VERSION ""

NS_ :

BS_:

BU_: Server VCU Body Brakes

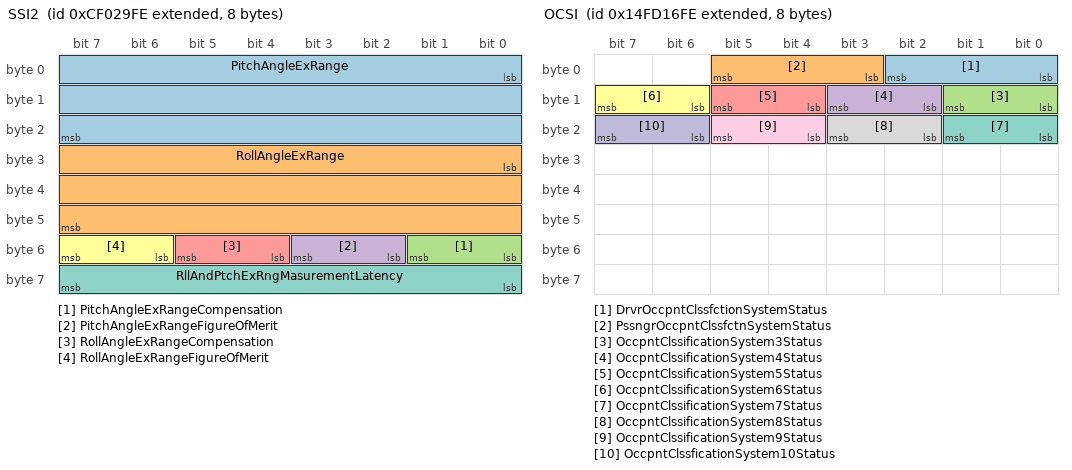
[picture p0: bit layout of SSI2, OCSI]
BO_ 2364549630 SSI2: 8 Vector__XXX
 SG_ PitchAngleExRange : 0|24@1+ (1,-250) [-250|251] "deg" Vector__XXX
 SG_ RollAngleExRange : 24|24@1+ (1,-250) [-250|251] "deg" Vector__XXX
 SG_ PitchAngleExRangeCompensation : 48|2@1+ (1,0) [0|3] "" Vector__XXX
 SG_ PitchAngleExRangeFigureOfMerit : 50|2@1+ (1,0) [0|3] "" Vector__XXX
 SG_ RollAngleExRangeCompensation : 52|2@1+ (1,0) [0|3] "" Vector__XXX
 SG_ RollAngleExRangeFigureOfMerit : 54|2@1+ (1,0) [0|3] "" Vector__XXX
 SG_ RllAndPtchExRngMasurementLatency : 56|8@1+ (0.5,0) [0|125] "ms" Vector__XXX

BO_ 2499614462 OCSI: 8 Vector__XXX
 SG_ DrvrOccpntClssfctionSystemStatus : 0|3@1+ (1,0) [0|7] "" Vector__XXX
 SG_ PssngrOccpntClssfctnSystemStatus : 3|3@1+ (1,0) [0|7] "" Vector__XXX
 SG_ OccpntClssificationSystem3Status : 8|2@1+ (1,0) [0|3] "" Vector__XXX
 SG_ OccpntClssificationSystem4Status : 10|2@1+ (1,0) [0|3] "" Vector__XXX
 SG_ OccpntClssificationSystem5Status : 12|2@1+ (1,0) [0|3] "" Vector__XXX
 SG_ OccpntClssificationSystem6Status : 14|2@1+ (1,0) [0|3] "" Vector__XXX
 SG_ OccpntClssificationSystem7Status : 16|2@1+ (1,0) [0|3] "" Vector__XXX
 SG_ OccpntClssificationSystem8Status : 18|2@1+ (1,0) [0|3] "" Vector__XXX
 SG_ OccpntClssificationSystem9Status : 20|2@1+ (1,0) [0|3] "" Vector__XXX
 SG_ OccpntClssficationSystem10Status : 22|2@1+ (1,0) [0|3] "" Vector__XXX

BO_ 2560098046 NCS: 8 Vector__XXX
 SG_ CabNoiseCtrlStatus : 0|2@1+ (1,0) [0|3] "" Vector__XXX
 SG_ CabNoiseCtrlTuningStatus : 2|4@1+ (1,0) [0|15] "" Vector__XXX

BO_ 2560163582 NC1: 8 Vector__XXX
 SG_ CabNoiseCtrlState : 0|2@1+ (1,0) [0|3] "" Vector__XXX
 SG_ CabNoiseCtrlTuningState : 2|3@1+ (1,0) [0|7] "" Vector__XXX

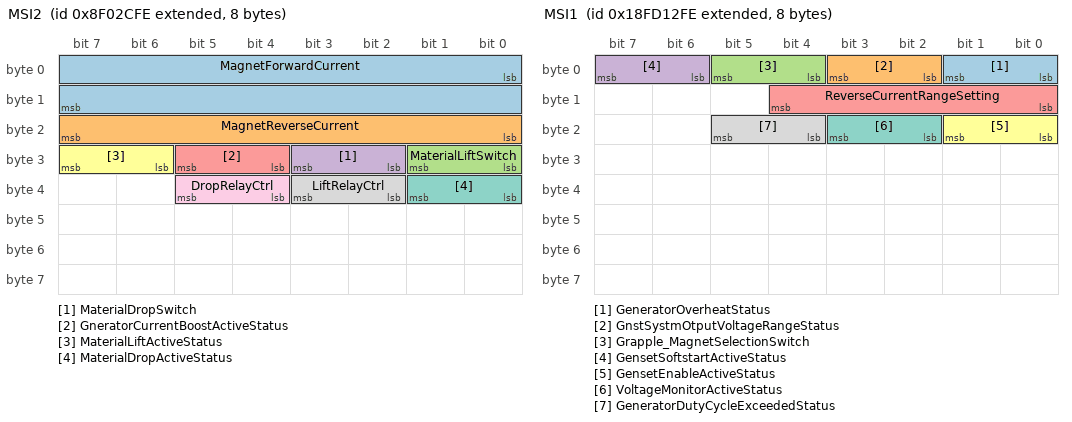
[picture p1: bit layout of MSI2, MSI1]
BO_ 2297441534 MSI2: 8 Vector__XXX
 SG_ MagnetForwardCurrent : 0|16@1+ (1,0) [0|64255] "Amps" Vector__XXX
 SG_ MagnetReverseCurrent : 16|8@1+ (1,0) [0|250] "A" Vector__XXX
 SG_ MaterialLiftSwitch : 24|2@1+ (1,0) [0|3] "" Vector__XXX
 SG_ MaterialDropSwitch : 26|2@1+ (1,0) [0|3] "" Vector__XXX
 SG_ GneratorCurrentBoostActiveStatus : 28|2@1+ (1,0) [0|3] "" Vector__XXX
 SG_ MaterialLiftActiveStatus : 30|2@1+ (1,0) [0|3] "" Vector__XXX
 SG_ MaterialDropActiveStatus : 32|2@1+ (1,0) [0|3] "" Vector__XXX
 SG_ LiftRelayCtrl : 34|2@1+ (1,0) [0|3] "" Vector__XXX
 SG_ DropRelayCtrl : 36|2@1+ (1,0) [0|3] "" Vector__XXX

BO_ 2566722302 MSI1: 8 Vector__XXX
 SG_ GeneratorOverheatStatus : 0|2@1+ (1,0) [0|3] "" Vector__XXX
 SG_ GnstSystmOtputVoltageRangeStatus : 2|2@1+ (1,0) [0|3] "" Vector__XXX
 SG_ Grapple_MagnetSelectionSwitch : 4|2@1+ (1,0) [0|3] "" Vector__XXX
 SG_ GensetSoftstartActiveStatus : 6|2@1+ (1,0) [0|3] "" Vector__XXX
 SG_ ReverseCurrentRangeSetting : 8|5@1+ (1,0) [0|31] "" Vector__XXX
 SG_ GensetEnableActiveStatus : 16|2@1+ (1,0) [0|3] "" Vector__XXX
 SG_ VoltageMonitorActiveStatus : 18|2@1+ (1,0) [0|3] "" Vector__XXX
 SG_ GeneratorDutyCycleExceededStatus : 20|2@1+ (1,0) [0|3] "" Vector__XXX

BO_ 2566722558 MSCI: 8 Vector__XXX
 SG_ MagnetBoostTime : 0|8@1+ (1,0) [0|63] "s" Vector__XXX
 SG_ MagnetRatedPower : 8|16@1+ (1,0) [0|32128] "kW" Vector__XXX

BO_ 2560032510 LVDSOM: 8 Vector__XXX
 SG_ LwVltgDscnnctDsiredOperatingMode : 0|4@1+ (1,0) [0|15] "" Vector__XXX

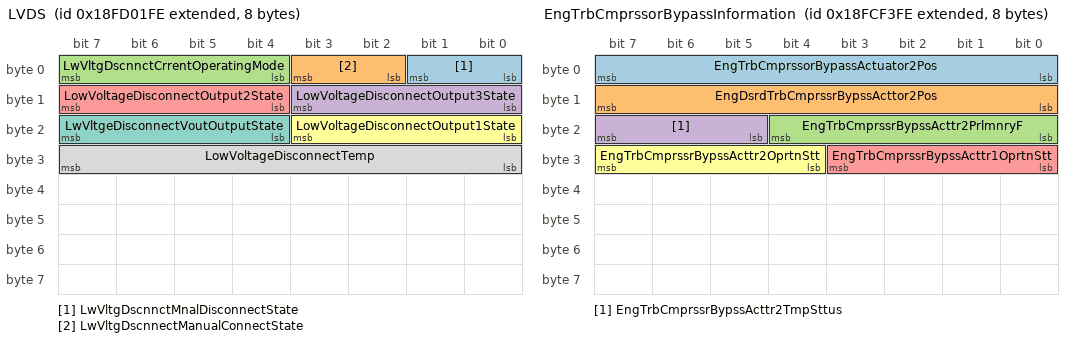
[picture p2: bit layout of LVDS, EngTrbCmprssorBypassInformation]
BO_ 2566717950 LVDS: 8 Vector__XXX
 SG_ LwVltgDscnnctMnalDisconnectState : 0|2@1+ (1,0) [0|3] "" Vector__XXX
 SG_ LwVltgDscnnectManualConnectState : 2|2@1+ (1,0) [0|3] "" Vector__XXX
 SG_ LwVltgDscnnctCrrentOperatingMode : 4|4@1+ (1,0) [0|15] "" Vector__XXX
 SG_ LowVoltageDisconnectOutput3State : 8|4@1+ (1,0) [0|15] "" Vector__XXX
 SG_ LowVoltageDisconnectOutput2State : 12|4@1+ (1,0) [0|15] "" Vector__XXX
 SG_ LowVoltageDisconnectOutput1State : 16|4@1+ (1,0) [0|15] "" Vector__XXX
 SG_ LwVltgeDisconnectVoutOutputState : 20|4@1+ (1,0) [0|15] "" Vector__XXX
 SG_ LowVoltageDisconnectTemp : 24|8@1+ (1,-40) [-40|210] "deg C" Vector__XXX

BO_ 2499604222 LLRE: 8 Vector__XXX
 SG_ BladeElevationDeviationLeft : 0|16@1+ (1,-32000) [-32000|32255] "mm" Vector__XXX
 SG_ BladeElevationDeviationRight : 16|16@1+ (1,-32000) [-32000|32255] "mm" Vector__XXX
 SG_ BldeReferenceElevationOffsetLeft : 32|16@1+ (1,-32000) [-32000|32255] "mm" Vector__XXX
 SG_ BldReferenceElevationOffsetRight : 48|16@1+ (1,-32000) [-32000|32255] "mm" Vector__XXX

BO_ 2358902526 JLCM: 8 Vector__XXX
 SG_ Joystick1Lamp1Cmd : 0|2@1+ (1,0) [0|3] "" Vector__XXX
 SG_ Joystick1Lamp2Cmd : 2|2@1+ (1,0) [0|3] "" Vector__XXX
 SG_ Joystick1Lamp3Cmd : 4|2@1+ (1,0) [0|3] "" Vector__XXX
 SG_ Joystick1Lamp4Cmd : 6|2@1+ (1,0) [0|3] "" Vector__XXX
 SG_ Joystick1Lamp5Cmd : 8|2@1+ (1,0) [0|3] "" Vector__XXX
 SG_ Joystick1Lamp6Cmd : 10|2@1+ (1,0) [0|3] "" Vector__XXX
 SG_ Joystick1Lamp7Cmd : 12|2@1+ (1,0) [0|3] "" Vector__XXX
 SG_ Joystick1Lamp8Cmd : 14|2@1+ (1,0) [0|3] "" Vector__XXX
 SG_ Joystick1Lamp9Cmd : 16|2@1+ (1,0) [0|3] "" Vector__XXX
 SG_ Joystick1Lamp10Cmd : 18|2@1+ (1,0) [0|3] "" Vector__XXX
 SG_ Joystick2Lamp1Cmd : 20|2@1+ (1,0) [0|3] "" Vector__XXX
 SG_ Joystick2Lamp2Cmd : 22|2@1+ (1,0) [0|3] "" Vector__XXX
 SG_ Joystick2Lamp3Cmd : 24|2@1+ (1,0) [0|3] "" Vector__XXX
 SG_ Joystick2Lamp4Cmd : 26|2@1+ (1,0) [0|3] "" Vector__XXX
 SG_ Joystick2Lamp5Cmd : 28|2@1+ (1,0) [0|3] "" Vector__XXX
 SG_ Joystick2Lamp6Cmd : 30|2@1+ (1,0) [0|3] "" Vector__XXX
 SG_ Joystick2Lamp7Cmd : 32|2@1+ (1,0) [0|3] "" Vector__XXX
 SG_ Joystick2Lamp8Cmd : 34|2@1+ (1,0) [0|3] "" Vector__XXX
 SG_ Joystick2Lamp9Cmd : 36|2@1+ (1,0) [0|3] "" Vector__XXX
 SG_ Joystick2Lamp10Cmd : 38|2@1+ (1,0) [0|3] "" Vector__XXX
 SG_ Joystick3Lamp1Cmd : 40|2@1+ (1,0) [0|3] "" Vector__XXX
 SG_ Joystick3Lamp2Cmd : 42|2@1+ (1,0) [0|3] "" Vector__XXX
 SG_ Joystick3Lamp3Cmd : 44|2@1+ (1,0) [0|3] "" Vector__XXX
 SG_ Joystick3Lamp4Cmd : 46|2@1+ (1,0) [0|3] "" Vector__XXX
 SG_ Joystick3Lamp5Cmd : 48|2@1+ (1,0) [0|3] "" Vector__XXX
 SG_ Joystick3Lamp6Cmd : 50|2@1+ (1,0) [0|3] "" Vector__XXX
 SG_ Joystick3Lamp7Cmd : 52|2@1+ (1,0) [0|3] "" Vector__XXX
 SG_ Joystick3Lamp8Cmd : 54|2@1+ (1,0) [0|3] "" Vector__XXX
 SG_ Joystick3Lamp9Cmd : 56|2@1+ (1,0) [0|3] "" Vector__XXX
 SG_ Joystick3Lamp10Cmd : 58|2@1+ (1,0) [0|3] "" Vector__XXX

BO_ 2566711550 IVAC: 8 Vector__XXX
 SG_ IntkVlvActtnSystmOlPrss1SlndCtrl : 0|2@1+ (1,0) [0|3] "" Vector__XXX
 SG_ IntkVlvActtnSystmOlPrss2SlndCtrl : 2|2@1+ (1,0) [0|3] "" Vector__XXX

BO_ 2633832958 ILI: 8 Vector__XXX
 SG_ DrvrArbgIgntrLp1stStgeResistance : 0|16@1+ (0.1,0) [0|6425.5] "ohm" Vector__XXX
 SG_ PssngrArbgIgntrLp1stStgRsistance : 16|16@1+ (0.1,0) [0|6425.5] "ohm" Vector__XXX
 SG_ DrvrArbgIgntrLp2ndStgeResistance : 32|16@1+ (0.1,0) [0|6425.5] "ohm" Vector__XXX
 SG_ PssngrArbgIgntrLp2ndStgRsistance : 48|16@1+ (0.1,0) [0|6425.5] "ohm" Vector__XXX
 SG_ DrvrBltTnsnrIgntorLoopResistance : 64|16@1+ (0.1,0) [0|6425.5] "ohm" Vector__XXX
 SG_ PssngrBltTnsnrIgntrLopResistance : 80|16@1+ (0.1,0) [0|6425.5] "ohm" Vector__XXX
 SG_ SdeBagIgnitorLoop1LeftResistance : 96|16@1+ (0.1,0) [0|6425.5] "ohm" Vector__XXX
 SG_ SdeBagIgnitorLoop2LeftResistance : 112|16@1+ (0.1,0) [0|6425.5] "ohm" Vector__XXX
 SG_ SdBagIgnitorLoop1RightResistance : 128|16@1+ (0.1,0) [0|6425.5] "ohm" Vector__XXX
 SG_ SdBagIgnitorLoop2RightResistance : 144|16@1+ (0.1,0) [0|6425.5] "ohm" Vector__XXX
 SG_ SpecialIgnitorLoop1Resistance : 160|16@1+ (0.1,0) [0|6425.5] "ohm" Vector__XXX
 SG_ SpecialIgnitorLoop2Resistance : 176|16@1+ (0.1,0) [0|6425.5] "ohm" Vector__XXX
 SG_ SpecialIgnitorLoop3Resistance : 192|16@1+ (0.1,0) [0|6425.5] "ohm" Vector__XXX
 SG_ SpecialIgnitorLoop4Resistance : 208|16@1+ (0.1,0) [0|6425.5] "ohm" Vector__XXX
 SG_ SpecialIgnitorLoop5Resistance : 224|16@1+ (0.1,0) [0|6425.5] "ohm" Vector__XXX
 SG_ SpecialIgnitorLoop6Resistance : 240|16@1+ (0.1,0) [0|6425.5] "ohm" Vector__XXX
 SG_ SpecialIgnitorLoop7Resistance : 256|16@1+ (0.1,0) [0|6425.5] "ohm" Vector__XXX
 SG_ SpecialIgnitorLoop8Resistance : 272|16@1+ (0.1,0) [0|6425.5] "ohm" Vector__XXX
 SG_ SpecialIgnitorLoop9Resistance : 288|16@1+ (0.1,0) [0|6425.5] "ohm" Vector__XXX
 SG_ SpecialIgnitorLoop10Resistance : 304|16@1+ (0.1,0) [0|6425.5] "ohm" Vector__XXX
 SG_ SpecialIgnitorLoop11Resistance : 320|16@1+ (0.1,0) [0|6425.5] "ohm" Vector__XXX
 SG_ SpecialIgnitorLoop12Resistance : 336|16@1+ (0.1,0) [0|6425.5] "ohm" Vector__XXX
 SG_ SpecialIgnitorLoop13Resistance : 352|16@1+ (0.1,0) [0|6425.5] "ohm" Vector__XXX
 SG_ SpecialIgnitorLoop14Resistance : 368|16@1+ (0.1,0) [0|6425.5] "ohm" Vector__XXX
 SG_ SpecialIgnitorLoop15Resistance : 384|16@1+ (0.1,0) [0|6425.5] "ohm" Vector__XXX
 SG_ SpecialIgnitorLoop16Resistance : 400|16@1+ (0.1,0) [0|6425.5] "ohm" Vector__XXX
 SG_ SpecialIgnitorLoop17Resistance : 416|16@1+ (0.1,0) [0|6425.5] "ohm" Vector__XXX
 SG_ SpecialIgnitorLoop18Resistance : 432|16@1+ (0.1,0) [0|6425.5] "ohm" Vector__XXX
 SG_ SpecialIgnitorLoop19Resistance : 448|16@1+ (0.1,0) [0|6425.5] "ohm" Vector__XXX
 SG_ SpecialIgnitorLoop20Resistance : 464|16@1+ (0.1,0) [0|6425.5] "ohm" Vector__XXX
 SG_ SpecialIgnitorLoop21Resistance : 480|16@1+ (0.1,0) [0|6425.5] "ohm" Vector__XXX
 SG_ SpecialIgnitorLoop22Resistance : 496|16@1+ (0.1,0) [0|6425.5] "ohm" Vector__XXX
 SG_ SpecialIgnitorLoop23Resistance : 512|16@1+ (0.1,0) [0|6425.5] "ohm" Vector__XXX
 SG_ SpecialIgnitorLoop24Resistance : 528|16@1+ (0.1,0) [0|6425.5] "ohm" Vector__XXX
 SG_ SpecialIgnitorLoop25Resistance : 544|16@1+ (0.1,0) [0|6425.5] "ohm" Vector__XXX
 SG_ SpecialIgnitorLoop26Resistance : 560|16@1+ (0.1,0) [0|6425.5] "ohm" Vector__XXX
 SG_ SpecialIgnitorLoop27Resistance : 576|16@1+ (0.1,0) [0|6425.5] "ohm" Vector__XXX
 SG_ SpecialIgnitorLoop28Resistance : 592|16@1+ (0.1,0) [0|6425.5] "ohm" Vector__XXX
 SG_ SpecialIgnitorLoop29Resistance : 608|16@1+ (0.1,0) [0|6425.5] "ohm" Vector__XXX
 SG_ SpecialIgnitorLoop30Resistance : 624|16@1+ (0.1,0) [0|6425.5] "ohm" Vector__XXX
 SG_ SpecialIgnitorLoop31Resistance : 640|16@1+ (0.1,0) [0|6425.5] "ohm" Vector__XXX
 SG_ SpecialIgnitorLoop32Resistance : 656|16@1+ (0.1,0) [0|6425.5] "ohm" Vector__XXX
 SG_ SpecialIgnitorLoop33Resistance : 672|16@1+ (0.1,0) [0|6425.5] "ohm" Vector__XXX
 SG_ SpecialIgnitorLoop34Resistance : 688|16@1+ (0.1,0) [0|6425.5] "ohm" Vector__XXX
 SG_ SpecialIgnitorLoop35Resistance : 704|16@1+ (0.1,0) [0|6425.5] "ohm" Vector__XXX
 SG_ SpecialIgnitorLoop36Resistance : 720|16@1+ (0.1,0) [0|6425.5] "ohm" Vector__XXX
 SG_ SpecialIgnitorLoop37Resistance : 736|16@1+ (0.1,0) [0|6425.5] "ohm" Vector__XXX
 SG_ SpecialIgnitorLoop38Resistance : 752|16@1+ (0.1,0) [0|6425.5] "ohm" Vector__XXX
 SG_ SpecialIgnitorLoop39Resistance : 768|16@1+ (0.1,0) [0|6425.5] "ohm" Vector__XXX
 SG_ SpecialIgnitorLoop40Resistance : 784|16@1+ (0.1,0) [0|6425.5] "ohm" Vector__XXX
 SG_ SpecialIgnitorLoop41Resistance : 800|16@1+ (0.1,0) [0|6425.5] "ohm" Vector__XXX
 SG_ SpecialIgnitorLoop42Resistance : 816|16@1+ (0.1,0) [0|6425.5] "ohm" Vector__XXX
 SG_ SpecialIgnitorLoop43Resistance : 832|16@1+ (0.1,0) [0|6425.5] "ohm" Vector__XXX
 SG_ SpecialIgnitorLoop44Resistance : 848|16@1+ (0.1,0) [0|6425.5] "ohm" Vector__XXX
 SG_ SpecialIgnitorLoop45Resistance : 864|16@1+ (0.1,0) [0|6425.5] "ohm" Vector__XXX
 SG_ SpecialIgnitorLoop46Resistance : 880|16@1+ (0.1,0) [0|6425.5] "ohm" Vector__XXX
 SG_ SpecialIgnitorLoop47Resistance : 896|16@1+ (0.1,0) [0|6425.5] "ohm" Vector__XXX
 SG_ SpecialIgnitorLoop48Resistance : 912|16@1+ (0.1,0) [0|6425.5] "ohm" Vector__XXX
 SG_ SpecialIgnitorLoop49Resistance : 928|16@1+ (0.1,0) [0|6425.5] "ohm" Vector__XXX
 SG_ SpecialIgnitorLoop50Resistance : 944|16@1+ (0.1,0) [0|6425.5] "ohm" Vector__XXX
 SG_ SpecialIgnitorLoop51Resistance : 960|16@1+ (0.1,0) [0|6425.5] "ohm" Vector__XXX
 SG_ SpecialIgnitorLoop52Resistance : 976|16@1+ (0.1,0) [0|6425.5] "ohm" Vector__XXX
 SG_ SpecialIgnitorLoop53Resistance : 992|16@1+ (0.1,0) [0|6425.5] "ohm" Vector__XXX
 SG_ SpecialIgnitorLoop54Resistance : 1008|16@1+ (0.1,0) [0|6425.5] "ohm" Vector__XXX
 SG_ SpecialIgnitorLoop55Resistance : 1024|16@1+ (0.1,0) [0|6425.5] "ohm" Vector__XXX
 SG_ SpecialIgnitorLoop56Resistance : 1040|16@1+ (0.1,0) [0|6425.5] "ohm" Vector__XXX
 SG_ SpecialIgnitorLoop57Resistance : 1056|16@1+ (0.1,0) [0|6425.5] "ohm" Vector__XXX
 SG_ SpecialIgnitorLoop58Resistance : 1072|16@1+ (0.1,0) [0|6425.5] "ohm" Vector__XXX
 SG_ SpecialIgnitorLoop59Resistance : 1088|16@1+ (0.1,0) [0|6425.5] "ohm" Vector__XXX
 SG_ SpecialIgnitorLoop60Resistance : 1104|16@1+ (0.1,0) [0|6425.5] "ohm" Vector__XXX
 SG_ SpecialIgnitorLoop61Resistance : 1120|16@1+ (0.1,0) [0|6425.5] "ohm" Vector__XXX
 SG_ SpecialIgnitorLoop63Resistance : 1152|16@1+ (0.1,0) [0|6425.5] "ohm" Vector__XXX
 SG_ SpecialIgnitorLoop64Resistance : 1168|16@1+ (0.1,0) [0|6425.5] "ohm" Vector__XXX
 SG_ SpecialIgnitorLoop65Resistance : 1184|16@1+ (0.1,0) [0|6425.5] "ohm" Vector__XXX
 SG_ SpecialIgnitorLoop66Resistance : 1200|16@1+ (0.1,0) [0|6425.5] "ohm" Vector__XXX
 SG_ SpecialIgnitorLoop67Resistance : 1216|16@1+ (0.1,0) [0|6425.5] "ohm" Vector__XXX
 SG_ SpecialIgnitorLoop68Resistance : 1232|16@1+ (0.1,0) [0|6425.5] "ohm" Vector__XXX
 SG_ SpecialIgnitorLoop69Resistance : 1248|16@1+ (0.1,0) [0|6425.5] "ohm" Vector__XXX
 SG_ SpecialIgnitorLoop70Resistance : 1264|16@1+ (0.1,0) [0|6425.5] "ohm" Vector__XXX
 SG_ SpecialIgnitorLoop71Resistance : 1280|16@1+ (0.1,0) [0|6425.5] "ohm" Vector__XXX
 SG_ SpecialIgnitorLoop72Resistance : 1296|16@1+ (0.1,0) [0|6425.5] "ohm" Vector__XXX
 SG_ SpecialIgnitorLoop73Resistance : 1312|16@1+ (0.1,0) [0|6425.5] "ohm" Vector__XXX
 SG_ SpecialIgnitorLoop74Resistance : 1328|16@1+ (0.1,0) [0|6425.5] "ohm" Vector__XXX
 SG_ SpecialIgnitorLoop75Resistance : 1344|16@1+ (0.1,0) [0|6425.5] "ohm" Vector__XXX
 SG_ SpecialIgnitorLoop76Resistance : 1360|16@1+ (0.1,0) [0|6425.5] "ohm" Vector__XXX
 SG_ SpecialIgnitorLoop77Resistance : 1376|16@1+ (0.1,0) [0|6425.5] "ohm" Vector__XXX
 SG_ SpecialIgnitorLoop78Resistance : 1392|16@1+ (0.1,0) [0|6425.5] "ohm" Vector__XXX
 SG_ SpecialIgnitorLoop79Resistance : 1408|16@1+ (0.1,0) [0|6425.5] "ohm" Vector__XXX
 SG_ SpecialIgnitorLoop80Resistance : 1424|16@1+ (0.1,0) [0|6425.5] "ohm" Vector__XXX
 SG_ SpecialIgnitorLoop81Resistance : 1440|16@1+ (0.1,0) [0|6425.5] "ohm" Vector__XXX
 SG_ SpecialIgnitorLoop82Resistance : 1456|16@1+ (0.1,0) [0|6425.5] "ohm" Vector__XXX
 SG_ SpecialIgnitorLoop83Resistance : 1472|16@1+ (0.1,0) [0|6425.5] "ohm" Vector__XXX
 SG_ SpecialIgnitorLoop84Resistance : 1488|16@1+ (0.1,0) [0|6425.5] "ohm" Vector__XXX
 SG_ SpecialIgnitorLoop85Resistance : 1504|16@1+ (0.1,0) [0|6425.5] "ohm" Vector__XXX
 SG_ SpecialIgnitorLoop86Resistance : 1520|16@1+ (0.1,0) [0|6425.5] "ohm" Vector__XXX
 SG_ SpecialIgnitorLoop87Resistance : 1536|16@1+ (0.1,0) [0|6425.5] "ohm" Vector__XXX
 SG_ SpecialIgnitorLoop88Resistance : 1552|16@1+ (0.1,0) [0|6425.5] "ohm" Vector__XXX
 SG_ SpecialIgnitorLoop89Resistance : 1568|16@1+ (0.1,0) [0|6425.5] "ohm" Vector__XXX
 SG_ SpecialIgnitorLoop90Resistance : 1584|16@1+ (0.1,0) [0|6425.5] "ohm" Vector__XXX

BO_ 2566719744 HRLFC: 8 Vector__XXX
 SG_ HighResolutionEngTripFuel : 0|32@1+ (0.001,0) [0|4211080] "L" Vector__XXX
 SG_ HighResolutionEngTotalFuelUsed : 32|32@1+ (0.001,0) [0|4211080] "L" Vector__XXX

BO_ 2565877502 EngTrboWastegateActuatorCtrlCmd: 8 Vector__XXX
 SG_ EngTurboWastegateActuator1Cmd : 0|16@1+ (1,0) [0|161] "%" Vector__XXX
 SG_ EngTurboWastegateActuator2Cmd : 16|16@1+ (1,0) [0|161] "%" Vector__XXX

BO_ 2566713854 EngTrbWstgteActuatorInformation: 8 Vector__XXX
 SG_ EngTrbWstgtActtor2PreliminaryFMI : 0|5@1+ (1,0) [0|31] "" Vector__XXX
 SG_ EngTrbWstgateActuator2TempStatus : 5|3@1+ (1,0) [0|7] "" Vector__XXX
 SG_ EngTrbWstgtActtr1OperationStatus : 8|4@1+ (1,0) [0|15] "" Vector__XXX
 SG_ EngTrbWstgtActtr2OperationStatus : 12|4@1+ (1,0) [0|15] "" Vector__XXX

BO_ 2566714366 EngTrbCmprssorBypassInformation: 8 Vector__XXX
 SG_ EngTrbCmprssorBypassActuator2Pos : 0|8@1+ (0.4,0) [0|100] "%" Vector__XXX
 SG_ EngDsrdTrbCmprssrBypssActtor2Pos : 8|8@1+ (1,0) [0|100] "%" Vector__XXX
 SG_ EngTrbCmprssrBypssActtr2PrlmnryF : 16|5@1+ (1,0) [0|31] "" Vector__XXX
 SG_ EngTrbCmprssrBypssActtr2TmpSttus : 21|3@1+ (1,0) [0|7] "" Vector__XXX
 SG_ EngTrbCmprssrBypssActtr1OprtnStt : 24|4@1+ (1,0) [0|15] "" Vector__XXX
 SG_ EngTrbCmprssrBypssActtr2OprtnStt : 28|4@1+ (1,0) [0|15] "" Vector__XXX

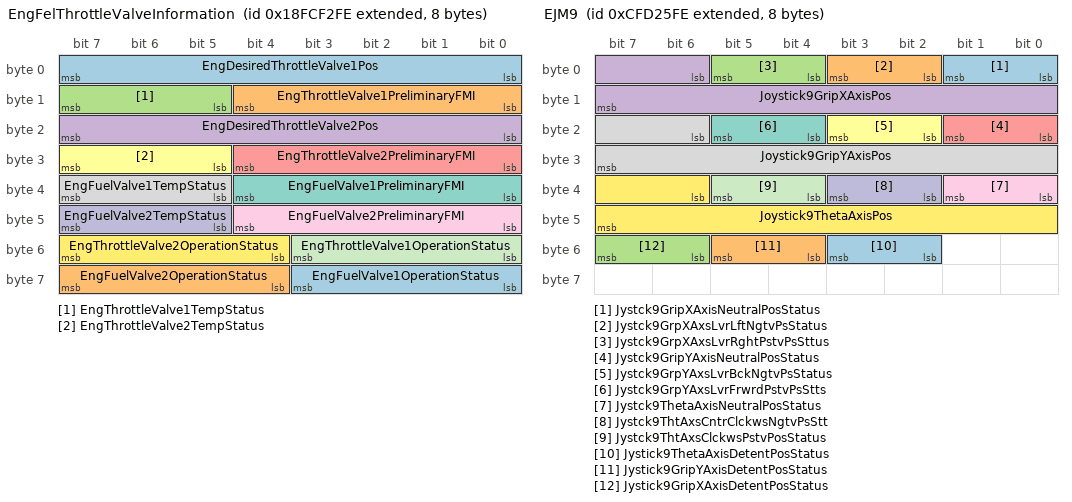
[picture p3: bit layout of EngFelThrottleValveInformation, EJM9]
BO_ 2566714110 EngFelThrottleValveInformation: 8 Vector__XXX
 SG_ EngDesiredThrottleValve1Pos : 0|8@1+ (1,0) [0|100] "%" Vector__XXX
 SG_ EngThrottleValve1PreliminaryFMI : 8|5@1+ (1,0) [0|31] "" Vector__XXX
 SG_ EngThrottleValve1TempStatus : 13|3@1+ (1,0) [0|7] "" Vector__XXX
 SG_ EngDesiredThrottleValve2Pos : 16|8@1+ (1,0) [0|100] "%" Vector__XXX
 SG_ EngThrottleValve2PreliminaryFMI : 24|5@1+ (1,0) [0|31] "" Vector__XXX
 SG_ EngThrottleValve2TempStatus : 29|3@1+ (1,0) [0|7] "" Vector__XXX
 SG_ EngFuelValve1PreliminaryFMI : 32|5@1+ (1,0) [0|31] "" Vector__XXX
 SG_ EngFuelValve1TempStatus : 37|3@1+ (1,0) [0|7] "" Vector__XXX
 SG_ EngFuelValve2PreliminaryFMI : 40|5@1+ (1,0) [0|31] "" Vector__XXX
 SG_ EngFuelValve2TempStatus : 45|3@1+ (1,0) [0|7] "" Vector__XXX
 SG_ EngThrottleValve1OperationStatus : 48|4@1+ (1,0) [0|15] "" Vector__XXX
 SG_ EngThrottleValve2OperationStatus : 52|4@1+ (1,0) [0|15] "" Vector__XXX
 SG_ EngFuelValve1OperationStatus : 56|4@1+ (1,0) [0|15] "" Vector__XXX
 SG_ EngFuelValve2OperationStatus : 60|4@1+ (1,0) [0|15] "" Vector__XXX

BO_ 2566717438 ET5: 8 Vector__XXX
 SG_ EngExhaustGasRecirculation2Temp : 0|16@1+ (0.03125,-273) [-273|1734.97] "deg C" Vector__XXX
 SG_ EngExhstGsRcrcltn2MxerIntakeTemp : 16|16@1+ (0.03125,-273) [-273|1734.97] "deg C" Vector__XXX

BO_ 2633828606 EOM: 8 Vector__XXX
 SG_ EngOilViscosity : 0|16@1+ (0.015625,0) [0|1003.98] "Cp" Vector__XXX
 SG_ EngOilDensity : 16|16@1+ (3.1E-005,0) [0|1.9919] "g/cc" Vector__XXX
 SG_ EngOilRelativeDielectricity : 32|16@1+ (0.000122,0) [0|7.83911] "" Vector__XXX

BO_ 2499607550 EMAP: 8 Vector__XXX
 SG_ EngExhstMnfldBnk1FlwBlncVlvActtr : 0|16@1+ (0.0025,0) [0|160.637] "%" Vector__XXX
 SG_ EngExhstMnfldBnk2FlwBlncVlvActtr : 16|16@1+ (0.0025,0) [0|160.637] "%" Vector__XXX

BO_ 2633825534 EMAC: 8 Vector__XXX
 SG_ EngExhstMnfldBnk1FlwBlncVlvActtr : 0|16@1+ (1,0) [0|161] "%" Vector__XXX
 SG_ EngExhstMnfldBnk2FlwBlncVlvActtr : 16|16@1+ (1,0) [0|161] "%" Vector__XXX

BO_ 2365400574 EJM9: 8 Vector__XXX
 SG_ Jystck9GripXAxisNeutralPosStatus : 0|2@1+ (1,0) [0|3] "" Vector__XXX
 SG_ Jystck9GrpXAxsLvrLftNgtvPsStatus : 2|2@1+ (1,0) [0|3] "" Vector__XXX
 SG_ Jystck9GrpXAxsLvrRghtPstvPsSttus : 4|2@1+ (1,0) [0|3] "" Vector__XXX
 SG_ Joystick9GripXAxisPos : 6|10@1+ (1,0) [0|102] "%" Vector__XXX
 SG_ Jystck9GripYAxisNeutralPosStatus : 16|2@1+ (1,0) [0|3] "" Vector__XXX
 SG_ Jystck9GrpYAxsLvrBckNgtvPsStatus : 18|2@1+ (1,0) [0|3] "" Vector__XXX
 SG_ Jystck9GrpYAxsLvrFrwrdPstvPsStts : 20|2@1+ (1,0) [0|3] "" Vector__XXX
 SG_ Joystick9GripYAxisPos : 22|10@1+ (1,0) [0|102] "%" Vector__XXX
 SG_ Jystck9ThetaAxisNeutralPosStatus : 32|2@1+ (1,0) [0|3] "" Vector__XXX
 SG_ Jystck9ThtAxsCntrClckwsNgtvPsStt : 34|2@1+ (1,0) [0|3] "" Vector__XXX
 SG_ Jystck9ThtAxsClckwsPstvPosStatus : 36|2@1+ (1,0) [0|3] "" Vector__XXX
 SG_ Joystick9ThetaAxisPos : 38|10@1+ (1,0) [0|102] "%" Vector__XXX
 SG_ Jystick9ThetaAxisDetentPosStatus : 50|2@1+ (1,0) [0|3] "" Vector__XXX
 SG_ Jystick9GripYAxisDetentPosStatus : 52|2@1+ (1,0) [0|3] "" Vector__XXX
 SG_ Jystick9GripXAxisDetentPosStatus : 54|2@1+ (1,0) [0|3] "" Vector__XXX

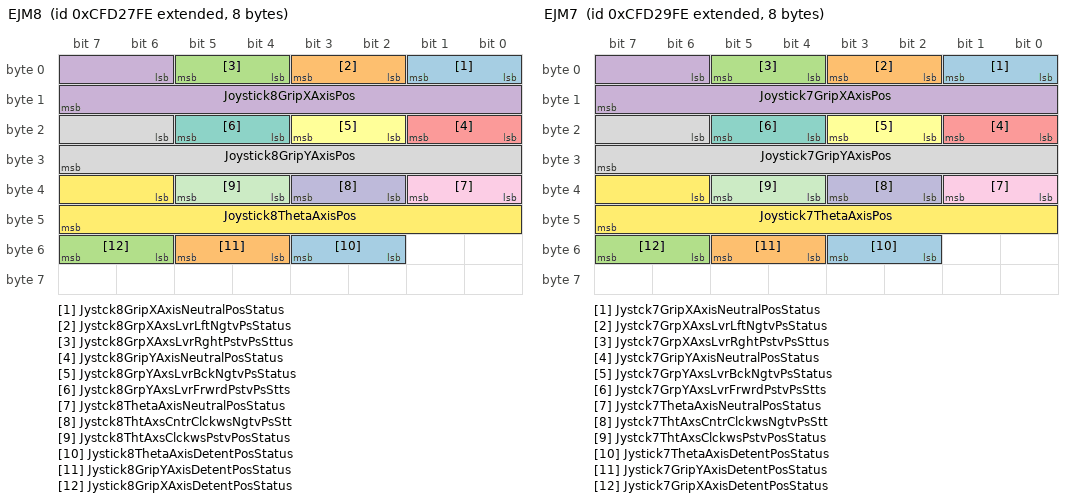
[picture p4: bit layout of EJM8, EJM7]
BO_ 2365401086 EJM8: 8 Vector__XXX
 SG_ Jystck8GripXAxisNeutralPosStatus : 0|2@1+ (1,0) [0|3] "" Vector__XXX
 SG_ Jystck8GrpXAxsLvrLftNgtvPsStatus : 2|2@1+ (1,0) [0|3] "" Vector__XXX
 SG_ Jystck8GrpXAxsLvrRghtPstvPsSttus : 4|2@1+ (1,0) [0|3] "" Vector__XXX
 SG_ Joystick8GripXAxisPos : 6|10@1+ (1,0) [0|102] "%" Vector__XXX
 SG_ Jystck8GripYAxisNeutralPosStatus : 16|2@1+ (1,0) [0|3] "" Vector__XXX
 SG_ Jystck8GrpYAxsLvrBckNgtvPsStatus : 18|2@1+ (1,0) [0|3] "" Vector__XXX
 SG_ Jystck8GrpYAxsLvrFrwrdPstvPsStts : 20|2@1+ (1,0) [0|3] "" Vector__XXX
 SG_ Joystick8GripYAxisPos : 22|10@1+ (1,0) [0|102] "%" Vector__XXX
 SG_ Jystck8ThetaAxisNeutralPosStatus : 32|2@1+ (1,0) [0|3] "" Vector__XXX
 SG_ Jystck8ThtAxsCntrClckwsNgtvPsStt : 34|2@1+ (1,0) [0|3] "" Vector__XXX
 SG_ Jystck8ThtAxsClckwsPstvPosStatus : 36|2@1+ (1,0) [0|3] "" Vector__XXX
 SG_ Joystick8ThetaAxisPos : 38|10@1+ (1,0) [0|102] "%" Vector__XXX
 SG_ Jystick8ThetaAxisDetentPosStatus : 50|2@1+ (1,0) [0|3] "" Vector__XXX
 SG_ Jystick8GripYAxisDetentPosStatus : 52|2@1+ (1,0) [0|3] "" Vector__XXX
 SG_ Jystick8GripXAxisDetentPosStatus : 54|2@1+ (1,0) [0|3] "" Vector__XXX

BO_ 2365401598 EJM7: 8 Vector__XXX
 SG_ Jystck7GripXAxisNeutralPosStatus : 0|2@1+ (1,0) [0|3] "" Vector__XXX
 SG_ Jystck7GrpXAxsLvrLftNgtvPsStatus : 2|2@1+ (1,0) [0|3] "" Vector__XXX
 SG_ Jystck7GrpXAxsLvrRghtPstvPsSttus : 4|2@1+ (1,0) [0|3] "" Vector__XXX
 SG_ Joystick7GripXAxisPos : 6|10@1+ (1,0) [0|102] "%" Vector__XXX
 SG_ Jystck7GripYAxisNeutralPosStatus : 16|2@1+ (1,0) [0|3] "" Vector__XXX
 SG_ Jystck7GrpYAxsLvrBckNgtvPsStatus : 18|2@1+ (1,0) [0|3] "" Vector__XXX
 SG_ Jystck7GrpYAxsLvrFrwrdPstvPsStts : 20|2@1+ (1,0) [0|3] "" Vector__XXX
 SG_ Joystick7GripYAxisPos : 22|10@1+ (1,0) [0|102] "%" Vector__XXX
 SG_ Jystck7ThetaAxisNeutralPosStatus : 32|2@1+ (1,0) [0|3] "" Vector__XXX
 SG_ Jystck7ThtAxsCntrClckwsNgtvPsStt : 34|2@1+ (1,0) [0|3] "" Vector__XXX
 SG_ Jystck7ThtAxsClckwsPstvPosStatus : 36|2@1+ (1,0) [0|3] "" Vector__XXX
 SG_ Joystick7ThetaAxisPos : 38|10@1+ (1,0) [0|102] "%" Vector__XXX
 SG_ Jystick7ThetaAxisDetentPosStatus : 50|2@1+ (1,0) [0|3] "" Vector__XXX
 SG_ Jystick7GripYAxisDetentPosStatus : 52|2@1+ (1,0) [0|3] "" Vector__XXX
 SG_ Jystick7GripXAxisDetentPosStatus : 54|2@1+ (1,0) [0|3] "" Vector__XXX

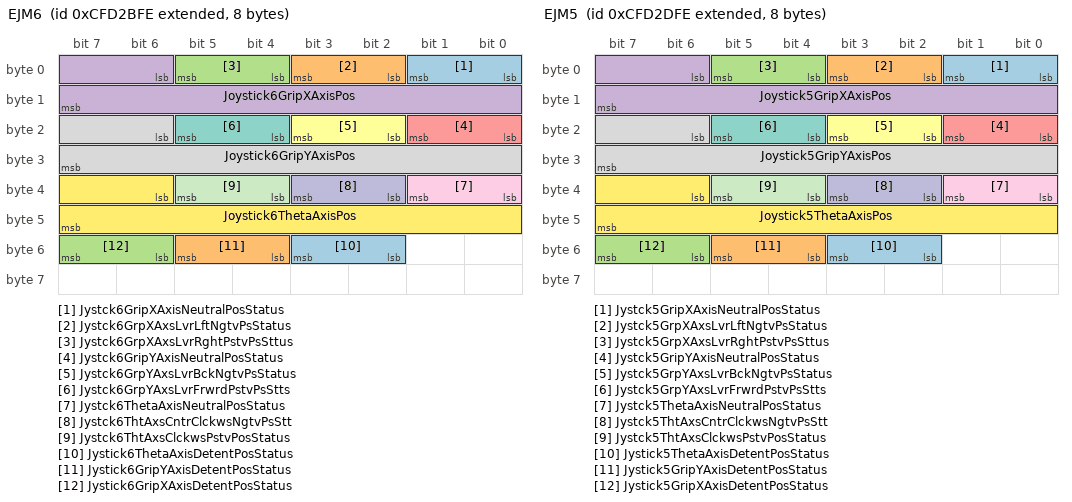
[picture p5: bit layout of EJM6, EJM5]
BO_ 2365402110 EJM6: 8 Vector__XXX
 SG_ Jystck6GripXAxisNeutralPosStatus : 0|2@1+ (1,0) [0|3] "" Vector__XXX
 SG_ Jystck6GrpXAxsLvrLftNgtvPsStatus : 2|2@1+ (1,0) [0|3] "" Vector__XXX
 SG_ Jystck6GrpXAxsLvrRghtPstvPsSttus : 4|2@1+ (1,0) [0|3] "" Vector__XXX
 SG_ Joystick6GripXAxisPos : 6|10@1+ (1,0) [0|102] "%" Vector__XXX
 SG_ Jystck6GripYAxisNeutralPosStatus : 16|2@1+ (1,0) [0|3] "" Vector__XXX
 SG_ Jystck6GrpYAxsLvrBckNgtvPsStatus : 18|2@1+ (1,0) [0|3] "" Vector__XXX
 SG_ Jystck6GrpYAxsLvrFrwrdPstvPsStts : 20|2@1+ (1,0) [0|3] "" Vector__XXX
 SG_ Joystick6GripYAxisPos : 22|10@1+ (1,0) [0|102] "%" Vector__XXX
 SG_ Jystck6ThetaAxisNeutralPosStatus : 32|2@1+ (1,0) [0|3] "" Vector__XXX
 SG_ Jystck6ThtAxsCntrClckwsNgtvPsStt : 34|2@1+ (1,0) [0|3] "" Vector__XXX
 SG_ Jystck6ThtAxsClckwsPstvPosStatus : 36|2@1+ (1,0) [0|3] "" Vector__XXX
 SG_ Joystick6ThetaAxisPos : 38|10@1+ (1,0) [0|102] "%" Vector__XXX
 SG_ Jystick6ThetaAxisDetentPosStatus : 50|2@1+ (1,0) [0|3] "" Vector__XXX
 SG_ Jystick6GripYAxisDetentPosStatus : 52|2@1+ (1,0) [0|3] "" Vector__XXX
 SG_ Jystick6GripXAxisDetentPosStatus : 54|2@1+ (1,0) [0|3] "" Vector__XXX

BO_ 2365402622 EJM5: 8 Vector__XXX
 SG_ Jystck5GripXAxisNeutralPosStatus : 0|2@1+ (1,0) [0|3] "" Vector__XXX
 SG_ Jystck5GrpXAxsLvrLftNgtvPsStatus : 2|2@1+ (1,0) [0|3] "" Vector__XXX
 SG_ Jystck5GrpXAxsLvrRghtPstvPsSttus : 4|2@1+ (1,0) [0|3] "" Vector__XXX
 SG_ Joystick5GripXAxisPos : 6|10@1+ (1,0) [0|102] "%" Vector__XXX
 SG_ Jystck5GripYAxisNeutralPosStatus : 16|2@1+ (1,0) [0|3] "" Vector__XXX
 SG_ Jystck5GrpYAxsLvrBckNgtvPsStatus : 18|2@1+ (1,0) [0|3] "" Vector__XXX
 SG_ Jystck5GrpYAxsLvrFrwrdPstvPsStts : 20|2@1+ (1,0) [0|3] "" Vector__XXX
 SG_ Joystick5GripYAxisPos : 22|10@1+ (1,0) [0|102] "%" Vector__XXX
 SG_ Jystck5ThetaAxisNeutralPosStatus : 32|2@1+ (1,0) [0|3] "" Vector__XXX
 SG_ Jystck5ThtAxsCntrClckwsNgtvPsStt : 34|2@1+ (1,0) [0|3] "" Vector__XXX
 SG_ Jystck5ThtAxsClckwsPstvPosStatus : 36|2@1+ (1,0) [0|3] "" Vector__XXX
 SG_ Joystick5ThetaAxisPos : 38|10@1+ (1,0) [0|102] "%" Vector__XXX
 SG_ Jystick5ThetaAxisDetentPosStatus : 50|2@1+ (1,0) [0|3] "" Vector__XXX
 SG_ Jystick5GripYAxisDetentPosStatus : 52|2@1+ (1,0) [0|3] "" Vector__XXX
 SG_ Jystick5GripXAxisDetentPosStatus : 54|2@1+ (1,0) [0|3] "" Vector__XXX

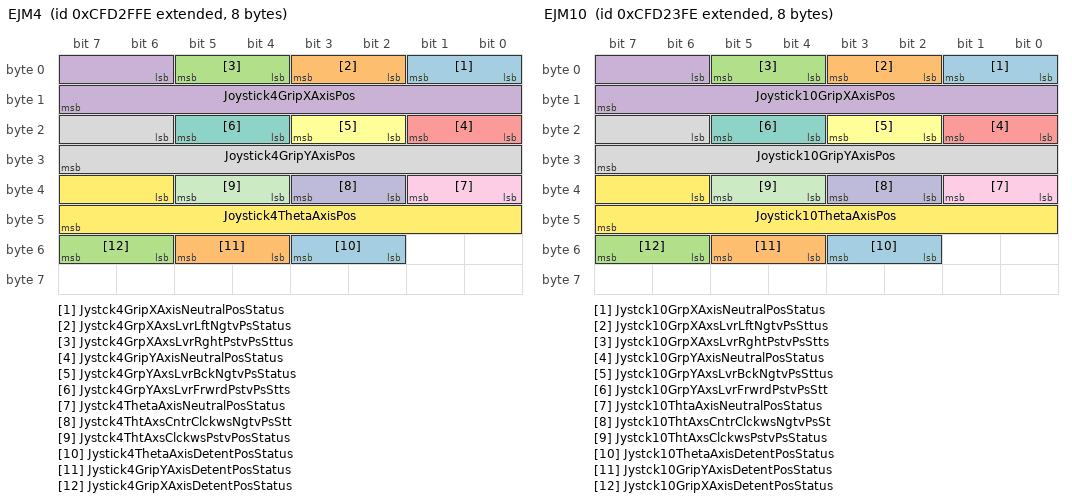
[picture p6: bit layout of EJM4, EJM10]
BO_ 2365403134 EJM4: 8 Vector__XXX
 SG_ Jystck4GripXAxisNeutralPosStatus : 0|2@1+ (1,0) [0|3] "" Vector__XXX
 SG_ Jystck4GrpXAxsLvrLftNgtvPsStatus : 2|2@1+ (1,0) [0|3] "" Vector__XXX
 SG_ Jystck4GrpXAxsLvrRghtPstvPsSttus : 4|2@1+ (1,0) [0|3] "" Vector__XXX
 SG_ Joystick4GripXAxisPos : 6|10@1+ (1,0) [0|102] "%" Vector__XXX
 SG_ Jystck4GripYAxisNeutralPosStatus : 16|2@1+ (1,0) [0|3] "" Vector__XXX
 SG_ Jystck4GrpYAxsLvrBckNgtvPsStatus : 18|2@1+ (1,0) [0|3] "" Vector__XXX
 SG_ Jystck4GrpYAxsLvrFrwrdPstvPsStts : 20|2@1+ (1,0) [0|3] "" Vector__XXX
 SG_ Joystick4GripYAxisPos : 22|10@1+ (1,0) [0|102] "%" Vector__XXX
 SG_ Jystck4ThetaAxisNeutralPosStatus : 32|2@1+ (1,0) [0|3] "" Vector__XXX
 SG_ Jystck4ThtAxsCntrClckwsNgtvPsStt : 34|2@1+ (1,0) [0|3] "" Vector__XXX
 SG_ Jystck4ThtAxsClckwsPstvPosStatus : 36|2@1+ (1,0) [0|3] "" Vector__XXX
 SG_ Joystick4ThetaAxisPos : 38|10@1+ (1,0) [0|102] "%" Vector__XXX
 SG_ Jystick4ThetaAxisDetentPosStatus : 50|2@1+ (1,0) [0|3] "" Vector__XXX
 SG_ Jystick4GripYAxisDetentPosStatus : 52|2@1+ (1,0) [0|3] "" Vector__XXX
 SG_ Jystick4GripXAxisDetentPosStatus : 54|2@1+ (1,0) [0|3] "" Vector__XXX

BO_ 2365400062 EJM10: 8 Vector__XXX
 SG_ Jystck10GrpXAxisNeutralPosStatus : 0|2@1+ (1,0) [0|3] "" Vector__XXX
 SG_ Jystck10GrpXAxsLvrLftNgtvPsSttus : 2|2@1+ (1,0) [0|3] "" Vector__XXX
 SG_ Jystck10GrpXAxsLvrRghtPstvPsStts : 4|2@1+ (1,0) [0|3] "" Vector__XXX
 SG_ Joystick10GripXAxisPos : 6|10@1+ (1,0) [0|102] "%" Vector__XXX
 SG_ Jystck10GrpYAxisNeutralPosStatus : 16|2@1+ (1,0) [0|3] "" Vector__XXX
 SG_ Jystck10GrpYAxsLvrBckNgtvPsSttus : 18|2@1+ (1,0) [0|3] "" Vector__XXX
 SG_ Jystck10GrpYAxsLvrFrwrdPstvPsStt : 20|2@1+ (1,0) [0|3] "" Vector__XXX
 SG_ Joystick10GripYAxisPos : 22|10@1+ (1,0) [0|102] "%" Vector__XXX
 SG_ Jystck10ThtaAxisNeutralPosStatus : 32|2@1+ (1,0) [0|3] "" Vector__XXX
 SG_ Jystck10ThtAxsCntrClckwsNgtvPsSt : 34|2@1+ (1,0) [0|3] "" Vector__XXX
 SG_ Jystck10ThtAxsClckwsPstvPsStatus : 36|2@1+ (1,0) [0|3] "" Vector__XXX
 SG_ Joystick10ThetaAxisPos : 38|10@1+ (1,0) [0|102] "%" Vector__XXX
 SG_ Jystck10ThetaAxisDetentPosStatus : 50|2@1+ (1,0) [0|3] "" Vector__XXX
 SG_ Jystck10GripYAxisDetentPosStatus : 52|2@1+ (1,0) [0|3] "" Vector__XXX
 SG_ Jystck10GripXAxisDetentPosStatus : 54|2@1+ (1,0) [0|3] "" Vector__XXX

BO_ 2566713598 EFS2: 8 Vector__XXX
 SG_ EngFuelFilterIntakeAbsPress : 0|8@1+ (2,0) [0|500] "kPa" Vector__XXX

BO_ 2499604478 EFL_P11: 8 Vector__XXX
 SG_ EngExhstGsRcrcltn1IntakeAbsPress : 0|16@1+ (0.1,0) [0|6425.5] "kPa" Vector__XXX
 SG_ EngExhstGsRcrcltn1OutletAbsPress : 16|16@1+ (0.1,0) [0|6425.5] "kPa" Vector__XXX

BO_ 2499608830 EFL_P10: 8 Vector__XXX
 SG_ EngExhstGsRcirculation2DiffPress : 0|16@1+ (0.007812,-250) [-250|251.96] "kPa" Vector__XXX
 SG_ EngExhstGsRcrclation2IntakePress : 16|8@1+ (2,0) [0|500] "kPa" Vector__XXX
 SG_ EngExhstGsRcrcltn2OutletAbsPress : 24|16@1+ (0.1,0) [0|6425.5] "kPa" Vector__XXX
 SG_ EngExhstGsRcrcltn2IntakeAbsPress : 40|16@1+ (0.1,0) [0|6425.5] "kPa" Vector__XXX

BO_ 2432499198 EEC9: 8 Vector__XXX
 SG_ EngExhstGsRecirculation2ValvePos : 0|16@1+ (0.0025,0) [0|160.637] "%" Vector__XXX
 SG_ EngExhstGsRcirculation2Valve2Pos : 16|16@1+ (0.0025,0) [0|160.637] "%" Vector__XXX
 SG_ CommandedEngFuelRailPress : 32|16@1+ (0.003906,0) [0|250.98] "MPa" Vector__XXX
 SG_ CmmndedEngFuelInjectionCtrlPress : 48|16@1+ (0.003906,0) [0|250.98] "MPa" Vector__XXX

BO_ 2633825022 EEC11: 8 Vector__XXX
 SG_ EngExhstGsRcirculation2ValveCtrl : 0|16@1+ (0.0025,0) [0|160.637] "%" Vector__XXX
 SG_ EngExhstGsRcrculation2Valve2Ctrl : 16|16@1+ (0.0025,0) [0|160.637] "%" Vector__XXX

BO_ 2633826046 EEC10: 8 Vector__XXX
 SG_ EngExhstGsRcrcltn2ClerIntakeTemp : 0|16@1+ (0.03125,-273) [-273|1734.97] "deg C" Vector__XXX
 SG_ EngExhstGsRcrcltn2ClrIntkGsAbsPr : 16|16@1+ (0.5,0) [0|32127.5] "kPa" Vector__XXX
 SG_ EngExhstGsRcrcltn2ClerEfficiency : 32|8@1+ (0.4,0) [0|100] "%" Vector__XXX
 SG_ EGR2CoolerBypassActuatorPos : 40|8@1+ (0.4,0) [0|100] "%" Vector__XXX

BO_ 2566711040 EC3: 8 Vector__XXX
 SG_ EngFrctnPrcentTorqueAtIdlePoint1 : 0|8@1+ (1,-125) [-125|125] "%" Vector__XXX
 SG_ EngFrctnPrcentTorqueAtIdlePoint2 : 8|8@1+ (1,-125) [-125|125] "%" Vector__XXX
 SG_ EngFrctnPrcentTorqueAtIdlePoint3 : 16|8@1+ (1,-125) [-125|125] "%" Vector__XXX
 SG_ EngFrctnPrcentTorqueAtIdlePoint4 : 24|8@1+ (1,-125) [-125|125] "%" Vector__XXX
 SG_ EngFrctnPrcentTorqueAtIdlePoint5 : 32|8@1+ (1,-125) [-125|125] "%" Vector__XXX
 SG_ EngFrctnPrcentTorqueAtIdlePoint6 : 40|8@1+ (1,-125) [-125|125] "%" Vector__XXX
 SG_ EngFrctnPrcentTorqueAtIdlePoint7 : 48|8@1+ (1,-125) [-125|125] "%" Vector__XXX

BO_ 2566749184 DPFC1: 8 Vector__XXX
 SG_ DieselParticulateFilterLampCmd : 0|3@1+ (1,0) [0|7] "" Vector__XXX
 SG_ DslPrtcltFltrPssvRgnrationStatus : 8|2@1+ (1,0) [0|3] "" Vector__XXX
 SG_ DslPrtcltFltrActvRgnrationStatus : 10|2@1+ (1,0) [0|3] "" Vector__XXX
 SG_ DieselParticulateFilterStatus : 12|3@1+ (1,0) [0|7] "" Vector__XXX
 SG_ DslPrtcltFltrActvRgnrtnInhbtdStt : 16|2@1+ (1,0) [0|3] "" Vector__XXX
 SG_ DslPrtcltFltrActvRgnrtnInhbtdDTI : 18|2@1+ (1,0) [0|3] "" Vector__XXX
 SG_ DslPrtcltFltrActvRgnrtnInhbtdDTC : 20|2@1+ (1,0) [0|3] "" Vector__XXX
 SG_ DslPrtcltFltrActvRgnrtnInhbtdDTS : 22|2@1+ (1,0) [0|3] "" Vector__XXX
 SG_ DslPrtcltFltrActvRgnrtnInhbtdDTP : 24|2@1+ (1,0) [0|3] "" Vector__XXX
 SG_ DslPrtcltFltrActvRgnrtnInhbtdDTA : 26|2@1+ (1,0) [0|3] "" Vector__XXX
 SG_ DslPrtcltFltrActvRgnrtnInhbtdDTO : 28|2@1+ (1,0) [0|3] "" Vector__XXX
 SG_ DslPrtcltFltrActvRgnrtnInhb_0002 : 30|2@1+ (1,0) [0|3] "" Vector__XXX
 SG_ DslPrtcltFltrActvRgnrtnInhb_0001 : 32|2@1+ (1,0) [0|3] "" Vector__XXX
 SG_ DslPrtcltFltrActvRgnrtnInhbtdDTL : 34|2@1+ (1,0) [0|3] "" Vector__XXX
 SG_ DslPrtcltFltrActvRgnrtnInhbtdDTS : 36|2@1+ (1,0) [0|3] "" Vector__XXX
 SG_ DslPrtcltFltrActvRgnrtnInhbtdDTS : 38|2@1+ (1,0) [0|3] "" Vector__XXX
 SG_ DslPrtcltFltrActvRgnrtnInhbtdDTT : 40|2@1+ (1,0) [0|3] "" Vector__XXX
 SG_ DslPrtcltFltrActvRgnrtnInhb_0000 : 42|2@1+ (1,0) [0|3] "" Vector__XXX
 SG_ DslPrtcltFltrActvRgnrtnInhbtdDTE : 44|2@1+ (1,0) [0|3] "" Vector__XXX
 SG_ DslPrtcltFltrActvRgnrtnInhbtdDTV : 46|2@1+ (1,0) [0|3] "" Vector__XXX
 SG_ DslPrtcltFltrAtmtcActvRgnrtnIntt : 48|2@1+ (1,0) [0|3] "" Vector__XXX
 SG_ ExhaustSystemHighTempLampCmd : 50|3@1+ (1,0) [0|7] "" Vector__XXX
 SG_ DslPrtcltFltrActvRgnrtnFrcdSttus : 53|3@1+ (1,0) [0|7] "" Vector__XXX
 SG_ HydroDoserPurgingEnable : 56|2@1+ (1,0) [0|3] "" Vector__XXX
 SG_ DslPrtclrFltrActvRgnrtnInhb_LowE : 58|2@1+ (1,0) [0|3] "" Vector__XXX
 SG_ Afttrtmt1DslParticltFltrCondiNot : 60|2@1+ (1,0) [0|3] "" Vector__XXX

BO_ 2566715646 DPF2S2: 8 Vector__XXX
 SG_ DslPrtcltFltr2StSgnlStndrdDvtion : 0|16@1+ (0.0025,0) [0|160.637] "%" Vector__XXX
 SG_ DslPrtculateFilter2SootSignalMax : 16|16@1+ (0.0025,0) [0|160.637] "%" Vector__XXX
 SG_ DslPrtculateFilter2SootSignalMin : 32|16@1+ (0.0025,0) [0|160.637] "%" Vector__XXX

BO_ 2566724606 DPF2S: 8 Vector__XXX
 SG_ DieselParticulateFilter2SootMass : 0|8@1+ (4,0) [0|1000] "g" Vector__XXX
 SG_ DslParticulateFilter2SootDensity : 8|8@1+ (0.08,0) [0|20] "g/L" Vector__XXX
 SG_ DslPrtclateFilter2MeanSootSignal : 16|16@1+ (0.0025,0) [0|160.637] "%" Vector__XXX
 SG_ DslPrtcltFilter2MedianSootSignal : 32|16@1+ (0.0025,0) [0|160.637] "%" Vector__XXX
 SG_ DslPrtcltFltr2StSnsrPrlminaryFMI : 48|5@1+ (1,0) [0|31] "" Vector__XXX

BO_ 2566715902 DPF1S2: 8 Vector__XXX
 SG_ DslPrtcltFltr1StSgnlStndrdDvtion : 0|16@1+ (0.0025,0) [0|160.637] "%" Vector__XXX
 SG_ DslPrtculateFilter1SootSignalMax : 16|16@1+ (0.0025,0) [0|160.637] "%" Vector__XXX
 SG_ DslPrtculateFilter1SootSignalMin : 32|16@1+ (0.0025,0) [0|160.637] "%" Vector__XXX

BO_ 2566724862 DPF1S: 8 Vector__XXX
 SG_ DieselParticulateFilter1SootMass : 0|8@1+ (4,0) [0|1000] "g" Vector__XXX
 SG_ DslParticulateFilter1SootDensity : 8|8@1+ (0.08,0) [0|20] "g/L" Vector__XXX
 SG_ DslPrtclateFilter1MeanSootSignal : 16|16@1+ (0.0025,0) [0|160.637] "%" Vector__XXX
 SG_ DslPrtcltFilter1MedianSootSignal : 32|16@1+ (0.0025,0) [0|160.637] "%" Vector__XXX
 SG_ DslPrtcltFltr1StSnsrPrlminaryFMI : 48|5@1+ (1,0) [0|31] "" Vector__XXX

BO_ 2566718718 DLCD2: 8 Vector__XXX
 SG_ VehicleBatteryVoltageLowLampData : 0|2@1+ (1,0) [0|3] "" Vector__XXX
 SG_ VehicleFuelLevelLowLampData : 2|2@1+ (1,0) [0|3] "" Vector__XXX
 SG_ VehicleAirPressLowLampData : 4|2@1+ (1,0) [0|3] "" Vector__XXX
 SG_ VehicleHVACRecirculationLampData : 6|2@1+ (1,0) [0|3] "" Vector__XXX
 SG_ VehicleBatteryChargingLampData : 8|2@1+ (1,0) [0|3] "" Vector__XXX

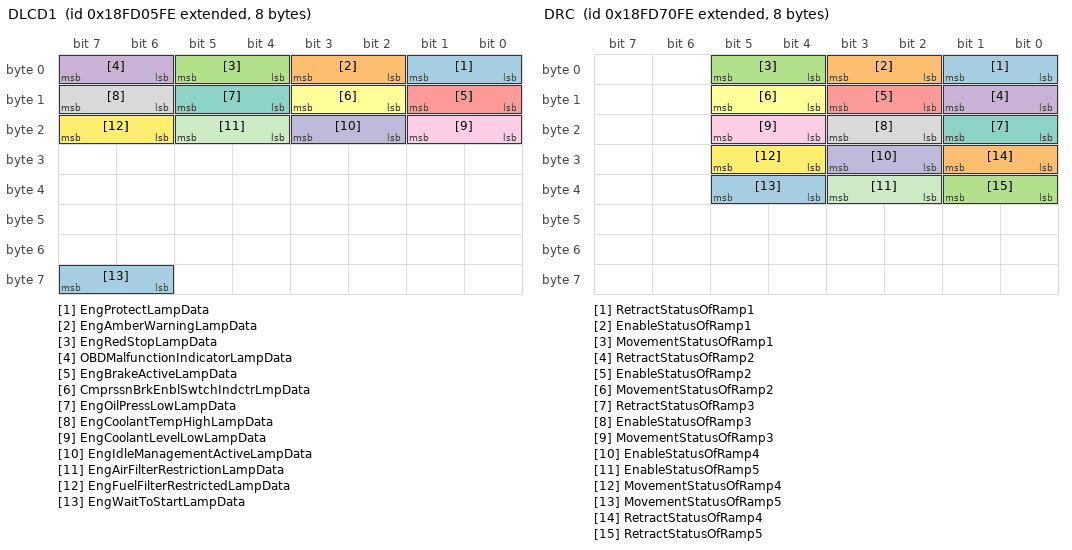
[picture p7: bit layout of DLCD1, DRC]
BO_ 2566718974 DLCD1: 8 Vector__XXX
 SG_ EngProtectLampData : 0|2@1+ (1,0) [0|3] "" Vector__XXX
 SG_ EngAmberWarningLampData : 2|2@1+ (1,0) [0|3] "" Vector__XXX
 SG_ EngRedStopLampData : 4|2@1+ (1,0) [0|3] "" Vector__XXX
 SG_ OBDMalfunctionIndicatorLampData : 6|2@1+ (1,0) [0|3] "" Vector__XXX
 SG_ EngBrakeActiveLampData : 8|2@1+ (1,0) [0|3] "" Vector__XXX
 SG_ CmprssnBrkEnblSwtchIndctrLmpData : 10|2@1+ (1,0) [0|3] "" Vector__XXX
 SG_ EngOilPressLowLampData : 12|2@1+ (1,0) [0|3] "" Vector__XXX
 SG_ EngCoolantTempHighLampData : 14|2@1+ (1,0) [0|3] "" Vector__XXX
 SG_ EngCoolantLevelLowLampData : 16|2@1+ (1,0) [0|3] "" Vector__XXX
 SG_ EngIdleManagementActiveLampData : 18|2@1+ (1,0) [0|3] "" Vector__XXX
 SG_ EngAirFilterRestrictionLampData : 20|2@1+ (1,0) [0|3] "" Vector__XXX
 SG_ EngFuelFilterRestrictedLampData : 22|2@1+ (1,0) [0|3] "" Vector__XXX
 SG_ EngWaitToStartLampData : 62|2@1+ (1,0) [0|3] "" Vector__XXX

BO_ 2566719230 DLCC2: 8 Vector__XXX
 SG_ VehicleBatteryVoltageLowLampCmd : 0|2@1+ (1,0) [0|3] "" Vector__XXX
 SG_ VehicleFuelLevelLowLampCmd : 2|2@1+ (1,0) [0|3] "" Vector__XXX
 SG_ VehicleAirPressLowLampCmd : 4|2@1+ (1,0) [0|3] "" Vector__XXX
 SG_ VehicleHVACRecirculationLampCmd : 6|2@1+ (1,0) [0|3] "" Vector__XXX
 SG_ VehicleBatteryChargingLampCmd : 8|2@1+ (1,0) [0|3] "" Vector__XXX

BO_ 2560818942 DM32: 8 Vector__XXX
 SG_ SPN1 : 0|16@1+ (1,0) [0|65535] "" Vector__XXX
 SG_ SPN1High : 21|3@1+ (1,0) [0|7] "" Vector__XXX
 SG_ FailureModeIdentifier1 : 16|5@1+ (1,0) [0|31] "" Vector__XXX
 SG_ DTCTotalActiveTime : 24|16@1+ (0.2,0) [0|12851] "hr" Vector__XXX
 SG_ DTCTotalPreviouslyActiveTime : 40|16@1+ (0.2,0) [0|12851] "hr" Vector__XXX
 SG_ DTCTimeUntilDerate : 56|8@1+ (0.25,0) [0|62.5] "hr" Vector__XXX

BO_ 2561212158 DISP1: 8 Vector__XXX
 SG_ TextDisplayInstructions : 0|4@1+ (1,0) [0|15] "" Vector__XXX
 SG_ TextDisplayIndex : 16|8@1+ (1,0) [0|250] "" Vector__XXX

BO_ 2566746366 DRC: 8 Vector__XXX
 SG_ RetractStatusOfRamp1 : 0|2@1+ (1,0) [0|3] "" Vector__XXX
 SG_ EnableStatusOfRamp1 : 2|2@1+ (1,0) [0|3] "" Vector__XXX
 SG_ MovementStatusOfRamp1 : 4|2@1+ (1,0) [0|3] "" Vector__XXX
 SG_ RetractStatusOfRamp2 : 8|2@1+ (1,0) [0|3] "" Vector__XXX
 SG_ EnableStatusOfRamp2 : 10|2@1+ (1,0) [0|3] "" Vector__XXX
 SG_ MovementStatusOfRamp2 : 12|2@1+ (1,0) [0|3] "" Vector__XXX
 SG_ RetractStatusOfRamp3 : 16|2@1+ (1,0) [0|3] "" Vector__XXX
 SG_ EnableStatusOfRamp3 : 18|2@1+ (1,0) [0|3] "" Vector__XXX
 SG_ MovementStatusOfRamp3 : 20|2@1+ (1,0) [0|3] "" Vector__XXX
 SG_ EnableStatusOfRamp4 : 26|2@1+ (1,0) [0|3] "" Vector__XXX
 SG_ EnableStatusOfRamp5 : 34|2@1+ (1,0) [0|3] "" Vector__XXX
 SG_ MovementStatusOfRamp4 : 28|2@1+ (1,0) [0|3] "" Vector__XXX
 SG_ MovementStatusOfRamp5 : 36|2@1+ (1,0) [0|3] "" Vector__XXX
 SG_ RetractStatusOfRamp4 : 24|2@1+ (1,0) [0|3] "" Vector__XXX
 SG_ RetractStatusOfRamp5 : 32|2@1+ (1,0) [0|3] "" Vector__XXX

BO_ 2566750206 EC2: 8 Vector__XXX
 SG_ MaxCrankAttemptsPerStartAttempt : 0|8@1+ (1,0) [0|250] "" Vector__XXX

BO_ 2566755582 EEC7: 8 Vector__XXX
 SG_ EngExhstGsRecirculation1ValvePos : 0|16@1+ (0.0025,0) [0|160.637] "%" Vector__XXX
 SG_ EngExhstGsRcirculation1Valve2Pos : 16|16@1+ (0.0025,0) [0|160.637] "%" Vector__XXX
 SG_ EngCrnkcsBrtherOilSeparatorSpeed : 32|16@1+ (1,0) [0|64255] "rpm" Vector__XXX
 SG_ CommandedEngIntakeManifoldPress : 48|16@1+ (0.125,0) [0|8031.88] "kPa" Vector__XXX

BO_ 2566746110 EEC8: 8 Vector__XXX
 SG_ EngExhstGsRcrculation1Valve2Ctrl : 0|16@1+ (1,0) [0|161] "%" Vector__XXX
 SG_ EngExhstGsRcrcltn1ClerEfficiency : 48|8@1+ (1,0) [0|100] "%" Vector__XXX
 SG_ EngExhstGsRcrcltn1ClerIntakeTemp : 16|16@1+ (0.03125,-273) [-273|1734.97] "deg C" Vector__XXX
 SG_ EngExhstGsRcrcltn1ClrIntkGsAbsPr : 32|16@1+ (0.5,0) [0|32127.5] "kPa" Vector__XXX

BO_ 2566752510 EFL_P5: 8 Vector__XXX
 SG_ EngIntkVlvActtionOilPressForCyl1 : 0|16@1+ (0.1,0) [0|6425.5] "kPa" Vector__XXX
 SG_ EngIntkVlvActtionOilPressForCyl2 : 16|16@1+ (0.1,0) [0|6425.5] "kPa" Vector__XXX
 SG_ EngIntkVlvActtionOilPressForCyl3 : 32|16@1+ (0.1,0) [0|6425.5] "kPa" Vector__XXX
 SG_ EngIntkVlvActtionOilPressForCyl4 : 48|16@1+ (0.1,0) [0|6425.5] "kPa" Vector__XXX

BO_ 2566752254 EFL_P6: 8 Vector__XXX
 SG_ EngIntkVlvActtionOilPressForCyl5 : 0|16@1+ (0.1,0) [0|6425.5] "kPa" Vector__XXX
 SG_ EngIntkVlvActtionOilPressForCyl6 : 16|16@1+ (0.1,0) [0|6425.5] "kPa" Vector__XXX
 SG_ EngIntkVlvActtionOilPressForCyl7 : 32|16@1+ (0.1,0) [0|6425.5] "kPa" Vector__XXX
 SG_ EngIntkVlvActtionOilPressForCyl8 : 48|16@1+ (0.1,0) [0|6425.5] "kPa" Vector__XXX

BO_ 2566751998 EFL_P7: 8 Vector__XXX
 SG_ EngIntkVlvActtionOilPressForCyl9 : 0|16@1+ (0.1,0) [0|6425.5] "kPa" Vector__XXX
 SG_ EngIntkVlvActtonOilPressForCyl10 : 16|16@1+ (0.1,0) [0|6425.5] "kPa" Vector__XXX
 SG_ EngIntkVlvActtonOilPressForCyl11 : 32|16@1+ (0.1,0) [0|6425.5] "kPa" Vector__XXX
 SG_ EngIntkVlvActtonOilPressForCyl12 : 48|16@1+ (0.1,0) [0|6425.5] "kPa" Vector__XXX

BO_ 2566751742 EFL_P8: 8 Vector__XXX
 SG_ EngIntkVlvActtonOilPressForCyl13 : 0|16@1+ (0.1,0) [0|6425.5] "kPa" Vector__XXX
 SG_ EngIntkVlvActtonOilPressForCyl14 : 16|16@1+ (0.1,0) [0|6425.5] "kPa" Vector__XXX
 SG_ EngIntkVlvActtonOilPressForCyl15 : 32|16@1+ (0.1,0) [0|6425.5] "kPa" Vector__XXX
 SG_ EngIntkVlvActtonOilPressForCyl16 : 48|16@1+ (0.1,0) [0|6425.5] "kPa" Vector__XXX

BO_ 2566751486 EFL_P9: 8 Vector__XXX
 SG_ EngIntkVlvActtonOilPressForCyl17 : 0|16@1+ (0.1,0) [0|6425.5] "kPa" Vector__XXX
 SG_ EngIntkVlvActtonOilPressForCyl18 : 16|16@1+ (0.1,0) [0|6425.5] "kPa" Vector__XXX
 SG_ EngIntkVlvActtonOilPressForCyl19 : 32|16@1+ (0.1,0) [0|6425.5] "kPa" Vector__XXX
 SG_ EngIntkVlvActtonOilPressForCyl20 : 48|16@1+ (0.1,0) [0|6425.5] "kPa" Vector__XXX

BO_ 2499641854 EGRBV: 8 Vector__XXX
 SG_ EGR1CoolerBypassActuatorPostion : 0|8@1+ (0.4,0) [0|100] "%" Vector__XXX

BO_ 2566748158 ESV1: 8 Vector__XXX
 SG_ EngSparkPlug1 : 0|16@1+ (1,0) [0|64255] "Volts" Vector__XXX
 SG_ EngSparkPlug2 : 16|16@1+ (1,0) [0|64255] "Volts" Vector__XXX
 SG_ EngSparkPlug3 : 32|16@1+ (1,0) [0|64255] "Volts" Vector__XXX
 SG_ EngSparkPlug4 : 48|16@1+ (1,0) [0|64255] "Volts" Vector__XXX

BO_ 2566747902 ESV2: 8 Vector__XXX
 SG_ EngSparkPlug5 : 0|16@1+ (1,0) [0|64255] "Volts" Vector__XXX
 SG_ EngSparkPlug6 : 16|16@1+ (1,0) [0|64255] "Volts" Vector__XXX
 SG_ EngSparkPlug7 : 32|16@1+ (1,0) [0|64255] "Volts" Vector__XXX
 SG_ EngSparkPlug8 : 48|16@1+ (1,0) [0|64255] "Volts" Vector__XXX

BO_ 2566747646 ESV3: 8 Vector__XXX
 SG_ EngSparkPlug9 : 0|16@1+ (1,0) [0|64255] "Volts" Vector__XXX
 SG_ EngSparkPlug10 : 16|16@1+ (1,0) [0|64255] "Volts" Vector__XXX
 SG_ EngSparkPlug11 : 32|16@1+ (1,0) [0|64255] "Volts" Vector__XXX
 SG_ EngSparkPlug12 : 48|16@1+ (1,0) [0|64255] "Volts" Vector__XXX

BO_ 2566747390 ESV4: 8 Vector__XXX
 SG_ EngSparkPlug13 : 0|16@1+ (1,0) [0|64255] "Volts" Vector__XXX
 SG_ EngSparkPlug14 : 16|16@1+ (1,0) [0|64255] "Volts" Vector__XXX
 SG_ EngSparkPlug15 : 32|16@1+ (1,0) [0|64255] "Volts" Vector__XXX
 SG_ EngSparkPlug16 : 48|16@1+ (1,0) [0|64255] "Volts" Vector__XXX

BO_ 2566747134 ESV5: 8 Vector__XXX
 SG_ EngSparkPlug17 : 0|16@1+ (1,0) [0|64255] "Volts" Vector__XXX
 SG_ EngSparkPlug18 : 16|16@1+ (1,0) [0|64255] "Volts" Vector__XXX
 SG_ EngSparkPlug19 : 32|16@1+ (1,0) [0|64255] "Volts" Vector__XXX
 SG_ EngSparkPlug20 : 48|16@1+ (1,0) [0|64255] "Volts" Vector__XXX

BO_ 2566746878 ESV6: 8 Vector__XXX
 SG_ EngSparkPlug21 : 0|16@1+ (1,0) [0|64255] "Volts" Vector__XXX
 SG_ EngSparkPlug22 : 16|16@1+ (1,0) [0|64255] "Volts" Vector__XXX
 SG_ EngSparkPlug23 : 32|16@1+ (1,0) [0|64255] "Volts" Vector__XXX
 SG_ EngSparkPlug24 : 48|16@1+ (1,0) [0|64255] "Volts" Vector__XXX

BO_ 2561277694 FLIC: 8 Vector__XXX
 SG_ LaneDepartureWarningEnableCmd : 0|2@1+ (1,0) [0|3] "" Vector__XXX

BO_ 2633861886 J2012: 8 Vector__XXX
 SG_ NumberOfJ2012DTCs : 0|8@1+ (1,0) [0|250] "" Vector__XXX
 SG_ J2012DTC : 8|40@1+ (1,0) [0|255] "per byte" Vector__XXX
 SG_ J2012DTCStatus : 48|1@1- (1,0) [0|1] "" Vector__XXX
 SG_ J2012DTCOccurrenceCount : 49|7@1+ (1,0) [0|127] "" Vector__XXX

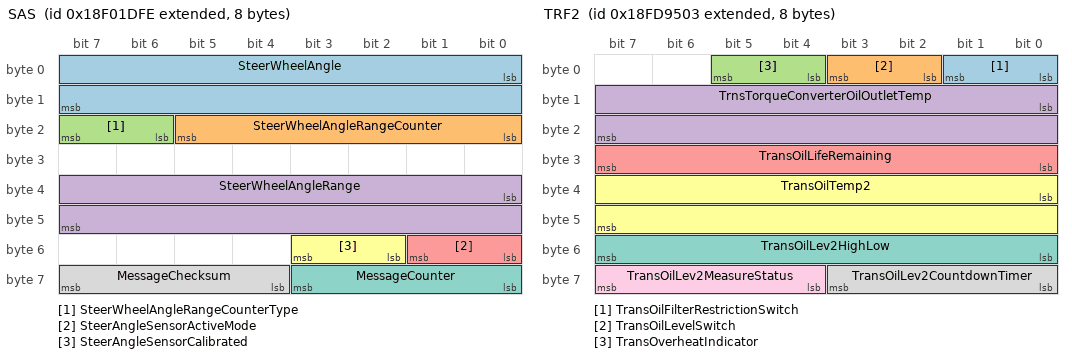
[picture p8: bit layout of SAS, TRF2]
BO_ 2565873150 SAS: 8 Vector__XXX
 SG_ SteerWheelAngle : 0|16@1+ (0.000977,-31.374) [-31.374|31.4031] "rad" Vector__XXX
 SG_ SteerWheelAngleRangeCounter : 16|6@1+ (1,-32) [-32|29] "ranges" Vector__XXX
 SG_ SteerWheelAngleRangeCounterType : 22|2@1+ (1,0) [0|3] "" Vector__XXX
 SG_ SteerWheelAngleRange : 32|16@1+ (0.000977,-31.374) [-31.374|31.4031] "rad" Vector__XXX
 SG_ SteerAngleSensorActiveMode : 48|2@1+ (1,0) [0|3] "" Vector__XXX
 SG_ SteerAngleSensorCalibrated : 50|2@1+ (1,0) [0|3] "" Vector__XXX
 SG_ MessageCounter : 56|4@1+ (1,0) [0|15] "" Vector__XXX
 SG_ MessageChecksum : 60|4@1+ (1,0) [0|15] "" Vector__XXX

BO_ 2566745854 SCR1: 8 Vector__XXX
 SG_ Aftrtrtmnt1DslExhstFldTnkLwLvlIn : 40|16@1+ (1,0) [0|64255] "km" Vector__XXX
 SG_ Aftrtrtmnt1SCRAvrgCtlystRgntCnsm : 0|16@1+ (0.05,0) [0|3212.75] "L/h" Vector__XXX
 SG_ Aftrtrtmnt1SCRCmmnddCtlystRgntCn : 16|16@1+ (1,0) [0|3213] "L/h" Vector__XXX
 SG_ Aftrtrtmnt1SCRCtlystCnvrsnEffcnc : 32|8@1+ (0.4,0) [0|100] "%" Vector__XXX

BO_ 2566751230 TCI: 8 Vector__XXX
 SG_ TransferCaseStatus : 0|3@1+ (1,0) [0|7] "" Vector__XXX

BO_ 2566755587 TRF2: 8 Vector__XXX
 SG_ TransOilFilterRestrictionSwitch : 0|2@1+ (1,0) [0|3] "" Vector__XXX
 SG_ TransOilLevelSwitch : 2|2@1+ (1,0) [0|3] "" Vector__XXX
 SG_ TransOverheatIndicator : 4|2@1+ (1,0) [0|3] "" Vector__XXX
 SG_ TrnsTorqueConverterOilOutletTemp : 8|16@1+ (0.03125,-273) [-273|1734.97] "deg C" Vector__XXX
 SG_ TransOilLifeRemaining : 24|8@1+ (0.4,0) [0|100] "%" Vector__XXX
 SG_ TransOilTemp2 : 32|16@1+ (0.03125,-273) [-273|1734.97] "degC" Vector__XXX
 SG_ TransOilLev2HighLow : 48|8@1- (0.5,-62.5) [-62.5|-0.5] "L" Vector__XXX
 SG_ TransOilLev2CountdownTimer : 56|4@1+ (1,0) [0|15] "min" Vector__XXX
 SG_ TransOilLev2MeasureStatus : 60|4@1+ (1,0) [0|15] "" Vector__XXX

BO_ 2566752766 VDS2: 8 Vector__XXX
 SG_ VehicleRoll : 0|16@1+ (0.007812,-200) [-200|301.96] "deg" Vector__XXX

BO_ 2566799614 LD: 8 Vector__XXX
 SG_ RunningLight : 0|2@1+ (1,0) [0|3] "" Vector__XXX
 SG_ AltBeamHeadLightData : 2|2@1+ (1,0) [0|3] "" Vector__XXX
 SG_ LowBeamHeadLightData : 4|2@1+ (1,0) [0|3] "" Vector__XXX
 SG_ HighBeamHeadLightData : 6|2@1+ (1,0) [0|3] "" Vector__XXX
 SG_ TractorFrontFogLights : 8|2@1+ (1,0) [0|3] "" Vector__XXX
 SG_ RotatingBeaconLight : 10|2@1+ (1,0) [0|3] "" Vector__XXX
 SG_ RightTurnSignalLights : 12|2@1+ (1,0) [0|3] "" Vector__XXX
 SG_ LeftTurnSignalLights : 14|2@1+ (1,0) [0|3] "" Vector__XXX
 SG_ BackUpLightAndAlarmHorn : 16|2@1+ (1,0) [0|3] "" Vector__XXX
 SG_ CenterStopLight : 18|2@1+ (1,0) [0|3] "" Vector__XXX
 SG_ RightStopLight : 20|2@1+ (1,0) [0|3] "" Vector__XXX
 SG_ LeftStopLight : 22|2@1+ (1,0) [0|3] "" Vector__XXX
 SG_ ImplementClearanceLight : 24|2@1+ (1,0) [0|3] "" Vector__XXX
 SG_ TractorClearanceLight : 26|2@1+ (1,0) [0|3] "" Vector__XXX
 SG_ ImplementMarkerLight : 28|2@1+ (1,0) [0|3] "" Vector__XXX
 SG_ TractorMarkerLight : 30|2@1+ (1,0) [0|3] "" Vector__XXX
 SG_ RearFogLights : 32|2@1+ (1,0) [0|3] "" Vector__XXX
 SG_ TrctorUndersideMountedWorkLights : 34|2@1+ (1,0) [0|3] "" Vector__XXX
 SG_ TractorRearLowMountedWorkLights : 36|2@1+ (1,0) [0|3] "" Vector__XXX
 SG_ TractorRearHighMountedWorkLights : 38|2@1+ (1,0) [0|3] "" Vector__XXX
 SG_ TractorSideLowMountedWorkLights : 40|2@1+ (1,0) [0|3] "" Vector__XXX
 SG_ TractorSideHighMountedWorkLights : 42|2@1+ (1,0) [0|3] "" Vector__XXX
 SG_ TractorFrontLowMountedWorkLights : 44|2@1+ (1,0) [0|3] "" Vector__XXX
 SG_ TrctorFrontHighMountedWorkLights : 46|2@1+ (1,0) [0|3] "" Vector__XXX
 SG_ ImplementOEMOption2Light : 48|2@1+ (1,0) [0|3] "" Vector__XXX
 SG_ ImplementOEMOption1Light : 50|2@1+ (1,0) [0|3] "" Vector__XXX
 SG_ ImplementRightFacingWorkLight : 52|2@1+ (1,0) [0|3] "" Vector__XXX
 SG_ ImplementLeftFacingWorkLight : 54|2@1+ (1,0) [0|3] "" Vector__XXX
 SG_ ImplementRightForwardWorkLight : 58|2@1+ (1,0) [0|3] "" Vector__XXX
 SG_ ImplementLeftForwardWorkLight : 60|2@1+ (1,0) [0|3] "" Vector__XXX
 SG_ ImplementRearWorkLight : 62|2@1+ (1,0) [0|3] "" Vector__XXX

BO_ 2365473073 LCMD: 8 Vector__XXX
 SG_ RunningLightCmd : 0|2@1+ (1,0) [0|3] "" Vector__XXX
 SG_ AltBeamHeadLightCmd : 2|2@1+ (1,0) [0|3] "" Vector__XXX
 SG_ LowBeamHeadLightCmd : 4|2@1+ (1,0) [0|3] "" Vector__XXX
 SG_ HighBeamHeadLightCmd : 6|2@1+ (1,0) [0|3] "" Vector__XXX
 SG_ TractorFrontFogLightsCmd : 8|2@1+ (1,0) [0|3] "" Vector__XXX
 SG_ RotatingBeaconLightCmd : 10|2@1+ (1,0) [0|3] "" Vector__XXX
 SG_ RightTurnSignalLightsCmd : 12|2@1+ (1,0) [0|3] "" Vector__XXX
 SG_ LeftTurnSignalLightsCmd : 14|2@1+ (1,0) [0|3] "" Vector__XXX
 SG_ BackUpLightAndAlarmHornCmd : 16|2@1+ (1,0) [0|3] "" Vector__XXX
 SG_ CenterStopLightCmd : 18|2@1+ (1,0) [0|3] "" Vector__XXX
 SG_ RightStopLightCmd : 20|2@1+ (1,0) [0|3] "" Vector__XXX
 SG_ LeftStopLightCmd : 22|2@1+ (1,0) [0|3] "" Vector__XXX
 SG_ ImplementClearanceLightCmd : 24|2@1+ (1,0) [0|3] "" Vector__XXX
 SG_ TractorClearanceLightCmd : 26|2@1+ (1,0) [0|3] "" Vector__XXX
 SG_ ImplementMarkerLightCmd : 28|2@1+ (1,0) [0|3] "" Vector__XXX
 SG_ TractorMarkerLightCmd : 30|2@1+ (1,0) [0|3] "" Vector__XXX
 SG_ RearFogLightCmd : 32|2@1+ (1,0) [0|3] "" Vector__XXX
 SG_ TrctrUndrsdeMountedWorkLightsCmd : 34|2@1+ (1,0) [0|3] "" Vector__XXX
 SG_ TrctrRearLowMountedWorkLightsCmd : 36|2@1+ (1,0) [0|3] "" Vector__XXX
 SG_ TrctrRarHighMountedWorkLightsCmd : 38|2@1+ (1,0) [0|3] "" Vector__XXX
 SG_ TrctrSideLowMountedWorkLightsCmd : 40|2@1+ (1,0) [0|3] "" Vector__XXX
 SG_ TrctrSdeHighMountedWorkLightsCmd : 42|2@1+ (1,0) [0|3] "" Vector__XXX
 SG_ TrctrFrntLowMountedWorkLightsCmd : 44|2@1+ (1,0) [0|3] "" Vector__XXX
 SG_ TrctrFrntHghMountedWorkLightsCmd : 46|2@1+ (1,0) [0|3] "" Vector__XXX
 SG_ ImplementOEMOption2LightCmd : 48|2@1+ (1,0) [0|3] "" Vector__XXX
 SG_ ImplementOEMOption1LightCmd : 50|2@1+ (1,0) [0|3] "" Vector__XXX
 SG_ ImplementRightFacingWorkLightCmd : 52|2@1+ (1,0) [0|3] "" Vector__XXX
 SG_ ImplementLeftFacingWorkLightCmd : 54|2@1+ (1,0) [0|3] "" Vector__XXX
 SG_ LightingDataRqCmd : 56|2@1+ (1,0) [0|3] "" Vector__XXX
 SG_ ImplmentRightForwardWorkLightCmd : 58|2@1+ (1,0) [0|3] "" Vector__XXX
 SG_ ImplementLeftForwardWorkLightCmd : 60|2@1+ (1,0) [0|3] "" Vector__XXX
 SG_ ImplementRearWorkLightCmd : 62|2@1+ (1,0) [0|3] ""  VCU

BO_ 2365485822 LBC: 8 Vector__XXX
 SG_ BladeDurationAndDirection : 0|16@1+ (1,-3276.8) [-3276.8|3149.2] "sec" Vector__XXX
 SG_ BladeCtrlMode : 16|8@1+ (1,0) [0|255] "" Vector__XXX
 SG_ BladeCtrlModeLeft : 24|4@1+ (1,0) [0|15] "" Vector__XXX
 SG_ BladeCtrlModeRight : 28|4@1+ (1,0) [0|15] "" Vector__XXX
 SG_ LandLevelingSystemEnableStatus : 32|2@1+ (1,0) [0|3] "" Vector__XXX

BO_ 2633926654 IT6: 8 Vector__XXX
 SG_ EngDesiredIgntTiming1 : 0|16@1+ (1,-200) [-200|302] "deg" Vector__XXX
 SG_ EngDesiredIgntTiming2 : 16|16@1+ (1,-200) [-200|302] "deg" Vector__XXX
 SG_ EngDesiredIgntTiming3 : 32|16@1+ (1,-200) [-200|302] "deg" Vector__XXX
 SG_ EngActualIgntTiming : 48|16@1+ (1,-200) [-200|302] "deg" Vector__XXX

BO_ 2633926398 IT5: 8 Vector__XXX
 SG_ EngCyl17IgntTiming : 0|16@1+ (1,-200) [-200|302] "deg" Vector__XXX
 SG_ EngCyl18IgntTiming : 16|16@1+ (1,-200) [-200|302] "deg" Vector__XXX
 SG_ EngCyl19IgntTiming : 32|16@1+ (1,-200) [-200|302] "deg" Vector__XXX
 SG_ EngCyl20IgntTiming : 48|16@1+ (1,-200) [-200|302] "deg" Vector__XXX

BO_ 2633926142 IT4: 8 Vector__XXX
 SG_ EngCyl13IgntTiming : 0|16@1+ (1,-200) [-200|302] "deg" Vector__XXX
 SG_ EngCyl14IgntTiming : 16|16@1+ (1,-200) [-200|302] "deg" Vector__XXX
 SG_ EngCyl15IgntTiming : 32|16@1+ (1,-200) [-200|302] "deg" Vector__XXX
 SG_ EngCyl16IgntTiming : 48|16@1+ (1,-200) [-200|302] "deg" Vector__XXX

BO_ 2633925886 IT3: 8 Vector__XXX
 SG_ EngCyl9IgntTiming : 0|16@1+ (1,-200) [-200|302] "deg" Vector__XXX
 SG_ EngCyl10IgntTiming : 16|16@1+ (1,-200) [-200|302] "deg" Vector__XXX
 SG_ EngCyl11IgntTiming : 32|16@1+ (1,-200) [-200|302] "deg" Vector__XXX
 SG_ EngCyl12IgntTiming : 48|16@1+ (1,-200) [-200|302] "deg" Vector__XXX

BO_ 2633925630 IT2: 8 Vector__XXX
 SG_ EngCyl5IgntTiming : 0|16@1+ (1,-200) [-200|302] "deg" Vector__XXX
 SG_ EngCyl6IgntTiming : 16|16@1+ (1,-200) [-200|302] "deg" Vector__XXX
 SG_ EngCyl7IgntTiming : 32|16@1+ (1,-200) [-200|302] "deg" Vector__XXX
 SG_ EngCyl8IgntTiming : 48|16@1+ (1,-200) [-200|302] "deg" Vector__XXX

BO_ 2633925374 IT1: 8 Vector__XXX
 SG_ EngCyl1IgntTiming : 0|16@1+ (1,-200) [-200|302] "deg" Vector__XXX
 SG_ EngCyl2IgntTiming : 16|16@1+ (1,-200) [-200|302] "deg" Vector__XXX
 SG_ EngCyl3IgntTiming : 32|16@1+ (1,-200) [-200|302] "deg" Vector__XXX
 SG_ EngCyl4IgntTiming : 48|16@1+ (1,-200) [-200|302] "deg" Vector__XXX

BO_ 2633927422 ISO3: 8 Vector__XXX
 SG_ EngCyl17IgntTransSecondOutput : 0|8@1+ (1,-125) [-125|125] "%" Vector__XXX
 SG_ EngCyl18IgntTransSecondOutput : 8|8@1+ (1,-125) [-125|125] "%" Vector__XXX
 SG_ EngCyl19IgntTransSecondOutput : 16|8@1+ (1,-125) [-125|125] "%" Vector__XXX
 SG_ EngCyl20IgntTransSecondOutput : 24|8@1+ (1,-125) [-125|125] "%" Vector__XXX

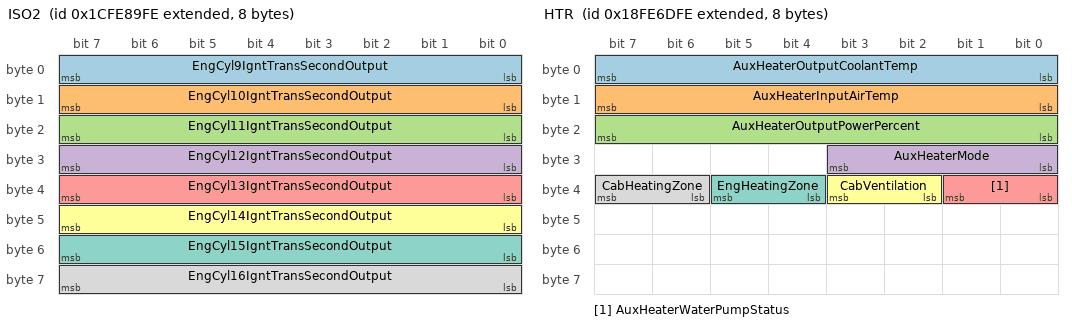
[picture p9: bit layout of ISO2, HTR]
BO_ 2633927166 ISO2: 8 Vector__XXX
 SG_ EngCyl9IgntTransSecondOutput : 0|8@1+ (1,-125) [-125|125] "%" Vector__XXX
 SG_ EngCyl10IgntTransSecondOutput : 8|8@1+ (1,-125) [-125|125] "%" Vector__XXX
 SG_ EngCyl11IgntTransSecondOutput : 16|8@1+ (1,-125) [-125|125] "%" Vector__XXX
 SG_ EngCyl12IgntTransSecondOutput : 24|8@1+ (1,-125) [-125|125] "%" Vector__XXX
 SG_ EngCyl13IgntTransSecondOutput : 32|8@1+ (1,-125) [-125|125] "%" Vector__XXX
 SG_ EngCyl14IgntTransSecondOutput : 40|8@1+ (1,-125) [-125|125] "%" Vector__XXX
 SG_ EngCyl15IgntTransSecondOutput : 48|8@1+ (1,-125) [-125|125] "%" Vector__XXX
 SG_ EngCyl16IgntTransSecondOutput : 56|8@1+ (1,-125) [-125|125] "%" Vector__XXX

BO_ 2633926910 ISO1: 8 Vector__XXX
 SG_ EngCyl1IgntTransSecondOutput : 0|8@1+ (1,-125) [-125|125] "%" Vector__XXX
 SG_ EngCyl2IgntTransSecondOutput : 8|8@1+ (1,-125) [-125|125] "%" Vector__XXX
 SG_ EngCyl3IgntTransSecondOutput : 16|8@1+ (1,-125) [-125|125] "%" Vector__XXX
 SG_ EngCyl4IgntTransSecondOutput : 24|8@1+ (1,-125) [-125|125] "%" Vector__XXX
 SG_ EngCyl5IgntTransSecondOutput : 32|8@1+ (1,-125) [-125|125] "%" Vector__XXX
 SG_ EngCyl6IgntTransSecondOutput : 40|8@1+ (1,-125) [-125|125] "%" Vector__XXX
 SG_ EngCyl7IgntTransSecondOutput : 48|8@1+ (1,-125) [-125|125] "%" Vector__XXX
 SG_ EngCyl8IgntTransSecondOutput : 56|8@1+ (1,-125) [-125|125] "%" Vector__XXX

BO_ 2566768894 ISCS: 8 Vector__XXX
 SG_ EngOprtrPrmryIntrmdtSpdSlctState : 0|4@1+ (1,0) [0|15] "" Vector__XXX

BO_ 2566769201 ISC: 8 Vector__XXX
 SG_ EngOprtrPrmryIntrmdteSpeedSelect : 0|4@1+ (1,0) [0|15] "" Vector__XXX

BO_ 2566839296 IO: 8 Vector__XXX
 SG_ EngTotalIdleFuelUsed : 0|32@1+ (0.5,0) [0|2105540000] "L" Vector__XXX
 SG_ EngTotalIdleHours : 32|32@1+ (0.05,0) [0|210554000] "hr" Vector__XXX

BO_ 2633934334 IMT2: 8 Vector__XXX
 SG_ EngIntakeManifold2Temp : 0|8@1+ (1,-40) [-40|210] "deg C" Vector__XXX
 SG_ EngIntakeManifold3Temp : 8|8@1+ (1,-40) [-40|210] "deg C" Vector__XXX
 SG_ EngIntakeManifold4Temp : 16|8@1+ (1,-40) [-40|210] "deg C" Vector__XXX
 SG_ EngIntakeManifold5Temp : 24|8@1+ (1,-40) [-40|210] "deg C" Vector__XXX
 SG_ EngIntakeManifold6Temp : 32|8@1+ (1,-40) [-40|210] "deg C" Vector__XXX

BO_ 2566825726 IMT1: 8 Vector__XXX
 SG_ EngTurbo1BoostPress : 0|16@1+ (0.125,0) [0|8031.88] "kPa" Vector__XXX
 SG_ EngTurbo2BoostPress : 16|16@1+ (0.125,0) [0|8031.88] "kPa" Vector__XXX
 SG_ EngTurbo3BoostPress : 32|16@1+ (0.125,0) [0|8031.88] "kPa" Vector__XXX
 SG_ EngTurbo4BoostPress : 48|16@1+ (0.125,0) [0|8031.88] "kPa" Vector__XXX

BO_ 2566770942 IC2: 8 Vector__XXX
 SG_ EngAirFilter2DiffPress : 0|8@1+ (0.05,0) [0|12.5] "kPa" Vector__XXX
 SG_ EngAirFilter3DiffPress : 8|8@1+ (0.05,0) [0|12.5] "kPa" Vector__XXX
 SG_ EngAirFilter4DiffPress : 16|8@1+ (0.05,0) [0|12.5] "kPa" Vector__XXX
 SG_ EngIntakeManifold2Press : 24|8@1+ (2,0) [0|500] "kPa" Vector__XXX
 SG_ EngIntakeManifold1AbsPress : 32|8@1+ (2,0) [0|500] "kPa" Vector__XXX
 SG_ EngIntakeManifold1AbsPress : 40|8@1+ (2,0) [0|500] "kPa" Vector__XXX
 SG_ EngIntakeManifold2AbsPress : 56|8@1+ (2,0) [0|500] "kPa" Vector__XXX

BO_ 2566845952 IC1: 8 Vector__XXX
 SG_ EngAirIntakePress : 24|8@1+ (2,0) [0|500] "kPa" Vector__XXX
 SG_ EngDslPrtculateFilterIntakePress : 0|8@1+ (0.5,0) [0|125] "kPa" Vector__XXX
 SG_ EngIntakeManifold1Press : 8|8@1+ (2,0) [0|500] "kPa" Vector__XXX
 SG_ EngIntakeManifold1Temp : 16|8@1+ (1,-40) [-40|210] "deg C" Vector__XXX
 SG_ EngAirFilter1DiffPress : 32|8@1+ (0.05,0) [0|12.5] "kPa" Vector__XXX
 SG_ EngExhaustGasTemp : 40|16@1+ (0.03125,-273) [-273|1734.97] "deg C" Vector__XXX
 SG_ EngCoolantFilterDiffPress : 56|8@1+ (0.5,0) [0|125] "kPa" Vector__XXX

BO_ 2566811134 HTR: 8 Vector__XXX
 SG_ AuxHeaterOutputCoolantTemp : 0|8@1+ (1,-40) [-40|210] "deg C" Vector__XXX
 SG_ AuxHeaterInputAirTemp : 8|8@1+ (1,-40) [-40|210] "deg C" Vector__XXX
 SG_ AuxHeaterOutputPowerPercent : 16|8@1+ (0.4,0) [0|100] "%" Vector__XXX
 SG_ AuxHeaterMode : 24|4@1+ (1,0) [0|15] "" Vector__XXX
 SG_ AuxHeaterWaterPumpStatus : 32|2@1+ (1,0) [0|3] "" Vector__XXX
 SG_ CabVentilation : 34|2@1+ (1,0) [0|3] "" Vector__XXX
 SG_ EngHeatingZone : 36|2@1+ (1,0) [0|3] "" Vector__XXX
 SG_ CabHeatingZone : 38|2@1+ (1,0) [0|3] "" Vector__XXX

BO_ 2298375934 HRW: 8 Vector__XXX
 SG_ FrontAxleLeftWheelSpeed : 0|16@1+ (0.003906,0) [0|250.98] "km/h" Vector__XXX
 SG_ FrontAxleRightWheelSpeed : 16|16@1+ (0.003906,0) [0|250.98] "km/h" Vector__XXX
 SG_ RearAxleLeftWheelSpeed : 32|16@1+ (0.003906,0) [0|250.98] "km/h" Vector__XXX
 SG_ RearAxleRightWheelSpeed : 48|16@1+ (0.003906,0) [0|250.98] "km/h" Vector__XXX

BO_ 2565867774 HPG: 8 Vector__XXX
 SG_ HydPress : 0|16@1+ (2,0) [0|128510] "kPa" Vector__XXX
 SG_ EngHydPressGovernorModeIndicator : 16|2@1+ (1,0) [0|3] "" Vector__XXX
 SG_ EngHydPressGovernorSwitch : 18|2@1+ (1,0) [0|3] "" Vector__XXX
 SG_ FireApparatusPumpEngagement : 20|2@1+ (1,0) [0|3] "" Vector__XXX

BO_ 2566841600 HOURS: 8 Vector__XXX
 SG_ EngTotalHoursOfOperation : 0|32@1+ (0.05,0) [0|210554000] "hr" Vector__XXX
 SG_ EngTotalRevolutions : 32|32@1+ (1000,0) [0|4211080000000] "r" Vector__XXX

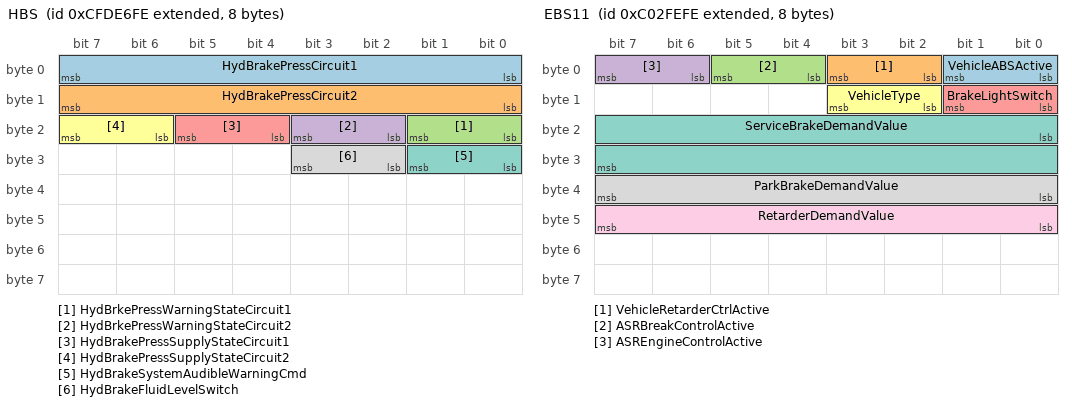
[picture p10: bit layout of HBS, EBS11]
BO_ 2365449982 HBS: 8 Vector__XXX
 SG_ HydBrakePressCircuit1 : 0|8@1+ (0.1,0) [0|25] "MPa" Vector__XXX
 SG_ HydBrakePressCircuit2 : 8|8@1+ (0.1,0) [0|25] "MPa" Vector__XXX
 SG_ HydBrkePressWarningStateCircuit1 : 16|2@1+ (1,0) [0|3] "" Vector__XXX
 SG_ HydBrkePressWarningStateCircuit2 : 18|2@1+ (1,0) [0|3] "" Vector__XXX
 SG_ HydBrakePressSupplyStateCircuit1 : 20|2@1+ (1,0) [0|3] "" Vector__XXX
 SG_ HydBrakePressSupplyStateCircuit2 : 22|2@1+ (1,0) [0|3] "" Vector__XXX
 SG_ HydBrakeSystemAudibleWarningCmd : 24|2@1+ (1,0) [0|3] "" Vector__XXX
 SG_ HydBrakeFluidLevelSwitch : 26|2@1+ (1,0) [0|3] "" Vector__XXX

BO_ 2633927678 GFP: 8 Vector__XXX
 SG_ EngFuelValve1IntakeAbsPress : 0|16@1+ (0.1,0) [0|6425.5] "kPa" Vector__XXX
 SG_ EngFuelValveDiffPress : 16|16@1+ (0.1,0) [0|6425.5] "kPa" Vector__XXX
 SG_ EngAirToFuelDiffPress : 32|16@1+ (0.1,0) [0|6425.5] "kPa" Vector__XXX
 SG_ EngFuelValve1OutletAbsPress : 48|16@1+ (0.1,0) [0|6425.5] "kPa" Vector__XXX

BO_ 2633925118 GFI2: 8 Vector__XXX
 SG_ EngFuelFlowRate1 : 0|16@1+ (0.1,0) [0|6425.5] "m^3/h" Vector__XXX
 SG_ EngFuelFlowRate2 : 16|16@1+ (0.1,0) [0|6425.5] "m^3/h" Vector__XXX
 SG_ EngFuelValve1Pos : 32|8@1+ (0.4,0) [0|100] "%" Vector__XXX
 SG_ EngFuelValve2Pos : 40|8@1+ (0.4,0) [0|100] "%" Vector__XXX
 SG_ EngRequestedFuelValve1Pos : 48|8@1+ (1,0) [0|100] "%" Vector__XXX
 SG_ EngRequestedFuelValve2Pos : 56|8@1+ (1,0) [0|100] "%" Vector__XXX

BO_ 2633937662 GFI1: 8 Vector__XXX
 SG_ TotalEngPTOGovernorFuelUsed : 0|32@1+ (0.5,0) [0|2105540000] "kg" Vector__XXX
 SG_ TripAverageFuelRate : 32|16@1+ (0.05,0) [0|3212.75] "kg/h" Vector__XXX
 SG_ EngFuelSpecificGravity : 48|16@1+ (1,0) [0|6] "" Vector__XXX

BO_ 2566804990 GFD: 8 Vector__XXX
 SG_ SpecificHeatRatio : 0|16@1+ (1,0) [0|64] "" Vector__XXX

BO_ 2633936894 GFC: 8 Vector__XXX
 SG_ TripFuel : 0|32@1+ (0.5,0) [0|2105540000] "kg" Vector__XXX
 SG_ TotalFuelUsed : 32|32@1+ (0.5,0) [0|2105540000] "kg" Vector__XXX

BO_ 2566757630 SEP2: 8 Vector__XXX
 SG_ SensorSupplyVoltage7 : 32|16@1+ (0.05,0) [0|3212.75] "V" Vector__XXX
 SG_ SensorSupplyVoltage8 : 48|16@1+ (0.05,0) [0|3212.75] "V" Vector__XXX
 SG_ SensorSupplyVoltage5 : 0|16@1+ (0.05,0) [0|3212.75] "V" Vector__XXX
 SG_ SensorSupplyVoltage6 : 16|16@1+ (0.05,0) [0|3212.75] "V" Vector__XXX

BO_ 2566757886 SEP1: 8 Vector__XXX
 SG_ SensorSupplyVoltage1 : 0|16@1+ (0.05,0) [0|3212.75] "V" Vector__XXX
 SG_ SensorSupplyVoltage2 : 16|16@1+ (0.05,0) [0|3212.75] "V" Vector__XXX
 SG_ SensorSupplyVoltage3 : 32|16@1+ (0.05,0) [0|3212.75] "V" Vector__XXX
 SG_ SensorSupplyVoltage4 : 48|16@1+ (0.05,0) [0|3212.75] "V" Vector__XXX

BO_ 2566759678 PTODE: 8 Vector__XXX
 SG_ EnblSwtchTrnsfrCseOutputShaftPTO : 0|2@1+ (1,0) [0|3] "" Vector__XXX
 SG_ EnableSwitchTransOutputShaftPTO : 2|2@1+ (1,0) [0|3] "" Vector__XXX
 SG_ EnableSwitchTransInputShaftPTO2 : 4|2@1+ (1,0) [0|3] "" Vector__XXX
 SG_ EnableSwitchTransInputShaftPTO1 : 6|2@1+ (1,0) [0|3] "" Vector__XXX
 SG_ EnableSwitchPTOEngFlywheel : 8|2@1+ (1,0) [0|3] "" Vector__XXX
 SG_ EnbleSwitchPTOEngAccessoryDrive1 : 10|2@1+ (1,0) [0|3] "" Vector__XXX
 SG_ EnbleSwitchPTOEngAccessoryDrive2 : 12|2@1+ (1,0) [0|3] "" Vector__XXX
 SG_ EnggmntCnsntTrnsfrCsOtptShaftPTO : 16|2@1+ (1,0) [0|3] "" Vector__XXX
 SG_ EnggmntCnsentTransOutputShaftPTO : 18|2@1+ (1,0) [0|3] "" Vector__XXX
 SG_ EnggmntCnsentTransInputShaftPTO2 : 20|2@1+ (1,0) [0|3] "" Vector__XXX
 SG_ EnggmntCnsentTransInputShaftPTO1 : 22|2@1+ (1,0) [0|3] "" Vector__XXX
 SG_ EngagementConsentPTOEngFlywheel : 24|2@1+ (1,0) [0|3] "" Vector__XXX
 SG_ EnggmntCnsntPTOEngAccssoryDrive1 : 26|2@1+ (1,0) [0|3] "" Vector__XXX
 SG_ EnggmntCnsntPTOEngAccssoryDrive2 : 28|2@1+ (1,0) [0|3] "" Vector__XXX
 SG_ EnggmntSttsTrnsfrCsOtputShaftPTO : 32|2@1+ (1,0) [0|3] "" Vector__XXX
 SG_ EnggmntStatusTransOutputShaftPTO : 34|2@1+ (1,0) [0|3] "" Vector__XXX
 SG_ EnggmntStatusTransInputShaftPTO2 : 36|2@1+ (1,0) [0|3] "" Vector__XXX
 SG_ EnggmntStatusTransInputShaftPTO1 : 38|2@1+ (1,0) [0|3] "" Vector__XXX
 SG_ EngagementStatusPTOEngFlywheel : 40|2@1+ (1,0) [0|3] "" Vector__XXX
 SG_ EnggmntSttsPTOEngAccessoryDrive1 : 42|2@1+ (1,0) [0|3] "" Vector__XXX
 SG_ EnggmntSttsPTOEngAccessoryDrive2 : 44|2@1+ (1,0) [0|3] "" Vector__XXX
 SG_ AtLeastOnePTOEngaged : 48|2@1+ (1,0) [0|3] "" Vector__XXX

BO_ 2432541438 GFI3: 8 Vector__XXX
 SG_ EngFuelValve2IntakeAbsPress : 0|16@1+ (0.1,0) [0|6425.5] "kPa" Vector__XXX
 SG_ EngGas2MassFlowRate : 16|16@1+ (0.05,0) [0|3212.75] "kg/h" Vector__XXX
 SG_ EngFuelTemp2 : 32|8@1+ (1,-40) [-40|210] "deg C" Vector__XXX
 SG_ EngFuelValve2OutletAbsPress : 48|16@1+ (0.1,0) [0|6425.5] "kPa" Vector__XXX

BO_ 2566761214 EFL_P4: 8 Vector__XXX
 SG_ EngAftercoolerCoolantLevel : 48|8@1+ (0.4,0) [0|100] "%" Vector__XXX
 SG_ EngChargeAirCoolerOutletPress : 56|8@1+ (2,0) [0|500] "kPa" Vector__XXX
 SG_ EngIntercoolerCoolantLevel : 40|8@1+ (0.4,0) [0|100] "%" Vector__XXX
 SG_ EngChargeAirCooler1IntakePress : 0|8@1+ (2,0) [0|500] "kPa" Vector__XXX
 SG_ EngChargeAirCooler2IntakePress : 8|8@1+ (2,0) [0|500] "kPa" Vector__XXX
 SG_ EngCoolantPumpDiffPress : 16|8@1+ (1.64,-7) [-7|403] "kPa" Vector__XXX
 SG_ EngCentrifugalOilFilterSpeed : 24|16@1+ (4,0) [0|257020] "rpm" Vector__XXX

BO_ 2432541694 EEC6: 8 Vector__XXX
 SG_ EngDsrdTrbCmprssrBypssActtor1Pos : 48|8@1+ (0.4,0) [0|100] "%" Vector__XXX
 SG_ EngTrbCmprssorBypassActuator1Cmd : 0|16@1+ (1,0) [0|161] "%" Vector__XXX
 SG_ EngTrbCmprssorBypassActuator1Pos : 24|8@1+ (0.4,0) [0|100] "%" Vector__XXX
 SG_ EngTrbCmprssorBypassActuator2Cmd : 32|16@1+ (1,0) [0|161] "%" Vector__XXX
 SG_ EngTrbCmprssrBypssActtr1PrlmnryF : 56|5@1+ (1,0) [0|31] "" Vector__XXX
 SG_ EngTrbCmprssrBypssActtr1TmpSttus : 61|3@1+ (1,0) [0|7] "" Vector__XXX
 SG_ EngVriableGeometryTurboActuator1 : 16|8@1+ (1,0) [0|100] "%" Vector__XXX

BO_ 2566759934 DC2: 8 Vector__XXX
 SG_ LockStatusOfDoor1 : 0|2@1+ (1,0) [0|3] "" Vector__XXX
 SG_ OpenStatusOfDoor1 : 2|2@1+ (1,0) [0|3] "" Vector__XXX
 SG_ EnableStatusOfDoor1 : 4|2@1+ (1,0) [0|3] "" Vector__XXX
 SG_ LockStatusOfDoor2 : 6|2@1+ (1,0) [0|3] "" Vector__XXX
 SG_ OpenStatusOfDoor2 : 8|2@1+ (1,0) [0|3] "" Vector__XXX
 SG_ EnableStatusOfDoor2 : 10|2@1+ (1,0) [0|3] "" Vector__XXX
 SG_ LockStatusOfDoor3 : 12|2@1+ (1,0) [0|3] "" Vector__XXX
 SG_ OpenStatusOfDoor3 : 14|2@1+ (1,0) [0|3] "" Vector__XXX
 SG_ EnableStatusOfDoor3 : 16|2@1+ (1,0) [0|3] "" Vector__XXX
 SG_ LockStatusOfDoor4 : 18|2@1+ (1,0) [0|3] "" Vector__XXX
 SG_ OpenStatusOfDoor4 : 20|2@1+ (1,0) [0|3] "" Vector__XXX
 SG_ EnableStatusOfDoor4 : 22|2@1+ (1,0) [0|3] "" Vector__XXX
 SG_ LockStatusOfDoor5 : 24|2@1+ (1,0) [0|3] "" Vector__XXX
 SG_ OpenStatusOfDoor5 : 26|2@1+ (1,0) [0|3] "" Vector__XXX
 SG_ EnableStatusOfDoor5 : 28|2@1+ (1,0) [0|3] "" Vector__XXX
 SG_ LockStatusOfDoor6 : 30|2@1+ (1,0) [0|3] "" Vector__XXX
 SG_ OpenStatusOfDoor6 : 32|2@1+ (1,0) [0|3] "" Vector__XXX
 SG_ EnableStatusOfDoor6 : 34|2@1+ (1,0) [0|3] "" Vector__XXX
 SG_ LockStatusOfDoor7 : 36|2@1+ (1,0) [0|3] "" Vector__XXX
 SG_ OpenStatusOfDoor7 : 38|2@1+ (1,0) [0|3] "" Vector__XXX
 SG_ EnableStatusOfDoor7 : 40|2@1+ (1,0) [0|3] "" Vector__XXX
 SG_ LockStatusOfDoor8 : 42|2@1+ (1,0) [0|3] "" Vector__XXX
 SG_ OpenStatusOfDoor8 : 44|2@1+ (1,0) [0|3] "" Vector__XXX
 SG_ EnableStatusOfDoor8 : 46|2@1+ (1,0) [0|3] "" Vector__XXX
 SG_ LockStatusOfDoor9 : 48|2@1+ (1,0) [0|3] "" Vector__XXX
 SG_ OpenStatusOfDoor9 : 50|2@1+ (1,0) [0|3] "" Vector__XXX
 SG_ EnableStatusOfDoor9 : 52|2@1+ (1,0) [0|3] "" Vector__XXX
 SG_ LockStatusOfDoor10 : 54|2@1+ (1,0) [0|3] "" Vector__XXX
 SG_ OpenStatusOfDoor10 : 56|2@1+ (1,0) [0|3] "" Vector__XXX
 SG_ EnableStatusOfDoor10 : 58|2@1+ (1,0) [0|3] "" Vector__XXX

BO_ 2566757374 CRI1: 8 Vector__XXX
 SG_ Aftrtrtmnt1SCRCtlystReagentTemp2 : 0|8@1+ (1,-40) [-40|210] "deg C" Vector__XXX
 SG_ Aftrtrtmnt1SCRCtalystReagentType : 40|4@1+ (1,0) [0|15] "" Vector__XXX
 SG_ Aftrtrtmnt1SCRCtlystRgntCncntrtn : 8|8@1+ (0.25,0) [0|62.5] "%" Vector__XXX
 SG_ Aftrtrtmnt1SCRCtlystRgntCndctvty : 16|8@1+ (5,0) [0|1250] "microSiemens/mm" Vector__XXX
 SG_ Aftrtrtmnt1SCRCtlystRgntPrprtsPr : 32|5@1+ (1,0) [0|31] "" Vector__XXX
 SG_ Aftrtrtmnt1SCRCtlystRgntTmp2Prlm : 24|5@1+ (1,0) [0|31] "" Vector__XXX

BO_ 2364546302 RGAAQ: 8 Vector__XXX
 SG_ RqdGnrtrAvrgLneLineACRMSVoltage : 0|32@1+ (0.007813,0) [0|32901200] "V" Vector__XXX

BO_ 2431654654 TFAC: 8 Vector__XXX
 SG_ EngThrottleActuator1CtrlCmd : 0|16@1+ (1,0) [0|161] "%" Vector__XXX
 SG_ EngThrottleActuator2CtrlCmd : 16|16@1+ (1,0) [0|161] "%" Vector__XXX
 SG_ EngFuelActuator1CtrlCmd : 32|16@1+ (1,0) [0|161] "%" Vector__XXX
 SG_ EngFuelActuator2CtrlCmd : 48|16@1+ (1,0) [0|161] "%" Vector__XXX

BO_ 2364545534 KL3: 8 Vector__XXX
 SG_ EngCyl17KnockLevel : 0|8@1+ (1,0) [0|250] "%" Vector__XXX
 SG_ EngCyl18KnockLevel : 8|8@1+ (1,0) [0|250] "%" Vector__XXX
 SG_ EngCyl19KnockLevel : 16|8@1+ (1,0) [0|250] "%" Vector__XXX
 SG_ EngCyl20KnockLevel : 24|8@1+ (1,0) [0|250] "%" Vector__XXX
 SG_ EngCyl21KnockLevel : 32|8@1+ (1,0) [0|250] "%" Vector__XXX
 SG_ EngCyl22KnockLevel : 40|8@1+ (1,0) [0|250] "%" Vector__XXX
 SG_ EngCyl23KnockLevel : 48|8@1+ (1,0) [0|250] "%" Vector__XXX
 SG_ EngCyl24KnockLevel : 56|8@1+ (1,0) [0|250] "%" Vector__XXX

BO_ 2364545278 KL2: 8 Vector__XXX
 SG_ EngCyl9KnockLevel : 0|8@1+ (1,0) [0|250] "%" Vector__XXX
 SG_ EngCyl10KnockLevel : 8|8@1+ (1,0) [0|250] "%" Vector__XXX
 SG_ EngCyl11KnockLevel : 16|8@1+ (1,0) [0|250] "%" Vector__XXX
 SG_ EngCyl12KnockLevel : 24|8@1+ (1,0) [0|250] "%" Vector__XXX
 SG_ EngCyl13KnockLevel : 32|8@1+ (1,0) [0|250] "%" Vector__XXX
 SG_ EngCyl14KnockLevel : 40|8@1+ (1,0) [0|250] "%" Vector__XXX
 SG_ EngCyl15KnockLevel : 48|8@1+ (1,0) [0|250] "%" Vector__XXX
 SG_ EngCyl16KnockLevel : 56|8@1+ (1,0) [0|250] "%" Vector__XXX

BO_ 2364545022 KL1: 8 Vector__XXX
 SG_ EngCyl1KnockLevel : 0|8@1+ (1,0) [0|250] "%" Vector__XXX
 SG_ EngCyl2KnockLevel : 8|8@1+ (1,0) [0|250] "%" Vector__XXX
 SG_ EngCyl3KnockLevel : 16|8@1+ (1,0) [0|250] "%" Vector__XXX
 SG_ EngCyl4KnockLevel : 24|8@1+ (1,0) [0|250] "%" Vector__XXX
 SG_ EngCyl5KnockLevel : 32|8@1+ (1,0) [0|250] "%" Vector__XXX
 SG_ EngCyl6KnockLevel : 40|8@1+ (1,0) [0|250] "%" Vector__XXX
 SG_ EngCyl7KnockLevel : 48|8@1+ (1,0) [0|250] "%" Vector__XXX
 SG_ EngCyl8KnockLevel : 56|8@1+ (1,0) [0|250] "%" Vector__XXX

BO_ 2364544766 CCS: 8 Vector__XXX
 SG_ EngCyl1CombustionStatus : 0|2@1+ (1,0) [0|3] "" Vector__XXX
 SG_ EngCyl2CombustionStatus : 2|2@1+ (1,0) [0|3] "" Vector__XXX
 SG_ EngCyl3CombustionStatus : 4|2@1+ (1,0) [0|3] "" Vector__XXX
 SG_ EngCyl4CombustionStatus : 6|2@1+ (1,0) [0|3] "" Vector__XXX
 SG_ EngCyl5CombustionStatus : 8|2@1+ (1,0) [0|3] "" Vector__XXX
 SG_ EngCyl6CombustionStatus : 10|2@1+ (1,0) [0|3] "" Vector__XXX
 SG_ EngCyl7CombustionStatus : 12|2@1+ (1,0) [0|3] "" Vector__XXX
 SG_ EngCyl8CombustionStatus : 14|2@1+ (1,0) [0|3] "" Vector__XXX
 SG_ EngCyl9CombustionStatus : 16|2@1+ (1,0) [0|3] "" Vector__XXX
 SG_ EngCyl10CombustionStatus : 18|2@1+ (1,0) [0|3] "" Vector__XXX
 SG_ EngCyl11CombustionStatus : 20|2@1+ (1,0) [0|3] "" Vector__XXX
 SG_ EngCyl12CombustionStatus : 22|2@1+ (1,0) [0|3] "" Vector__XXX
 SG_ EngCyl13CombustionStatus : 24|2@1+ (1,0) [0|3] "" Vector__XXX
 SG_ EngCyl14CombustionStatus : 26|2@1+ (1,0) [0|3] "" Vector__XXX
 SG_ EngCyl15CombustionStatus : 28|2@1+ (1,0) [0|3] "" Vector__XXX
 SG_ EngCyl16CombustionStatus : 30|2@1+ (1,0) [0|3] "" Vector__XXX
 SG_ EngCyl17CombustionStatus : 32|2@1+ (1,0) [0|3] "" Vector__XXX
 SG_ EngCyl18CombustionStatus : 34|2@1+ (1,0) [0|3] "" Vector__XXX
 SG_ EngCyl19CombustionStatus : 36|2@1+ (1,0) [0|3] "" Vector__XXX
 SG_ EngCyl20CombustionStatus : 38|2@1+ (1,0) [0|3] "" Vector__XXX
 SG_ EngCyl21CombustionStatus : 40|2@1+ (1,0) [0|3] "" Vector__XXX
 SG_ EngCyl22CombustionStatus : 42|2@1+ (1,0) [0|3] "" Vector__XXX
 SG_ EngCyl23CombustionStatus : 44|2@1+ (1,0) [0|3] "" Vector__XXX
 SG_ EngCyl24CombustionStatus : 46|2@1+ (1,0) [0|3] "" Vector__XXX

BO_ 2364544510 RGTARP: 8 Vector__XXX
 SG_ RqGeneratorTotalACReactivePower : 0|32@1+ (1,-2000000000) [-2000000000|2000000000] "VA" Vector__XXX
 SG_ RqGeneratorOverallPowerFactor : 32|16@1+ (6.1E-005,-1) [-1|2.91955] "" Vector__XXX
 SG_ RqGenOverallPowerFactorLagging : 48|2@1+ (1,0) [0|3] "" Vector__XXX

BO_ 2364544254 BI: 8 Vector__XXX
 SG_ RelativeBladeHeight : 0|16@1+ (0.1,-3200) [-3200|3225.5] "mm" Vector__XXX
 SG_ BladeRotationAngle : 16|16@1+ (0.007812,-200) [-200|301.96] "deg" Vector__XXX
 SG_ RltvBldHghtAndBldRttnAnglMsrmntL : 32|8@1+ (0.5,0) [0|125] "ms" Vector__XXX
 SG_ RelativeBladeHeightFigureOfMerit : 40|2@1+ (1,0) [0|3] "" Vector__XXX
 SG_ BladeRotationAngleFigureOfMerit : 42|2@1+ (1,0) [0|3] "" Vector__XXX

BO_ 2349006590 EBS11: 8 Vector__XXX
 SG_ VehicleABSActive : 0|2@1+ (1,0) [0|1] "" Vector__XXX
 SG_ VehicleRetarderCtrlActive : 2|2@1+ (1,0) [0|3] "" Vector__XXX
 SG_ ASRBreakControlActive : 4|2@1+ (1,0) [0|3] "" Vector__XXX
 SG_ ASREngineControlActive : 6|2@1+ (1,0) [0|3] "" Vector__XXX
 SG_ BrakeLightSwitch : 8|2@1+ (1,0) [0|3] "" Vector__XXX
 SG_ VehicleType : 10|2@1+ (1,0) [0|3] "" Vector__XXX
 SG_ ServiceBrakeDemandValue : 16|16@1+ (0.019531,0) [0|1254.98] "kPa" Vector__XXX
 SG_ ParkBrakeDemandValue : 32|8@1+ (0.4,0) [0|100] "%" Vector__XXX
 SG_ RetarderDemandValue : 40|8@1+ (1,-125) [-125|125] "%" Vector__XXX

BO_ 2566834686 EBS12: 8 Vector__XXX
 SG_ VehicleRetarderCtrlActive : 0|2@1+ (1,0) [0|3] "" Vector__XXX
 SG_ TwoElCircuitsBrakeDemand : 16|2@1+ (1,0) [0|1] "" Vector__XXX
 SG_ ABSOffroadRequest : 18|2@1+ (1,0) [0|1] "" Vector__XXX
 SG_ PneumaticControlLine : 20|2@1+ (1,0) [0|1] "" Vector__XXX
 SG_ RoadCurvature : 32|16@1+ (1,-250) [-250|252] "1/km" Vector__XXX

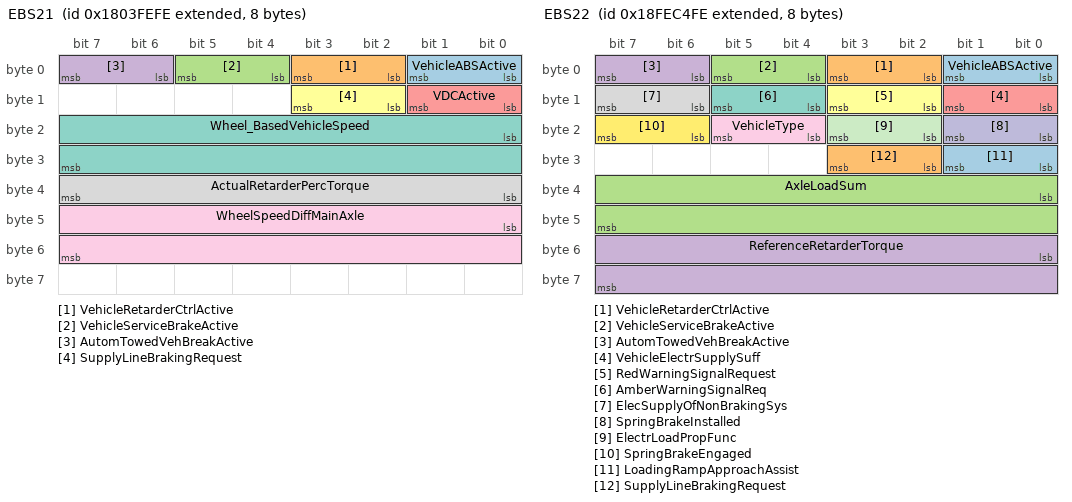
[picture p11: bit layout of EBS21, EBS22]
BO_ 2550398718 EBS21: 8 Vector__XXX
 SG_ VehicleABSActive : 0|2@1+ (1,0) [0|1] "" Vector__XXX
 SG_ VehicleRetarderCtrlActive : 2|2@1+ (1,0) [0|3] "" Vector__XXX
 SG_ VehicleServiceBrakeActive : 4|2@1+ (1,0) [0|1] "" Vector__XXX
 SG_ AutomTowedVehBreakActive : 6|2@1+ (1,0) [0|1] "" Vector__XXX
 SG_ VDCActive : 8|2@1+ (1,0) [0|1] "" Vector__XXX
 SG_ SupplyLineBrakingRequest : 10|2@1+ (1,0) [0|1] "" Vector__XXX
 SG_ Wheel_BasedVehicleSpeed : 16|16@1+ (0.003906,0) [0|250.984] "km/hr" Vector__XXX
 SG_ ActualRetarderPercTorque : 32|8@1+ (1,-125) [-125|125] "%" Vector__XXX
 SG_ WheelSpeedDiffMainAxle : 40|16@1+ (0.003906,-125) [-125|124.984] "km/hr" Vector__XXX

BO_ 2566833406 EBS22: 8 Vector__XXX
 SG_ VehicleABSActive : 0|2@1+ (1,0) [0|1] "" Vector__XXX
 SG_ VehicleRetarderCtrlActive : 2|2@1+ (1,0) [0|3] "" Vector__XXX
 SG_ VehicleServiceBrakeActive : 4|2@1+ (1,0) [0|1] "" Vector__XXX
 SG_ AutomTowedVehBreakActive : 6|2@1+ (1,0) [0|1] "" Vector__XXX
 SG_ VehicleElectrSupplySuff : 8|2@1+ (1,0) [0|1] "" Vector__XXX
 SG_ RedWarningSignalRequest : 10|2@1+ (1,0) [0|1] "" Vector__XXX
 SG_ AmberWarningSignalReq : 12|2@1+ (1,0) [0|1] "" Vector__XXX
 SG_ ElecSupplyOfNonBrakingSys : 14|2@1+ (1,0) [0|1] "" Vector__XXX
 SG_ VehicleType : 20|2@1+ (1,0) [0|3] "" Vector__XXX
 SG_ SpringBrakeInstalled : 16|2@1+ (1,0) [0|1] "" Vector__XXX
 SG_ ElectrLoadPropFunc : 18|2@1+ (1,0) [0|1] "" Vector__XXX
 SG_ SpringBrakeEngaged : 22|2@1+ (1,0) [0|1] "" Vector__XXX
 SG_ LoadingRampApproachAssist : 24|2@1+ (1,0) [0|1] "" Vector__XXX
 SG_ SupplyLineBrakingRequest : 26|2@1+ (1,0) [0|1] "" Vector__XXX
 SG_ AxleLoadSum : 32|16@1+ (2,0) [0|128510] "kg" Vector__XXX
 SG_ ReferenceRetarderTorque : 48|16@1+ (1,0) [0|64255] "Nm" Vector__XXX

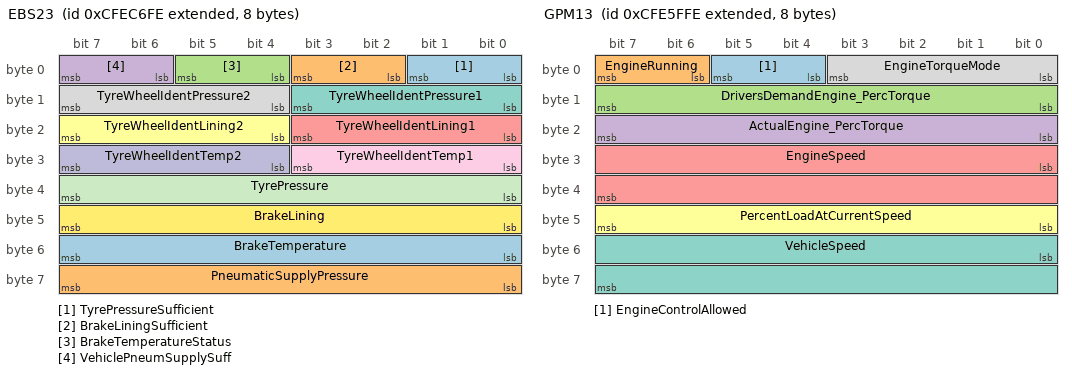
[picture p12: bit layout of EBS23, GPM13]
BO_ 2365507326 EBS23: 8 Vector__XXX
 SG_ TyrePressureSufficient : 0|2@1+ (1,0) [0|1] "" Vector__XXX
 SG_ BrakeLiningSufficient : 2|2@1+ (1,0) [0|1] "" Vector__XXX
 SG_ BrakeTemperatureStatus : 4|2@1+ (1,0) [0|1] "" Vector__XXX
 SG_ VehiclePneumSupplySuff : 6|2@1+ (1,0) [0|1] "" Vector__XXX
 SG_ TyreWheelIdentLining1 : 16|4@1+ (1,0) [0|15] "" Vector__XXX
 SG_ TyreWheelIdentLining2 : 20|4@1+ (1,0) [0|15] "" Vector__XXX
 SG_ TyreWheelIdentPressure1 : 8|4@1+ (1,0) [0|15] "" Vector__XXX
 SG_ TyreWheelIdentPressure2 : 12|4@1+ (1,0) [0|15] "" Vector__XXX
 SG_ TyreWheelIdentTemp1 : 24|4@1+ (1,0) [0|15] "" Vector__XXX
 SG_ TyreWheelIdentTemp2 : 28|4@1+ (1,0) [0|15] "" Vector__XXX
 SG_ TyrePressure : 32|8@1+ (10,0) [0|2500] "kPa" Vector__XXX
 SG_ BrakeLining : 40|8@1+ (0.4,0) [0|100] "%" Vector__XXX
 SG_ BrakeTemperature : 48|8@1+ (10,0) [0|2500] "°C" Vector__XXX
 SG_ PneumaticSupplyPressure : 56|8@1+ (5,0) [0|1250] "kPa" Vector__XXX

BO_ 2565013246 GPM11: 8 Vector__XXX
 SG_ VehicleType : 0|2@1+ (1,0) [0|3] "" Vector__XXX
 SG_ AntiTheftDeviceReq : 8|2@1+ (1,0) [0|3] "" Vector__XXX
 SG_ ODDRequest : 10|2@1+ (1,0) [0|3] "" Vector__XXX

BO_ 2566807038 GPM12: 8 Vector__XXX
 SG_ EngineSpeedLowerLimit : 16|16@1+ (0.125,0) [0|8191.88] "rpm" Vector__XXX
 SG_ EngineSpeedUpperLimit : 0|16@1+ (0.125,0) [0|8031.88] "rpm" Vector__XXX
 SG_ MaxVehicleSpeedLimit : 32|8@1+ (1,0) [0|250] "km/h" Vector__XXX

BO_ 2365480958 GPM13: 8 Vector__XXX
 SG_ EngineControlAllowed : 4|2@1+ (1,0) [0|1] "" Vector__XXX
 SG_ EngineRunning : 6|2@1+ (1,0) [0|1] "" Vector__XXX
 SG_ DriversDemandEngine_PercTorque : 8|8@1+ (1,-125) [-125|125] "%" Vector__XXX
 SG_ ActualEngine_PercTorque : 16|8@1+ (1,-125) [-125|125] "%" Vector__XXX
 SG_ EngineSpeed : 24|16@1+ (0.125,0) [0|8031.88] "rpm" Vector__XXX
 SG_ PercentLoadAtCurrentSpeed : 40|8@1+ (1,0) [0|125] "%" Vector__XXX
 SG_ VehicleSpeed : 48|16@1+ (0.003906,0) [0|250.98] "km/hr" Vector__XXX
 SG_ EngineTorqueMode : 0|4@1+ (1,0) [0|15] "" Vector__XXX

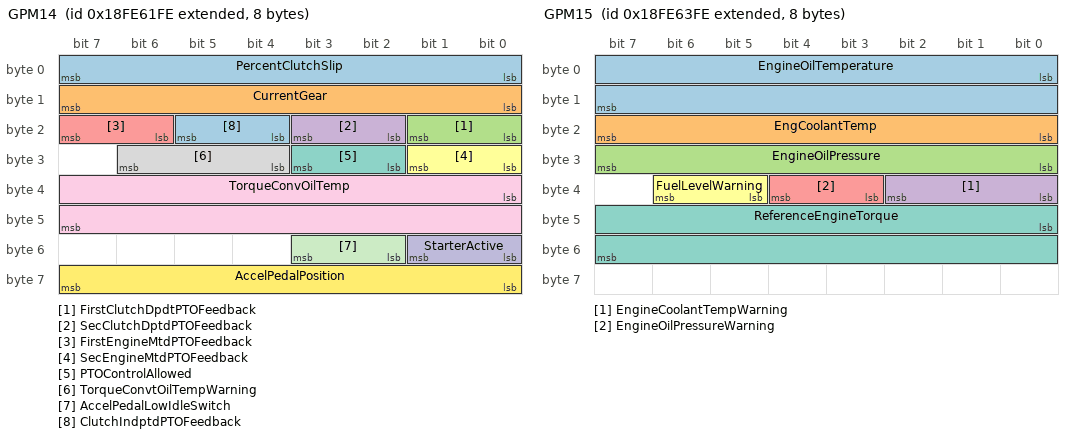
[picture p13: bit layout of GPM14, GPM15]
BO_ 2566808062 GPM14: 8 Vector__XXX
 SG_ PercentClutchSlip : 0|8@1+ (0.4,0) [0|100] "%" Vector__XXX
 SG_ CurrentGear : 8|8@1+ (1,-125) [-125|125] "" Vector__XXX
 SG_ FirstClutchDpdtPTOFeedback : 16|2@1+ (1,0) [0|1] "" Vector__XXX
 SG_ SecClutchDptdPTOFeedback : 18|2@1+ (1,0) [0|1] "" Vector__XXX
 SG_ FirstEngineMtdPTOFeedback : 22|2@1+ (1,0) [0|1] "" Vector__XXX
 SG_ SecEngineMtdPTOFeedback : 24|2@1+ (1,0) [0|1] "" Vector__XXX
 SG_ PTOControlAllowed : 26|2@1+ (1,0) [0|1] "" Vector__XXX
 SG_ TorqueConvtOilTempWarning : 28|3@1+ (1,0) [0|2] "" Vector__XXX
 SG_ TorqueConvOilTemp : 32|16@1+ (0.03125,-273) [-273|1735] "°C" Vector__XXX
 SG_ StarterActive : 48|2@1+ (1,0) [0|1] "" Vector__XXX
 SG_ AccelPedalLowIdleSwitch : 50|2@1+ (1,0) [0|1] "" Vector__XXX
 SG_ AccelPedalPosition : 56|8@1+ (0.4,0) [0|100] "%" Vector__XXX
 SG_ ClutchIndptdPTOFeedback : 20|2@1+ (1,0) [0|1] "" Vector__XXX

BO_ 2566808574 GPM15: 8 Vector__XXX
 SG_ EngineOilTemperature : 0|16@1+ (0.03125,-273) [-273|1735] "°C" Vector__XXX
 SG_ EngCoolantTemp : 16|8@1+ (1,-40) [-40|210] "deg C" Vector__XXX
 SG_ EngineOilPressure : 24|8@1+ (4,0) [0|1000] "kPa" Vector__XXX
 SG_ EngineCoolantTempWarning : 32|3@1+ (1,0) [0|2] "" Vector__XXX
 SG_ EngineOilPressureWarning : 35|2@1+ (1,0) [0|1] "" Vector__XXX
 SG_ FuelLevelWarning : 37|2@1+ (1,0) [0|1] "" Vector__XXX
 SG_ ReferenceEngineTorque : 40|16@1+ (1,0) [0|64255] "Nm" Vector__XXX

BO_ 2566809086 GPM16: 8 Vector__XXX
 SG_ AmbientAirTemperature : 0|16@1+ (0.03125,-273) [-273|1735] "°C" Vector__XXX

BO_ 2564947710 GPM21: 8 Vector__XXX
 SG_ VehicleType : 0|2@1+ (1,0) [0|3] "" Vector__XXX

BO_ 2566834430 GPM22: 8 Vector__XXX
 SG_ ODDStatus : 0|2@1+ (1,0) [0|1] "" Vector__XXX
 SG_ AntiTheftDeviceStatus : 2|2@1+ (1,0) [0|1] "" Vector__XXX
 SG_ RearObstacleDistance : 16|8@1+ (2,0) [0|500] "cm" Vector__XXX
 SG_ ThermalBodyTemperature : 24|8@1+ (1,-125) [-125|125] "°C" Vector__XXX
 SG_ BodyFluidLevel : 32|16@1+ (2,0) [0|128510] "L" Vector__XXX
 SG_ BodyPressure : 48|8@1+ (0.1,0) [0|25] "bar" Vector__XXX

BO_ 2365481214 GPM23: 8 Vector__XXX
 SG_ ReqEngineSpeed : 0|16@1+ (0.125,0) [0|8031.88] "rpm" Vector__XXX
 SG_ ReqEngineSpeedLimit : 56|8@1+ (1,0) [0|250] "km/hr" Vector__XXX
 SG_ ReqEngineTorqueLimit : 48|8@1+ (1,-125) [-125|125] "%" Vector__XXX
 SG_ ReqEngineSpeedLowerLim : 32|16@1+ (0.125,0) [0|8031.88] "rpm" Vector__XXX
 SG_ ReqEngineSpeedUpperLim : 16|16@1+ (0.125,0) [0|8031.88] "rpm" Vector__XXX

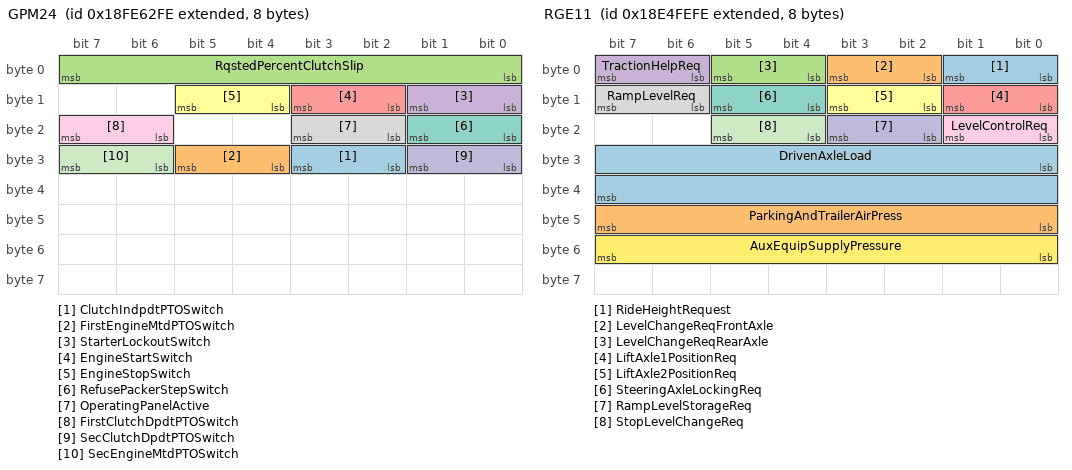
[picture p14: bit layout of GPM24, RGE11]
BO_ 2566808318 GPM24: 8 Vector__XXX
 SG_ ClutchIndpdtPTOSwitch : 26|2@1+ (1,0) [0|1] "" Vector__XXX
 SG_ FirstEngineMtdPTOSwitch : 28|2@1+ (1,0) [0|1] "" Vector__XXX
 SG_ RqstedPercentClutchSlip : 0|8@1+ (0.4,0) [0|100] "%" Vector__XXX
 SG_ StarterLockoutSwitch : 8|2@1+ (1,0) [0|1] "" Vector__XXX
 SG_ EngineStartSwitch : 10|2@1+ (1,0) [0|3] "" Vector__XXX
 SG_ EngineStopSwitch : 12|2@1+ (1,0) [0|1] "" Vector__XXX
 SG_ RefusePackerStepSwitch : 16|2@1+ (1,0) [0|1] "" Vector__XXX
 SG_ OperatingPanelActive : 18|2@1+ (1,0) [0|1] "" Vector__XXX
 SG_ FirstClutchDpdtPTOSwitch : 22|2@1+ (1,0) [0|1] "" Vector__XXX
 SG_ SecClutchDpdtPTOSwitch : 24|2@1+ (1,0) [0|1] "" Vector__XXX
 SG_ SecEngineMtdPTOSwitch : 30|2@1+ (1,0) [0|1] "" Vector__XXX

BO_ 2566808830 GPM25: 8 Vector__XXX
 SG_ TrailerLeftStopLight : 0|2@1+ (1,0) [0|3] "" Vector__XXX
 SG_ TrailerRearWarningLight : 36|2@1+ (1,0) [0|3] "" Vector__XXX
 SG_ TrailerRightCrnMarkerLight : 30|2@1+ (1,0) [0|3] "" Vector__XXX
 SG_ TrailerRightDirIndLight : 6|2@1+ (1,0) [0|3] "" Vector__XXX
 SG_ TrailerRightRearFogLight : 14|2@1+ (1,0) [0|3] "" Vector__XXX
 SG_ TrailerRightRearLight : 10|2@1+ (1,0) [0|3] "" Vector__XXX
 SG_ TrailerRightRearRegPltLight : 34|2@1+ (1,0) [0|3] "" Vector__XXX
 SG_ TrailRightRearWidIndLight : 26|2@1+ (1,0) [0|3] "" Vector__XXX
 SG_ TrailerRightReversingLight : 18|2@1+ (1,0) [0|3] "" Vector__XXX
 SG_ TrailerRightSideMrkLight : 22|2@1+ (1,0) [0|3] "" Vector__XXX
 SG_ TrailerRightStopLight : 2|2@1+ (1,0) [0|3] "" Vector__XXX
 SG_ TrailerRotatingIdentLight : 38|2@1+ (1,0) [0|3] "" Vector__XXX
 SG_ TrailerWorkLamp : 42|2@1+ (1,0) [0|3] "" Vector__XXX
 SG_ TrailerInteriorLight : 40|2@1+ (1,0) [0|3] "" Vector__XXX
 SG_ TrailerLeftCrnMarkerLight : 28|2@1+ (1,0) [0|3] "" Vector__XXX
 SG_ TrailerLeftDirIndLight : 4|2@1+ (1,0) [0|3] "" Vector__XXX
 SG_ TrailerLeftRearFogLight : 12|2@1+ (1,0) [0|3] "" Vector__XXX
 SG_ TrailerLeftRearLight : 8|2@1+ (1,0) [0|3] "" Vector__XXX
 SG_ TrailerLeftRearRegPltLight : 32|2@1+ (1,0) [0|3] "" Vector__XXX
 SG_ TrailerLeftRearWidIndLight : 24|2@1+ (1,0) [0|3] "" Vector__XXX
 SG_ TrailerLeftReversingLight : 16|2@1+ (1,0) [0|3] "" Vector__XXX
 SG_ TrailerLeftSideMarkerLight : 20|2@1+ (1,0) [0|3] "" Vector__XXX

BO_ 2564554494 ISO15765_Funct: 8 Vector__XXX
 SG_ ProtocolCtrlInformation : 4|4@1+ (1,0) [0|3] "" Vector__XXX
 SG_ SingleFrameDataLength : 0|4@1+ (1,0) [0|7] "Byte" Vector__XXX
 SG_ FirstFrameDataLength : 3|12@0+ (1,0) [0|4095] "Byte" Vector__XXX
 SG_ FlowStatus : 0|4@1+ (1,0) [0|3] "" Vector__XXX
 SG_ BlockSize : 8|8@1+ (1,0) [0|255] "" Vector__XXX
 SG_ SeparationTime : 16|8@1+ (1,0) [0|255] "ms" Vector__XXX
 SG_ SN : 0|4@1+ (1,0) [0|15] "" Vector__XXX

BO_ 2564488958 ISO15765_Phys: 8 Vector__XXX
 SG_ ProtocolCtrlInformation : 4|4@1+ (1,0) [0|3] "" Vector__XXX
 SG_ SingleFrameDataLength : 0|4@1+ (1,0) [0|7] "Byte" Vector__XXX
 SG_ FirstFrameDataLength : 3|12@0+ (1,0) [0|4095] "Byte" Vector__XXX
 SG_ FlowStatus : 0|4@1+ (1,0) [0|3] "" Vector__XXX
 SG_ BlockSize : 8|8@1+ (1,0) [0|255] "" Vector__XXX
 SG_ SeparationTime : 16|8@1+ (1,0) [0|255] "ms" Vector__XXX
 SG_ SN : 0|4@1+ (1,0) [0|15] "" Vector__XXX

BO_ 2565734142 Network: 8 Vector__XXX
 SG_ FromPort : 12|4@1+ (1,0) [0|15] "" Vector__XXX
 SG_ ToPort : 8|4@1+ (1,0) [0|15] "" Vector__XXX
 SG_ FilterMode : 16|8@1+ (1,0) [0|255] "" Vector__XXX
 SG_ ControlByte : 0|8@1+ (1,0) [0|255] "" Vector__XXX

BO_ 2565144318 RGE11: 8 Vector__XXX
 SG_ RideHeightRequest : 0|2@1+ (1,0) [0|3] "" Vector__XXX
 SG_ LevelChangeReqFrontAxle : 2|2@1+ (1,0) [0|3] "" Vector__XXX
 SG_ LevelChangeReqRearAxle : 4|2@1+ (1,0) [0|3] "" Vector__XXX
 SG_ TractionHelpReq : 6|2@1+ (1,0) [0|3] "" Vector__XXX
 SG_ LiftAxle1PositionReq : 8|2@1+ (1,0) [0|3] "" Vector__XXX
 SG_ LiftAxle2PositionReq : 10|2@1+ (1,0) [0|3] "" Vector__XXX
 SG_ SteeringAxleLockingReq : 12|2@1+ (1,0) [0|3] "" Vector__XXX
 SG_ RampLevelReq : 14|2@1+ (1,0) [0|3] "" Vector__XXX
 SG_ LevelControlReq : 16|2@1+ (1,0) [0|3] "" Vector__XXX
 SG_ RampLevelStorageReq : 18|2@1+ (1,0) [0|3] "" Vector__XXX
 SG_ StopLevelChangeReq : 20|2@1+ (1,0) [0|3] "" Vector__XXX
 SG_ AuxEquipSupplyPressure : 48|8@1+ (8,0) [0|2000] "kPa" Vector__XXX
 SG_ DrivenAxleLoad : 24|16@1+ (2,0) [0|128510] "kg" Vector__XXX
 SG_ ParkingAndTrailerAirPress : 40|8@1+ (8,0) [0|2000] "kPa" Vector__XXX

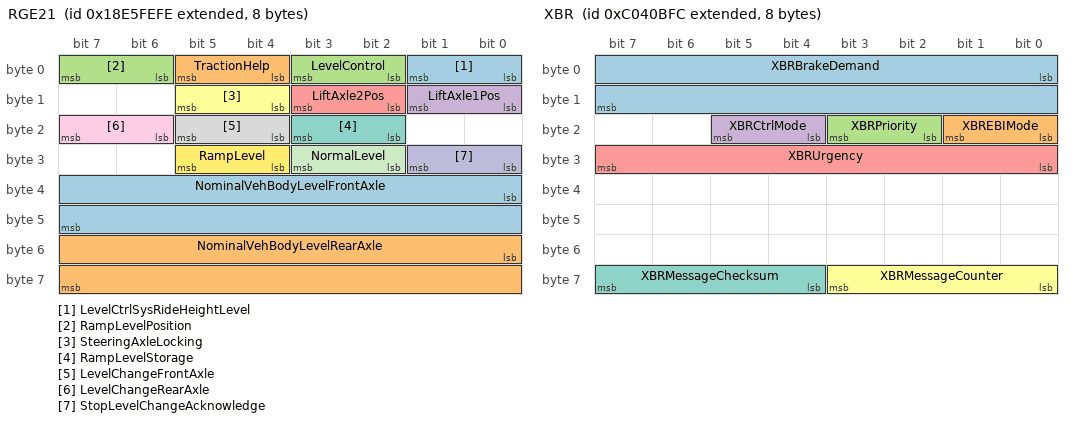
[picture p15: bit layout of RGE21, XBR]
BO_ 2565209854 RGE21: 8 Vector__XXX
 SG_ LevelCtrlSysRideHeightLevel : 0|2@1+ (1,0) [0|1] "" Vector__XXX
 SG_ TractionHelp : 4|2@1+ (1,0) [0|1] "" Vector__XXX
 SG_ RampLevelPosition : 6|2@1+ (1,0) [0|3] "" Vector__XXX
 SG_ LiftAxle1Pos : 8|2@1+ (1,0) [0|3] "" Vector__XXX
 SG_ LiftAxle2Pos : 10|2@1+ (1,0) [0|3] "" Vector__XXX
 SG_ SteeringAxleLocking : 12|2@1+ (1,0) [0|3] "" Vector__XXX
 SG_ RampLevelStorage : 18|2@1+ (1,0) [0|1] "" Vector__XXX
 SG_ LevelChangeFrontAxle : 20|2@1+ (1,0) [0|1] "" Vector__XXX
 SG_ LevelChangeRearAxle : 22|2@1+ (1,0) [0|1] "" Vector__XXX
 SG_ StopLevelChangeAcknowledge : 24|2@1+ (1,0) [0|1] "" Vector__XXX
 SG_ NormalLevel : 26|2@1+ (1,0) [0|3] "" Vector__XXX
 SG_ RampLevel : 28|2@1+ (1,0) [0|1] "" Vector__XXX
 SG_ NominalVehBodyLevelFrontAxle : 32|16@1+ (1,0) [0|64255] "mm" Vector__XXX
 SG_ NominalVehBodyLevelRearAxle : 48|16@1+ (1,0) [0|64255] "mm" Vector__XXX
 SG_ LevelControl : 2|2@1+ (1,0) [0|1] "" Vector__XXX

BO_ 2566806782 RGE22: 8 Vector__XXX
 SG_ RelVehBodyLevelFrontAxle : 0|16@1+ (1,-32000) [-32000|32255] "mm" Vector__XXX
 SG_ RelVehBodyLevelRearAxle : 16|16@1+ (1,0) [0|64255] "mm" Vector__XXX

BO_ 2566807294 RGE23: 8 Vector__XXX
 SG_ TyreWheelIdentification1 : 0|4@1+ (1,0) [0|15] "" Vector__XXX
 SG_ TyreWheelIdentification2 : 4|4@1+ (1,0) [0|15] "" Vector__XXX
 SG_ AirLeakageDetection : 24|16@1+ (0.1,0) [0|6425.5] "Pa/s" Vector__XXX
 SG_ TyreTemperature : 8|16@1+ (0.03125,-273) [-273|1735] "°C" Vector__XXX
 SG_ TyreModulePowerSupply : 43|2@1+ (1,0) [0|1] "" Vector__XXX
 SG_ TyrePressThresholdDetect : 40|3@1+ (1,0) [0|7] "" Vector__XXX

BO_ 2566764798 DM26: 8 Vector__XXX
 SG_ TimeSinceEngineStart : 0|16@1+ (1,0) [0|64255] "sec" Vector__XXX
 SG_ NumOfWarmUpsSinceDTCsCleared : 16|8@1+ (1,0) [0|250] "" Vector__XXX
 SG_ FuelSystemMonitoringComplete : 29|1@1- (1,0) [0|1] "" Vector__XXX
 SG_ ACSystemRefrigerantMonEnabled : 36|1@1- (1,0) [0|1] "" Vector__XXX
 SG_ ACSystemRefrigerantMonComplete : 52|1@1- (1,0) [0|1] "" Vector__XXX
 SG_ CatalystMonEnabled : 32|1@1- (1,0) [0|1] "" Vector__XXX
 SG_ CatalystMonComplete : 48|1@1- (1,0) [0|1] "" Vector__XXX
 SG_ ColdStartAidSystemMonEnabled : 40|1@1- (1,0) [0|1] "" Vector__XXX
 SG_ ColdStartAidSystemMonComplete : 56|1@1- (1,0) [0|1] "" Vector__XXX
 SG_ EGRSystemMonitoringEnabled : 39|1@1- (1,0) [0|1] "" Vector__XXX
 SG_ EGRSystemMonitoringComplete : 55|1@1- (1,0) [0|1] "" Vector__XXX
 SG_ EvaporativeSystemMonEnabled : 34|1@1- (1,0) [0|1] "" Vector__XXX
 SG_ EvaporativeSystemMonComplete : 50|1@1- (1,0) [0|1] "" Vector__XXX
 SG_ HeatedCatalystMonEnabled : 33|1@1- (1,0) [0|1] "" Vector__XXX
 SG_ HeatedCatalystMonComplete : 49|1@1- (1,0) [0|1] "" Vector__XXX
 SG_ OxygenSensorHeaterMonEnabled : 38|1@1- (1,0) [0|1] "" Vector__XXX
 SG_ OxygenSensorHeaterMonComplete : 54|1@1- (1,0) [0|1] "" Vector__XXX
 SG_ OxygenSensorMonEnabled : 37|1@1- (1,0) [0|1] "" Vector__XXX
 SG_ OxygenSensorMonComplete : 53|1@1- (1,0) [0|1] "" Vector__XXX
 SG_ SecondAirSystemMonEnabled : 35|1@1- (1,0) [0|1] "" Vector__XXX
 SG_ SecondAirSystemMonComplete : 51|1@1- (1,0) [0|1] "" Vector__XXX
 SG_ ComprehensiveCompMonEnabled : 26|1@1- (1,0) [0|1] "" Vector__XXX
 SG_ ComprehensiveComptMonComplete : 30|1@1- (1,0) [0|1] "" Vector__XXX
 SG_ FuelSystemMonitoringEnabled : 25|1@1- (1,0) [0|1] "" Vector__XXX
 SG_ MisfireMonitoringEnabled : 24|1@1- (1,0) [0|1] "" Vector__XXX
 SG_ MisfireMonitoringComplete : 28|1@1- (1,0) [0|1] "" Vector__XXX
 SG_ BoostPressureControlSystemEnable : 41|1@1- (1,0) [0|1] "" Vector__XXX
 SG_ BoostPressureControlSystemComple : 57|1@1- (1,0) [0|1] "" Vector__XXX
 SG_ DieselParticulateFilterEnabled : 42|1@1- (1,0) [0|1] "" Vector__XXX
 SG_ DieselParticulateFilterCompleted : 58|1@1- (1,0) [0|1] "" Vector__XXX
 SG_ NOxConvertingCatalystAdsorberEna : 43|1@1- (1,0) [0|1] "" Vector__XXX
 SG_ NOxConvertingCatalystAdsorberCom : 59|1@1- (1,0) [0|1] "" Vector__XXX
 SG_ NMHCConvertingCatalystEnabled : 44|1@1- (1,0) [0|1] "" Vector__XXX
 SG_ NMHCConvertingCatalystCompleted : 60|1@1- (1,0) [0|1] "" Vector__XXX

BO_ 2564095742 DM18: 8 Vector__XXX
 SG_ SecurityEntityLength : 0|8@1+ (1,0) [0|255] "Byte" Vector__XXX
 SG_ SecurityEntityType : 8|4@1+ (1,0) [0|15] "" Vector__XXX
 SG_ SecurityEntityLengthHigh : 12|4@1+ (1,0) [0|15] "Byte" Vector__XXX

BO_ 2349075452 XBR: 8 VCU
 SG_ XBRBrakeDemand : 0|16@1+ (0.000488,-15.69) [-15.69|-15.6749] "m/s?" Vector__XXX
 SG_ XBREBIMode : 16|2@1+ (1,0) [0|3] "" Vector__XXX
 SG_ XBRPriority : 18|2@1+ (1,0) [0|3] "" Vector__XXX
 SG_ XBRCtrlMode : 20|2@1+ (1,0) [0|3] "" Vector__XXX
 SG_ XBRUrgency : 24|8@1+ (1,0) [0|100] "%" Vector__XXX
 SG_ XBRMessageCounter : 56|4@1+ (1,0) [0|15] "" Vector__XXX
 SG_ XBRMessageChecksum : 60|4@1+ (1,0) [0|15] "" Vector__XXX

BO_ 2566848510 WFI: 8 Vector__XXX
 SG_ WaterInFuelIndicator : 0|2@1+ (1,0) [0|3] "" Vector__XXX

BO_ 2566843134 VW: 7 Vector__XXX
 SG_ AxleWeight : 8|16@1+ (0.5,0) [0|32127.5] "kg" Vector__XXX
 SG_ TrailerWeight : 24|16@1+ (2,0) [0|128510] "kg" Vector__XXX
 SG_ CargoWeight : 40|16@1+ (2,0) [0|128510] "kg" Vector__XXX
 SG_ AxleLocation : 0|8@1+ (1,0) [0|255] "" Vector__XXX

BO_ 2566804222 VEP3: 8 Vector__XXX
 SG_ AltCurrent : 0|16@1+ (0.05,-1600) [-1600|1612.75] "A" Vector__XXX
 SG_ NetBatteryCurrent : 16|16@1+ (0.05,-1600) [-1600|1612.75] "A" Vector__XXX

BO_ 2566819326 VEP2: 8 Vector__XXX
 SG_ BatteryPotential_PowerInput2 : 0|16@1+ (0.05,0) [0|3212.75] "V" Vector__XXX
 SG_ ECUPowerOutputSupplyVoltage1 : 16|16@1+ (0.05,0) [0|3212.75] "V" Vector__XXX
 SG_ ECUPowerOutputSupplyVoltage2 : 32|16@1+ (0.05,0) [0|3212.75] "V" Vector__XXX
 SG_ ECUPowerOutputSupplyVoltage3 : 48|16@1+ (0.05,0) [0|3212.75] "V" Vector__XXX

BO_ 2566845438 VP: 8 Vector__XXX
 SG_ Latitude : 0|32@1+ (1,-210) [-210|4294970000] "deg" Vector__XXX
 SG_ Longitude : 32|32@1+ (1,-210) [-210|4294970000] "deg" Vector__XXX

BO_ 2566843646 VI: 8 Vector__XXX
 SG_ VehicleIdentificationNumber : 0|8@1+ (1.02,0) [0|255] "per byte" Vector__XXX

BO_ 2566842112 VH: 8 Vector__XXX
 SG_ TotalVehicleHours : 0|32@1+ (0.05,0) [0|210554000] "hr" Vector__XXX
 SG_ TotalPowerTakeoffHours : 32|32@1+ (0.05,0) [0|210554000] "hr" Vector__XXX

BO_ 2566809854 VF: 8 Vector__XXX
 SG_ HydTemp : 0|8@1+ (1,-40) [-40|210] "deg C" Vector__XXX
 SG_ HydOilFilterRestrictionSwitch : 8|2@1+ (1,0) [0|3] "" Vector__XXX
 SG_ WinchOilPressSwitch : 10|2@1+ (1,0) [0|3] "" Vector__XXX
 SG_ HydOilLevel : 16|8@1+ (0.4,0) [0|100] "%" Vector__XXX

BO_ 2566842622 VDS: 8 Vector__XXX
 SG_ CompassBearing : 0|16@1+ (0.007812,0) [0|501.96] "deg" Vector__XXX
 SG_ NavigationBasedVehicleSpeed : 16|16@1+ (0.003906,0) [0|250.98] "km/h" Vector__XXX
 SG_ Pitch : 32|16@1+ (0.007812,-200) [-200|301.96] "deg" Vector__XXX
 SG_ Altitude : 48|16@1+ (0.125,-2500) [-2500|5531.88] "m" Vector__XXX

BO_ 2566832384 VDHR: 8 Vector__XXX
 SG_ HghRsolutionTotalVehicleDistance : 0|32@1+ (0.005,0) [0|21055400] "km" Vector__XXX
 SG_ HighResolutionTripDistance : 32|32@1+ (0.005,0) [0|21055400] "km" Vector__XXX

BO_ 2565867787 VDC2: 8 Vector__XXX
 SG_ SteerWheelAngle : 0|16@1+ (0.000977,-31.374) [-31.374|31.4031] "rad" Vector__XXX
 SG_ SteerWheelTurnCounter : 16|6@1+ (1,-32) [-32|29] "turns" Vector__XXX
 SG_ SteerWheelAngleSensorType : 22|2@1+ (1,0) [0|3] "" Vector__XXX
 SG_ YawRate : 24|16@1+ (0.0001220703125,-3.92) [-3.92|4.0798779296875] "rad/s" Vector__XXX
 SG_ LateralAcceleration : 40|16@1+ (0.000488,-15.687) [-15.687|15.6694] "m/s^2" Vector__XXX
 SG_ LongitudinalAcceleration : 56|8@1+ (0.1,-12.5) [-12.5|12.5] "m/s^2"  VCU

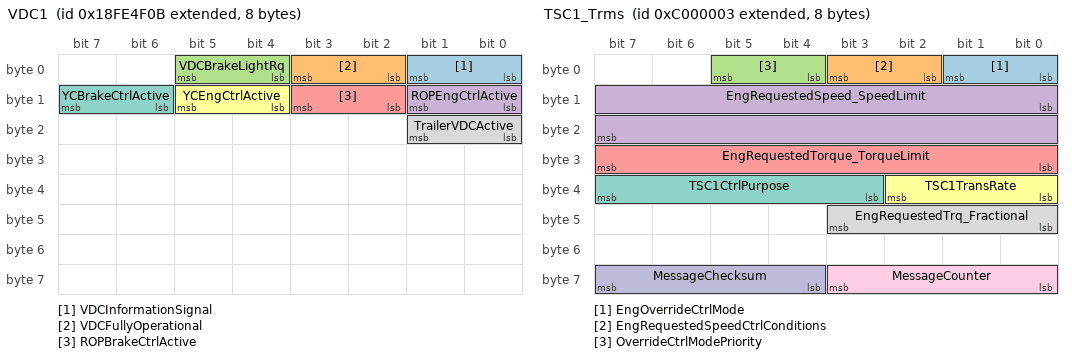
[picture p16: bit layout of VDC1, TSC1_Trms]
BO_ 2566803211 VDC1: 8 Vector__XXX
 SG_ VDCInformationSignal : 0|2@1+ (1,0) [0|3] "" Vector__XXX
 SG_ VDCFullyOperational : 2|2@1+ (1,0) [0|3] "" Vector__XXX
 SG_ VDCBrakeLightRq : 4|2@1+ (1,0) [0|3] "" Vector__XXX
 SG_ ROPEngCtrlActive : 8|2@1+ (1,0) [0|3] "" Vector__XXX
 SG_ ROPBrakeCtrlActive : 10|2@1+ (1,0) [0|3] "" Vector__XXX
 SG_ YCEngCtrlActive : 12|2@1+ (1,0) [0|3] "" Vector__XXX
 SG_ YCBrakeCtrlActive : 14|2@1+ (1,0) [0|3] "" Vector__XXX
 SG_ TrailerVDCActive : 16|2@1+ (1,0) [0|3] "" Vector__XXX

BO_ 2566840320 VD: 8 Vector__XXX
 SG_ TripDistance : 0|32@1+ (0.125,0) [0|526385000] "km" Vector__XXX
 SG_ TotalVehicleDistance : 32|32@1+ (0.125,0) [0|526385000] "km" Vector__XXX

BO_ 2633938686 TVI: 8 Vector__XXX
 SG_ TripMaxVehicleSpeed : 0|16@1+ (0.003906,0) [0|250.98] "km/h" Vector__XXX
 SG_ TripCruiseDistance : 16|32@1+ (0.125,0) [0|526385000] "km" Vector__XXX

BO_ 2633938430 TSI: 8 Vector__XXX
 SG_ TripNumberOfHotShutdowns : 0|16@1+ (1,0) [0|64255] "counts" Vector__XXX
 SG_ TripNumberOfIdleShutdowns : 16|16@1+ (1,0) [0|64255] "counts" Vector__XXX
 SG_ TrpNumberOfIdleShutdownOverrides : 32|16@1+ (1,0) [0|64255] "counts" Vector__XXX
 SG_ TripSuddenDecelerations : 48|16@1+ (1,0) [0|64255] "counts" Vector__XXX

BO_ 2348810243 TSC1_Trms: 8 Vector__XXX
 SG_ EngOverrideCtrlMode : 0|2@1+ (1,0) [0|3] "" Vector__XXX
 SG_ EngRequestedSpeedCtrlConditions : 2|2@1+ (1,0) [0|3] "" Vector__XXX
 SG_ OverrideCtrlModePriority : 4|2@1+ (1,0) [0|3] "" Vector__XXX
 SG_ EngRequestedSpeed_SpeedLimit : 8|16@1+ (0.125,0) [0|8031.88] "rpm" Vector__XXX
 SG_ EngRequestedTorque_TorqueLimit : 24|8@1+ (1,-125) [-125|125] "%" Vector__XXX
 SG_ TSC1TransRate : 32|3@1+ (1,0) [0|7] "" Vector__XXX
 SG_ TSC1CtrlPurpose : 35|5@1+ (1,0) [0|31] "" Vector__XXX
 SG_ EngRequestedTrq_Fractional : 40|4@1+ (0.125,0) [0|0.875] "%" Vector__XXX
 SG_ MessageCounter : 56|4@1+ (1,0) [0|15] "" Vector__XXX
 SG_ MessageChecksum : 60|4@1+ (1,0) [0|15] "" Vector__XXX

BO_ 2566766846 TR7: 8 Vector__XXX
 SG_ TypeOfPassengerCount : 0|8@1+ (1.02,0) [0|255] "" Vector__XXX
 SG_ PatronCount : 8|8@1+ (1,0) [0|250] "" Vector__XXX
 SG_ SilentAlarmStatus : 16|2@1+ (1,0) [0|3] "" Vector__XXX
 SG_ VehicleUseStatus : 18|2@1+ (1,0) [0|3] "" Vector__XXX
 SG_ TransitRunStatus : 20|2@1+ (1,0) [0|3] "" Vector__XXX

BO_ 2566765310 TR6: 8 Vector__XXX
 SG_ FareboxEmergencyStatus : 0|2@1+ (1,0) [0|3] "" Vector__XXX
 SG_ FareboxAlarmIdentifier : 8|7@1+ (1,0) [0|127] "" Vector__XXX

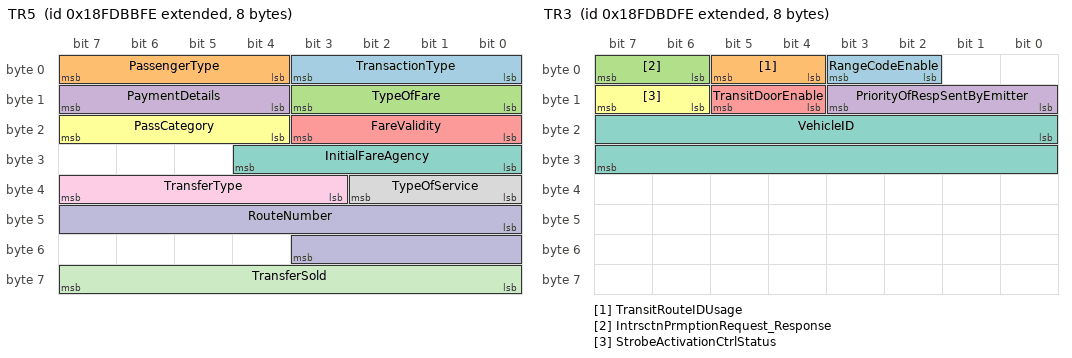
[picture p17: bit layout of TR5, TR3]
BO_ 2566765566 TR5: 8 Vector__XXX
 SG_ TransactionType : 0|4@1+ (1,0) [0|15] "" Vector__XXX
 SG_ PassengerType : 4|4@1+ (1,0) [0|15] "" Vector__XXX
 SG_ TypeOfFare : 8|4@1+ (1,0) [0|15] "" Vector__XXX
 SG_ PaymentDetails : 12|4@1+ (1,0) [0|15] "" Vector__XXX
 SG_ FareValidity : 16|4@1+ (1,0) [0|15] "" Vector__XXX
 SG_ PassCategory : 20|4@1+ (1,0) [0|15] "" Vector__XXX
 SG_ InitialFareAgency : 24|5@1+ (1,0) [0|31] "" Vector__XXX
 SG_ TypeOfService : 32|3@1+ (1,0) [0|7] "" Vector__XXX
 SG_ TransferType : 35|5@1+ (1,0) [0|31] "" Vector__XXX
 SG_ RouteNumber : 40|12@1+ (1,0) [0|4095] "" Vector__XXX
 SG_ TransferSold : 56|8@1+ (1.02,0) [0|255] "" Vector__XXX

BO_ 2566766078 TR3: 8 Vector__XXX
 SG_ RangeCodeEnable : 2|2@1+ (1,0) [0|3] "" Vector__XXX
 SG_ TransitRouteIDUsage : 4|2@1+ (1,0) [0|3] "" Vector__XXX
 SG_ IntrsctnPrmptionRequest_Response : 6|2@1+ (1,0) [0|3] "" Vector__XXX
 SG_ PriorityOfRespSentByEmitter : 8|4@1+ (1,0) [0|15] "" Vector__XXX
 SG_ TransitDoorEnable : 12|2@1+ (1,0) [0|3] "" Vector__XXX
 SG_ StrobeActivationCtrlStatus : 14|2@1+ (1,0) [0|3] "" Vector__XXX
 SG_ VehicleID : 16|16@1+ (1.01992,0) [0|65535] "counts" Vector__XXX

BO_ 2566766590 TR2: 8 Vector__XXX
 SG_ NmbrOfBytsInThMlpstIdntification : 0|8@1+ (1,0) [0|250] "" Vector__XXX

BO_ 2566766334 TR1: 8 Vector__XXX
 SG_ Agency : 0|8@1+ (1.02,0) [0|255] "" Vector__XXX
 SG_ NmbrOfBytsInThTrnstAssgndRtIdntt : 8|8@1+ (1,0) [0|250] "" Vector__XXX
 SG_ NmbrOfBytsInThTrnstAssgndRnIdntt : 16|8@1+ (1,0) [0|250] "" Vector__XXX
 SG_ NmbrOfBytsInThTrnstAssgndBlckIdn : 24|8@1+ (1,0) [0|250] "" Vector__XXX

BO_ 2561605374 TPRS: 8 Vector__XXX
 SG_ TireLocation : 0|8@1+ (1,0) [0|255] "" Vector__XXX
 SG_ ReferenceTirePressSetting_00 : 8|8@1+ (8,0) [0|2000] "kPa" Vector__XXX
 SG_ ReferenceTirePressSetting_01 : 8|8@1+ (8,0) [0|2000] "kPa" Vector__XXX
 SG_ ReferenceTirePressSetting_10 : 8|8@1+ (8,0) [0|2000] "kPa" Vector__XXX
 SG_ ReferenceTirePressSetting_11 : 8|8@1+ (8,0) [0|2000] "kPa" Vector__XXX
 SG_ ReferenceTirePressSetting_12 : 8|8@1+ (8,0) [0|2000] "kPa" Vector__XXX
 SG_ ReferenceTirePressSetting_13 : 8|8@1+ (8,0) [0|2000] "kPa" Vector__XXX
 SG_ ReferenceTirePressSetting_20 : 8|8@1+ (8,0) [0|2000] "kPa" Vector__XXX
 SG_ ReferenceTirePressSetting_21 : 8|8@1+ (8,0) [0|2000] "kPa" Vector__XXX
 SG_ ReferenceTirePressSetting_22 : 8|8@1+ (8,0) [0|2000] "kPa" Vector__XXX
 SG_ ReferenceTirePressSetting_23 : 8|8@1+ (8,0) [0|2000] "kPa" Vector__XXX
 SG_ ReferenceTirePressSetting_30 : 8|8@1+ (8,0) [0|2000] "kPa" Vector__XXX
 SG_ ReferenceTirePressSetting_31 : 8|8@1+ (8,0) [0|2000] "kPa" Vector__XXX
 SG_ ReferenceTirePressSetting_32 : 8|8@1+ (8,0) [0|2000] "kPa" Vector__XXX
 SG_ ReferenceTirePressSetting_33 : 8|8@1+ (8,0) [0|2000] "kPa" Vector__XXX

BO_ 2566765054 TPRI: 8 Vector__XXX
 SG_ TireLocation : 0|8@1+ (1,0) [0|255] "" Vector__XXX
 SG_ ReferenceTirePress_00 : 8|8@1+ (8,0) [0|2000] "kPa" Vector__XXX
 SG_ ReferenceTirePress_01 : 8|8@1+ (8,0) [0|2000] "kPa" Vector__XXX
 SG_ ReferenceTirePress_10 : 8|8@1+ (8,0) [0|2000] "kPa" Vector__XXX
 SG_ ReferenceTirePress_11 : 8|8@1+ (8,0) [0|2000] "kPa" Vector__XXX
 SG_ ReferenceTirePress_12 : 8|8@1+ (8,0) [0|2000] "kPa" Vector__XXX
 SG_ ReferenceTirePress_13 : 8|8@1+ (8,0) [0|2000] "kPa" Vector__XXX
 SG_ ReferenceTirePress_20 : 8|8@1+ (8,0) [0|2000] "kPa" Vector__XXX
 SG_ ReferenceTirePress_21 : 8|8@1+ (8,0) [0|2000] "kPa" Vector__XXX
 SG_ ReferenceTirePress_22 : 8|8@1+ (8,0) [0|2000] "kPa" Vector__XXX
 SG_ ReferenceTirePress_23 : 8|8@1+ (8,0) [0|2000] "kPa" Vector__XXX
 SG_ ReferenceTirePress_30 : 8|8@1+ (8,0) [0|2000] "kPa" Vector__XXX
 SG_ ReferenceTirePress_31 : 8|8@1+ (8,0) [0|2000] "kPa" Vector__XXX
 SG_ ReferenceTirePress_32 : 8|8@1+ (8,0) [0|2000] "kPa" Vector__XXX
 SG_ ReferenceTirePress_33 : 8|8@1+ (8,0) [0|2000] "kPa" Vector__XXX

BO_ 2633923326 TP3: 8 Vector__XXX
 SG_ TrailerTagOrPushChannelTirePress : 0|16@1+ (0.5,0) [0|32127.5] "kPa" Vector__XXX
 SG_ DriveChannelTirePress : 16|16@1+ (0.5,0) [0|32127.5] "kPa" Vector__XXX
 SG_ SteerChannelTirePress : 32|16@1+ (0.5,0) [0|32127.5] "kPa" Vector__XXX

BO_ 2633923070 TP2: 8 Vector__XXX
 SG_ TrlrTgOrPshChnnelTirePressTarget : 0|16@1+ (0.5,0) [0|32127.5] "kPa" Vector__XXX
 SG_ DriveChannelTirePressTarget : 16|16@1+ (0.5,0) [0|32127.5] "kPa" Vector__XXX
 SG_ SteerChannelTirePressTarget : 32|16@1+ (0.5,0) [0|32127.5] "kPa" Vector__XXX

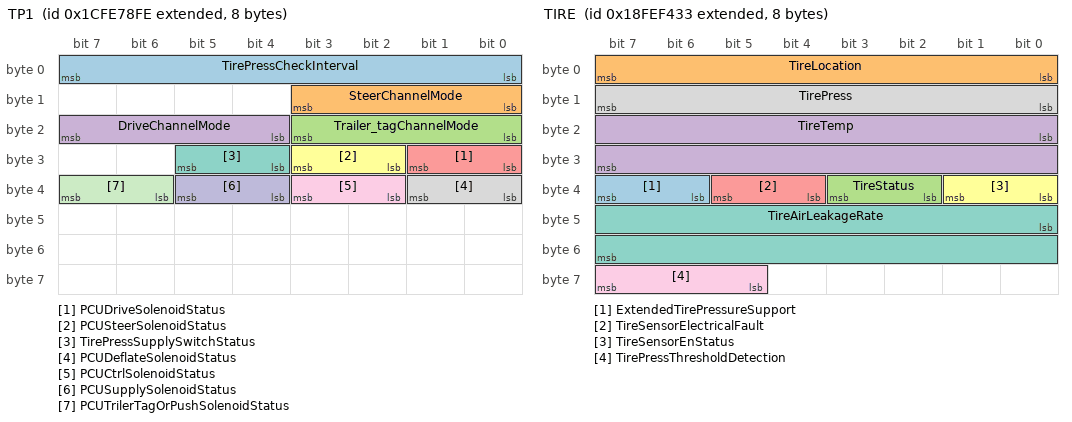
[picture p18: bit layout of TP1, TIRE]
BO_ 2633922814 TP1: 8 Vector__XXX
 SG_ TirePressCheckInterval : 0|8@1+ (1,0) [0|250] "mins" Vector__XXX
 SG_ SteerChannelMode : 8|4@1+ (1,0) [0|15] "" Vector__XXX
 SG_ Trailer_tagChannelMode : 16|4@1+ (1,0) [0|15] "" Vector__XXX
 SG_ DriveChannelMode : 20|4@1+ (1,0) [0|15] "" Vector__XXX
 SG_ PCUDriveSolenoidStatus : 24|2@1+ (1,0) [0|3] "" Vector__XXX
 SG_ PCUSteerSolenoidStatus : 26|2@1+ (1,0) [0|3] "" Vector__XXX
 SG_ TirePressSupplySwitchStatus : 28|2@1+ (1,0) [0|3] "" Vector__XXX
 SG_ PCUDeflateSolenoidStatus : 32|2@1+ (1,0) [0|3] "" Vector__XXX
 SG_ PCUCtrlSolenoidStatus : 34|2@1+ (1,0) [0|3] "" Vector__XXX
 SG_ PCUSupplySolenoidStatus : 36|2@1+ (1,0) [0|3] "" Vector__XXX
 SG_ PCUTrilerTagOrPushSolenoidStatus : 38|2@1+ (1,0) [0|3] "" Vector__XXX

BO_ 2566845491 TIRE: 8 Vector__XXX
 SG_ ExtendedTirePressureSupport : 38|2@1+ (1,0) [0|3] "" Vector__XXX
 SG_ TireLocation : 0|8@1+ (1,0) [0|255] "" Vector__XXX
 SG_ TireStatus : 34|2@1+ (1,0) [0|3] "" Vector__XXX
 SG_ TireTemp : 16|16@1+ (0.03125,-273) [-273|1735] "°C" Vector__XXX
 SG_ TireSensorElectricalFault : 36|2@1+ (1,0) [0|3] "" Vector__XXX
 SG_ TireSensorEnStatus : 32|2@1+ (1,0) [0|3] "" Vector__XXX
 SG_ TireAirLeakageRate : 40|16@1+ (0.1,0) [0|6425.5] "Pa/s" Vector__XXX
 SG_ TirePress : 8|8@1+ (4,0) [0|1000] "kPa" Vector__XXX
 SG_ TirePressThresholdDetection : 61|3@1+ (1,0) [0|7] ""  VCU

BO_ 2564161278 TDA: 8 Vector__XXX
 SG_ AdjustSeconds : 0|8@1+ (0.25,0) [0|62.5] "s" Vector__XXX
 SG_ AdjustMinutes : 8|8@1+ (1,0) [0|250] "mins" Vector__XXX
 SG_ AdjustHours : 16|8@1+ (1,0) [0|250] "hr" Vector__XXX
 SG_ AdjustMonth : 24|8@1+ (1,0) [0|250] "months" Vector__XXX
 SG_ AdjustDay : 32|8@1+ (0.25,0) [0|62.5] "days" Vector__XXX
 SG_ AdjustYear : 40|8@1+ (1,1985) [1985|2235] "years" Vector__XXX
 SG_ AdjustLocalMinuteOffset : 48|8@1+ (1,-125) [-125|125] "mins" Vector__XXX
 SG_ AdjustLocalHourOffset : 56|8@1+ (1,-125) [-125|125] "hr" Vector__XXX

BO_ 2566841856 TD: 8 Vector__XXX
 SG_ Seconds : 0|8@1+ (1,0) [0|0] "sec" Vector__XXX
 SG_ Minutes : 8|8@1+ (1,0) [0|0] "min" Vector__XXX
 SG_ Hours : 16|8@1+ (1,0) [0|250] "hr" Vector__XXX
 SG_ Month : 24|8@1+ (1,0) [0|250] "months" Vector__XXX
 SG_ Day : 32|8@1+ (1,0) [0|0] "" Vector__XXX
 SG_ Year : 40|8@1+ (1,1985) [1985|2235] "years" Vector__XXX
 SG_ LocalMinuteOffset : 48|8@1+ (1,-125) [-125|125] "mins" Vector__XXX
 SG_ LocalHourOffset : 56|8@1+ (1,-125) [-125|125] "hr" Vector__XXX

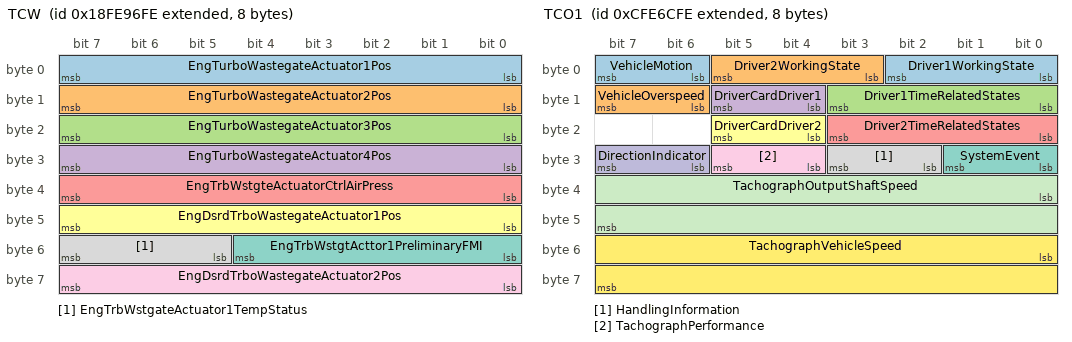
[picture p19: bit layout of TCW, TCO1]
BO_ 2566821630 TCW: 8 Vector__XXX
 SG_ EngTurboWastegateActuator1Pos : 0|8@1+ (0.4,0) [0|100] "%" Vector__XXX
 SG_ EngTurboWastegateActuator2Pos : 8|8@1+ (0.4,0) [0|100] "%" Vector__XXX
 SG_ EngTurboWastegateActuator3Pos : 16|8@1+ (0.4,0) [0|100] "%" Vector__XXX
 SG_ EngTurboWastegateActuator4Pos : 24|8@1+ (0.4,0) [0|100] "%" Vector__XXX
 SG_ EngTrbWstgteActuatorCtrlAirPress : 32|8@1+ (4,0) [0|1000] "kPa" Vector__XXX
 SG_ EngDsrdTrboWastegateActuator1Pos : 40|8@1+ (1,0) [0|100] "%" Vector__XXX
 SG_ EngTrbWstgtActtor1PreliminaryFMI : 48|5@1+ (1,0) [0|31] "" Vector__XXX
 SG_ EngTrbWstgateActuator1TempStatus : 53|3@1+ (1,0) [0|7] "" Vector__XXX
 SG_ EngDsrdTrboWastegateActuator2Pos : 56|8@1+ (1,0) [0|100] "%" Vector__XXX

BO_ 2365484286 TCO1: 8 Vector__XXX
 SG_ Driver1WorkingState : 0|3@1+ (1,0) [0|7] "" Vector__XXX
 SG_ Driver2WorkingState : 3|3@1+ (1,0) [0|7] "" Vector__XXX
 SG_ Driver1TimeRelatedStates : 8|4@1+ (1,0) [0|15] "" Vector__XXX
 SG_ DriverCardDriver1 : 12|2@1+ (1,0) [0|3] "" Vector__XXX
 SG_ Driver2TimeRelatedStates : 16|4@1+ (1,0) [0|15] "" Vector__XXX
 SG_ DriverCardDriver2 : 20|2@1+ (1,0) [0|3] "" Vector__XXX
 SG_ SystemEvent : 24|2@1+ (1,0) [0|3] "" Vector__XXX
 SG_ HandlingInformation : 26|2@1+ (1,0) [0|3] "" Vector__XXX
 SG_ TachographPerformance : 28|2@1+ (1,0) [0|3] "" Vector__XXX
 SG_ DirectionIndicator : 30|2@1+ (1,0) [0|3] "" Vector__XXX
 SG_ TachographOutputShaftSpeed : 32|16@1+ (0.125,0) [0|8031.88] "rpm" Vector__XXX
 SG_ TachographVehicleSpeed : 48|16@1+ (0.003906,0) [0|250.98] "km/h" Vector__XXX
 SG_ VehicleMotion : 6|2@1+ (1,0) [0|3] "" Vector__XXX
 SG_ VehicleOverspeed : 14|2@1+ (1,0) [0|3] "" Vector__XXX

BO_ 2566771710 TCI6: 8 Vector__XXX
 SG_ EngTurbo1CompressorOutletTemp : 0|16@1+ (0.03125,-273) [-273|1734.97] "deg C" Vector__XXX
 SG_ EngTurbo2CompressorOutletTemp : 16|16@1+ (0.03125,-273) [-273|1734.97] "deg C" Vector__XXX
 SG_ EngTurbo3CompressorOutletTemp : 32|16@1+ (0.03125,-273) [-273|1734.97] "deg C" Vector__XXX
 SG_ EngTurbo4CompressorOutletTemp : 48|16@1+ (0.03125,-273) [-273|1734.97] "deg C" Vector__XXX

BO_ 2566821886 TCI5: 8 Vector__XXX
 SG_ EngTurbo1TurbineOutletTemp : 0|16@1+ (0.03125,-273) [-273|1734.97] "deg C" Vector__XXX
 SG_ EngTurbo2TurbineOutletTemp : 16|16@1+ (0.03125,-273) [-273|1734.97] "deg C" Vector__XXX
 SG_ EngTurbo3TurbineOutletTemp : 32|16@1+ (0.03125,-273) [-273|1734.97] "deg C" Vector__XXX
 SG_ EngTurbo4TurbineOutletTemp : 48|16@1+ (0.03125,-273) [-273|1734.97] "deg C" Vector__XXX

BA_DEF_ BO_  "GenMsgCycleTime" INT 0 65535;
BA_DEF_DEF_  "GenMsgCycleTime" 0;
VAL_ 2364549630 PitchAngleExRangeCompensation 0 "On" 1 "Off" 2 "Error" 3 "Not Available" ;
VAL_ 2364549630 PitchAngleExRangeFigureOfMerit 0 "Pitch rate fully functional Data is within sensor specification" 1 "Pitch rate degraded Data is suspect due to environmental conditions" 2 "Error" 3 "Not available" ;
VAL_ 2364549630 RollAngleExRangeCompensation 0 "On" 1 "Off" 2 "Error" 3 "Not Available" ;
VAL_ 2364549630 RollAngleExRangeFigureOfMerit 0 "Roll rate fully functional Data is within sensor specification" 1 "Roll rate degraded Data is suspect due to environmental conditions" 2 "Error" 3 "Not available" ;
VAL_ 2499614462 DrvrOccpntClssfctionSystemStatus 0 "empty" 1 "child" 2 "small adult" 3 "adult" 4 "large adult" 5 "reserved" 6 "Error  Classification of occupant cannot be determined" 7 "not available" ;
VAL_ 2499614462 PssngrOccpntClssfctnSystemStatus 0 "empty" 1 "child" 2 "small adult" 4 "reserved" 3 "adult" ;
VAL_ 2499614462 OccpntClssificationSystem3Status 0 "empty" 1 "occupied" 2 "Error  Classification cannot be determined" 3 "not available" ;
VAL_ 2499614462 OccpntClssificationSystem4Status 0 "empty" 1 "occupied" 2 "Error  Classification cannot be determined" 3 "not available" ;
VAL_ 2499614462 OccpntClssificationSystem5Status 0 "empty" 1 "occupied" 2 "Error  Classification cannot be determined" 3 "not available" ;
VAL_ 2499614462 OccpntClssificationSystem6Status 0 "empty" 1 "occupied" 2 "Error  Classification cannot be determined" 3 "not available" ;
VAL_ 2499614462 OccpntClssificationSystem7Status 0 "empty" 1 "occupied" 2 "Error  Classification cannot be determined" 3 "not available" ;
VAL_ 2499614462 OccpntClssificationSystem8Status 0 "empty" 1 "occupied" 2 "Error  Classification cannot be determined" 3 "not available" ;
VAL_ 2499614462 OccpntClssificationSystem9Status 0 "empty" 1 "occupied" 2 "Error  Classification cannot be determined" 3 "not available" ;
VAL_ 2499614462 OccpntClssficationSystem10Status 0 "empty" 1 "occupied" 2 "Error  Classification cannot be determined" 3 "not available" ;
VAL_ 2560098046 CabNoiseCtrlStatus 0 "Cab Noise Control System ONLine" 1 "Cab Noise Control System OFFLine" 2 "Error Indicator" 3 "Not Available/Not Requested" ;
VAL_ 2560098046 CabNoiseCtrlTuningStatus 0 "Manual Tuning Mode" 1 "Manual Tuning Mode  Command Complete" 2 "Manual Tuning Mode  Saving Data" 13 "Reserved" 7 "Manual Tuning Denied  Requires Security Verification" 8 "Automatic Tuning Mode" 9 "Automatic Tuning Mode  Command Complete" 10 "Automatic Tuning Mode  Saving Data" 14 "Tuning Mode  Error" 15 "Not Available/Not Tuning/Not Requested" 3 "Reserved" 4 "Reserved" 5 "Reserved" 6 "Reserved" 11 "Reserved" 12 "Reserved" ;
VAL_ 2560163582 CabNoiseCtrlState 0 "Take Cab Noise Control System Off Line" 1 "Bring Cab Noise Control System On Line" 2 "Reserved" 3 "Dont Care/Not Commanded" ;
VAL_ 2560163582 CabNoiseCtrlTuningState 0 "Activate Manual Tuning Wait for Save and Exit Commands" 1 "Activate Automatic Tuning Wait for Save and Exit Commands" 2 "Activate Automatic Tuning State Saveing Parameters Exit on Completion" 3 "Remain In Tuning Save Current Parameters" 4 "Exit Tuning Not Saving Parameters" 5 "Exit Tuning Saving Parameters" 6 "Reserved" 7 "Dont Care NOT Commanded" ;
VAL_ 2297441534 MaterialLiftSwitch 0 "Dont Lift" 1 "Lift" 2 "Error" 3 "Not Available" ;
VAL_ 2297441534 MaterialDropSwitch 0 "Dont Drop" 1 "Drop" 2 "Error" 3 "Not Available" ;
VAL_ 2297441534 GneratorCurrentBoostActiveStatus 0 "Off" 1 "On" 2 "Error" 3 "Not Available" ;
VAL_ 2297441534 MaterialLiftActiveStatus 0 "Off" 1 "On" 2 "Error" 3 "Not Available" ;
VAL_ 2297441534 MaterialDropActiveStatus 0 "Off" 1 "On" 2 "Error" 3 "Not Available" ;
VAL_ 2297441534 LiftRelayCtrl 0 "Off Disable Lift Relay Request" 1 "On Enable Lift Relay Request" 2 "Reserved" 3 "Take No Action" ;
VAL_ 2297441534 DropRelayCtrl 0 "Off Disable Drop Relay Request" 1 "On Enable Drop Relay Request" 2 "Reserved" 3 "Take No Action" ;
VAL_ 2566722302 GeneratorOverheatStatus 0 "Not Overheat" 1 "Overheat" 2 "Error" 3 "Not Available" ;
VAL_ 2566722302 GnstSystmOtputVoltageRangeStatus 0 "Out of Range" 1 "In Range" 2 "Error" 3 "Not Available" ;
VAL_ 2566722302 Grapple_MagnetSelectionSwitch 0 "Grapple Selected" 1 "Magnet Selected" 2 "Error" 3 "Not Available" ;
VAL_ 2566722302 GensetSoftstartActiveStatus 0 "Off" 1 "On" 2 "Error" 3 "Not Available" ;
VAL_ 2566722302 ReverseCurrentRangeSetting 0 "1" 1 "2" 2 "3" 3 "4" 4 "5" 5 "6" 6 "7" 7 "8" 8 "9" 9 "10" 10 "11" 11 "12" 12 "13" 13 "14" 14 "15" 15 "16" 30 "Error" 31 "Not Available" ;
VAL_ 2566722302 GensetEnableActiveStatus 0 "Not Enabled" 1 "Enabled" 2 "Error" 3 "Not Avaialble" ;
VAL_ 2566722302 VoltageMonitorActiveStatus 0 "Monitor is Off" 1 "Monitor is On" 2 "Error" 3 "Not Available" ;
VAL_ 2566722302 GeneratorDutyCycleExceededStatus 0 "Duty Cycle Not Exceed" 1 "Duty Cycle Exceed" 2 "Error" 3 "Not Avaiable" ;
VAL_ 2560032510 LwVltgDscnnctDsiredOperatingMode 0 "Automatic" 4 "Manual Disconnect" 5 "Manual Connect" 15 "No change" ;
VAL_ 2566717950 LwVltgDscnnctMnalDisconnectState 0 "Input off" 1 "Input on" 2 "Error" 3 "Not installed" ;
VAL_ 2566717950 LwVltgDscnnectManualConnectState 0 "Input off" 1 "Input on" 2 "Error" 3 "Not installed" ;
VAL_ 2566717950 LwVltgDscnnctCrrentOperatingMode 0 "Automatic" 4 "Manual Disconnect via J1939 request" 5 "Manual Connect via J1939 request" 8 "Manual Disconnect via hardwired input" 9 "Manual Connect via hardwired input" 15 "Not available" ;
VAL_ 2566717950 LowVoltageDisconnectOutput3State 0 "Output off or disconnected" 1 "Output on or connected" 2 "Disconnect alarm expired output off or disconnected" 3 "Disconnect pending alarm active" 4 "Connect pending alarm active" 14 "Output fault" 15 "Not available or not installed" ;
VAL_ 2566717950 LowVoltageDisconnectOutput2State 0 "Output off or disconnected" 1 "Output on or connected" 2 "Disconnect alarm expired output off or disconnected" 3 "Disconnect pending alarm active" 4 "Connect pending alarm active" 14 "Output fault" 15 "Not available or not installed" ;
VAL_ 2566717950 LowVoltageDisconnectOutput1State 0 "Output off or disconnected" 1 "Output on or connected" 2 "Disconnect alarm expired output off or disconnected" 3 "Disconnect pending alarm active" 4 "Connect pending alarm active" 14 "Output fault" 15 "Not available or not installed" ;
VAL_ 2566717950 LwVltgeDisconnectVoutOutputState 0 "Output off or disconnected" 1 "Output on or connected" 2 "Disconnect alarm expired output off or disconnected" 3 "Disconnect pending alarm active" 4 "Connect pending alarm active" 14 "Output fault" 15 "Not available or not installed" ;
VAL_ 2358902526 Joystick1Lamp1Cmd 0 "Off" 1 "On" 2 "Blinking" 3 "Not available or not installed" ;
VAL_ 2358902526 Joystick1Lamp2Cmd 0 "Off" 1 "On" 2 "Blinking" 3 "Not available or not installed" ;
VAL_ 2358902526 Joystick1Lamp3Cmd 0 "Off" 1 "On" 2 "Blinking" 3 "Not available or not installed" ;
VAL_ 2358902526 Joystick1Lamp4Cmd 0 "Off" 1 "On" 2 "Blinking" 3 "Not available or not installed" ;
VAL_ 2358902526 Joystick1Lamp5Cmd 0 "Off" 1 "On" 2 "Blinking" 3 "Not available or not installed" ;
VAL_ 2358902526 Joystick1Lamp6Cmd 0 "Off" 1 "On" 2 "Blinking" 3 "Not available or not installed" ;
VAL_ 2358902526 Joystick1Lamp7Cmd 0 "Off" 1 "On" 2 "Blinking" 3 "Not available or not installed" ;
VAL_ 2358902526 Joystick1Lamp8Cmd 0 "Off" 1 "On" 2 "Blinking" 3 "Not available or not installed" ;
VAL_ 2358902526 Joystick1Lamp9Cmd 0 "Off" 1 "On" 2 "Blinking" 3 "Not available or not installed" ;
VAL_ 2358902526 Joystick1Lamp10Cmd 0 "Off" 1 "On" 2 "Blinking" 3 "Not available or not installed" ;
VAL_ 2358902526 Joystick2Lamp1Cmd 0 "Off" 1 "On" 2 "Blinking" 3 "Not available or not installed" ;
VAL_ 2358902526 Joystick2Lamp2Cmd 0 "Off" 1 "On" 2 "Blinking" 3 "Not available or not installed" ;
VAL_ 2358902526 Joystick2Lamp3Cmd 0 "Off" 1 "On" 2 "Blinking" 3 "Not available or not installed" ;
VAL_ 2358902526 Joystick2Lamp4Cmd 0 "Off" 1 "On" 2 "Blinking" 3 "Not available or not installed" ;
VAL_ 2358902526 Joystick2Lamp5Cmd 0 "Off" 1 "On" 2 "Blinking" 3 "Not available or not installed" ;
VAL_ 2358902526 Joystick2Lamp6Cmd 0 "Off" 1 "On" 2 "Blinking" 3 "Not available or not installed" ;
VAL_ 2358902526 Joystick2Lamp7Cmd 0 "Off" 1 "On" 2 "Blinking" 3 "Not available or not installed" ;
VAL_ 2358902526 Joystick2Lamp8Cmd 0 "Off" 1 "On" 2 "Blinking" 3 "Not available or not installed" ;
VAL_ 2358902526 Joystick2Lamp9Cmd 0 "Off" 1 "On" 2 "Blinking" 3 "Not available or not installed" ;
VAL_ 2358902526 Joystick2Lamp10Cmd 0 "Off" 1 "On" 2 "Blinking" 3 "Not available or not installed" ;
VAL_ 2358902526 Joystick3Lamp1Cmd 0 "Off" 1 "On" 2 "Blinking" 3 "Not available or not installed" ;
VAL_ 2358902526 Joystick3Lamp2Cmd 0 "Off" 1 "On" 2 "Blinking" 3 "Not available or not installed" ;
VAL_ 2358902526 Joystick3Lamp3Cmd 0 "Off" 1 "On" 2 "Blinking" 3 "Not available or not installed" ;
VAL_ 2358902526 Joystick3Lamp4Cmd 0 "Off" 1 "On" 2 "Blinking" 3 "Not available or not installed" ;
VAL_ 2358902526 Joystick3Lamp5Cmd 0 "Off" 1 "On" 2 "Blinking" 3 "Not available or not installed" ;
VAL_ 2358902526 Joystick3Lamp6Cmd 0 "Off" 1 "On" 2 "Blinking" 3 "Not available or not installed" ;
VAL_ 2358902526 Joystick3Lamp7Cmd 0 "Off" 1 "On" 2 "Blinking" 3 "Not available or not installed" ;
VAL_ 2358902526 Joystick3Lamp8Cmd 0 "Off" 1 "On" 2 "Blinking" 3 "Not available or not installed" ;
VAL_ 2358902526 Joystick3Lamp9Cmd 0 "Off" 1 "On" 2 "Blinking" 3 "Not available or not installed" ;
VAL_ 2358902526 Joystick3Lamp10Cmd 0 "Off" 1 "On" 2 "Blinking" 3 "Not available or not installed" ;
VAL_ 2566711550 IntkVlvActtnSystmOlPrss1SlndCtrl 0 "off" 1 "on" 2 "reserved for SAE assignment" 3 "not available" ;
VAL_ 2566711550 IntkVlvActtnSystmOlPrss2SlndCtrl 0 "off" 1 "on" 2 "reserved for SAE assignment" 3 "not available" ;
VAL_ 2566713854 EngTrbWstgateActuator2TempStatus 0 "High most severe" 1 "High Least severe" 2 "In Range" 3 "Low Least severe" 4 "Low Most severe" 5 "Not Defined" 6 "Error" 7 "Not available" ;
VAL_ 2566713854 EngTrbWstgtActtr1OperationStatus 0 "Normal" 1 "Alarm" 2 "AlarmHighSeverity" 3 "DerateActive" 4 "CtrlledShutdownActive" 5 "UnCtrlledShutdownActive" 6 "1101ReservedForFutureAssignment" 14 "Error" ;
VAL_ 2566713854 EngTrbWstgtActtr2OperationStatus 0 "Normal" 1 "Alarm" 2 "AlarmHighSeverity" 3 "DerateActive" 4 "CtrlledShutdownActive" 5 "UnCtrlledShutdownActive" 6 "1101ReservedForFutureAssignment" 14 "Error" ;
VAL_ 2566714366 EngTrbCmprssrBypssActtr2TmpSttus 0 "High most severe" 1 "High Least severe" 2 "In Range" 3 "Low Least severe" 4 "Low Most severe" 5 "Not Defined" 6 "Error" 7 "Not available" ;
VAL_ 2566714366 EngTrbCmprssrBypssActtr1OprtnStt 0 "Normal" 1 "Alarm" 2 "AlarmHighSeverity" 3 "DerateActive" 4 "CtrlledShutdownActive" 5 "UnCtrlledShutdownActive" 6 "1101ReservedForFutureAssignment" 14 "Error" ;
VAL_ 2566714366 EngTrbCmprssrBypssActtr2OprtnStt 0 "Normal" 1 "Alarm" 2 "AlarmHighSeverity" 3 "DerateActive" 4 "CtrlledShutdownActive" 5 "UnCtrlledShutdownActive" 6 "1101ReservedForFutureAssignment" 14 "Error" ;
VAL_ 2566714110 EngThrottleValve1TempStatus 0 "High most severe" 1 "High Least severe" 2 "In Range" 3 "Low Least severe" 4 "Low Most severe" 5 "Not Defined" 6 "Error" 7 "Not available" ;
VAL_ 2566714110 EngThrottleValve2TempStatus 0 "High Most severe" 1 "High Least severe" 2 "In Range" 3 "Low Least severe" 4 "Low Most severe" 5 "Not Defined" 6 "Error" 7 "Not available" ;
VAL_ 2566714110 EngFuelValve1TempStatus 0 "High Most severe" 1 "High Least severe" 2 "In Range" 3 "Low Least severe" 4 "Low Most severe" 5 "Not Defined" 6 "Error" 7 "Not available" ;
VAL_ 2566714110 EngFuelValve2TempStatus 0 "High most severe" 1 "High Least severe" 2 "In Range" 3 "Low Least severe" 4 "Low Most severe" 5 "Not Defined" 6 "Error" 7 "Not available" ;
VAL_ 2566714110 EngThrottleValve1OperationStatus 0 "Normal" 1 "Alarm fully operational but needs service" 2 "Alarm High Severity functional but transient performance may be reduced" 3 "Derate Active torque output reduced due to environmental conditions" 4 "Controlled Shutdown Active driving to the default position  usually this means closed" 5 "Uncontrolled Shutdown Active actuator current is off so it is limp" 6 "1101 Reserved for future assignment" 14 "Error" 15 "Not available" ;
VAL_ 2566714110 EngThrottleValve2OperationStatus 0 "Normal" 1 "Alarm" 2 "AlarmHighSeverity" 3 "DerateActive" 4 "CtrlledShutdownActive" 5 "UnCtrlledShutdownActive" 6 "1101ReservedForFutureAssignment" 14 "Error" ;
VAL_ 2566714110 EngFuelValve1OperationStatus 0 "Normal" 1 "Alarm" 2 "AlarmHighSeverity" 3 "DerateActive" 4 "CtrlledShutdownActive" 5 "UnCtrlledShutdownActive" 6 "1101ReservedForFutureAssignment" 14 "Error" ;
VAL_ 2566714110 EngFuelValve2OperationStatus 0 "Normal" 1 "Alarm" 2 "AlarmHighSeverity" 3 "DerateActive" 4 "CtrlledShutdownActive" 5 "UnCtrlledShutdownActive" 6 "1101ReservedForFutureAssignment" 14 "Error" ;
VAL_ 2365400574 Jystck9GripXAxisNeutralPosStatus 0 "Not in Neutral Position" 1 "In Neutral Position" 2 "Error Indicator" 3 "Not Available" ;
VAL_ 2365400574 Jystck9GrpXAxsLvrLftNgtvPsStatus 0 "Not on negative side of Neutral" 1 "On negative side of Neutral" 2 "Error Indicator" 3 "Not Available" ;
VAL_ 2365400574 Jystck9GrpXAxsLvrRghtPstvPsSttus 0 "Not on Positive side of Neutral" 1 "On positive side of Neutral" 2 "Error Indicator" 3 "Not Available" ;
VAL_ 2365400574 Jystck9GripYAxisNeutralPosStatus 0 "Not in Neutral Position" 1 "In Neutral Position" 2 "Error Indicator" 3 "Not Available" ;
VAL_ 2365400574 Jystck9GrpYAxsLvrBckNgtvPsStatus 0 "Not on negative side of Neutral" 1 "On negative side of Neutral" 2 "Error Indicator" 3 "Not Available" ;
VAL_ 2365400574 Jystck9GrpYAxsLvrFrwrdPstvPsStts 0 "Not on Positive side of Neutral" 1 "On positive side of Neutral" 2 "Error Indicator" 3 "Not Available" ;
VAL_ 2365400574 Jystck9ThetaAxisNeutralPosStatus 0 "Not in Neutral Position" 1 "In Neutral Position" 2 "Error Indicator" 3 "Not Available" ;
VAL_ 2365400574 Jystck9ThtAxsCntrClckwsNgtvPsStt 0 "Not on negative side of Neutral" 1 "On negative side of Neutral" 2 "Error Indicator" 3 "Not Available" ;
VAL_ 2365400574 Jystck9ThtAxsClckwsPstvPosStatus 0 "Not on Positive side of Neutral" 1 "On positive side of Neutral" 2 "Error Indicator" 3 "Not Available" ;
VAL_ 2365400574 Jystick9ThetaAxisDetentPosStatus 0 "Not in the Detent Position" 1 "In the Detent Position" 2 "Error Indicator" 3 "Not Available" ;
VAL_ 2365400574 Jystick9GripYAxisDetentPosStatus 0 "Not in the Detent Position" 1 "In the Detent Position" 2 "Error Indicator" 3 "Not Available" ;
VAL_ 2365400574 Jystick9GripXAxisDetentPosStatus 0 "Not in the Detent Position" 1 "In the Detent Position" 2 "Error Indicator" 3 "Not Available" ;
VAL_ 2365401086 Jystck8GripXAxisNeutralPosStatus 0 "Not in Neutral Position" 1 "In Neutral Position" 2 "Error Indicator" 3 "Not Available" ;
VAL_ 2365401086 Jystck8GrpXAxsLvrLftNgtvPsStatus 0 "Not on negative side of Neutral" 1 "On negative side of Neutral" 2 "Error Indicator" 3 "Not Available" ;
VAL_ 2365401086 Jystck8GrpXAxsLvrRghtPstvPsSttus 0 "Not on Positive side of Neutral" 1 "On positive side of Neutral" 2 "Error Indicator" 3 "Not Available" ;
VAL_ 2365401086 Jystck8GripYAxisNeutralPosStatus 0 "Not in Neutral Position" 1 "In Neutral Position" 2 "Error Indicator" 3 "Not Available" ;
VAL_ 2365401086 Jystck8GrpYAxsLvrBckNgtvPsStatus 0 "Not on negative side of Neutral" 1 "On negative side of Neutral" 2 "Error Indicator" 3 "Not Available" ;
VAL_ 2365401086 Jystck8GrpYAxsLvrFrwrdPstvPsStts 0 "Not on Positive side of Neutral" 1 "On positive side of Neutral" 2 "Error Indicator" 3 "Not Available" ;
VAL_ 2365401086 Jystck8ThetaAxisNeutralPosStatus 0 "Not in Neutral Position" 1 "In Neutral Position" 2 "Error Indicator" 3 "Not Available" ;
VAL_ 2365401086 Jystck8ThtAxsCntrClckwsNgtvPsStt 0 "Not on negative side of Neutral" 1 "On negative side of Neutral" 2 "Error Indicator" 3 "Not Available" ;
VAL_ 2365401086 Jystck8ThtAxsClckwsPstvPosStatus 0 "Not on Positive side of Neutral" 1 "On positive side of Neutral" 2 "Error Indicator" 3 "Not Available" ;
VAL_ 2365401086 Jystick8ThetaAxisDetentPosStatus 0 "Not in the Detent Position" 1 "In the Detent Position" 2 "Error Indicator" 3 "Not Available" ;
VAL_ 2365401086 Jystick8GripYAxisDetentPosStatus 0 "Not in the Detent Position" 1 "In the Detent Position" 2 "Error Indicator" 3 "Not Available" ;
VAL_ 2365401086 Jystick8GripXAxisDetentPosStatus 0 "Not in the Detent Position" 1 "In the Detent Position" 2 "Error Indicator" 3 "Not Available" ;
VAL_ 2365401598 Jystck7GripXAxisNeutralPosStatus 0 "Not in Neutral Position" 1 "In Neutral Position" 2 "Error Indicator" 3 "Not Available" ;
VAL_ 2365401598 Jystck7GrpXAxsLvrLftNgtvPsStatus 0 "Not on negative side of Neutral" 1 "On negative side of Neutral" 2 "Error Indicator" 3 "Not Available" ;
VAL_ 2365401598 Jystck7GrpXAxsLvrRghtPstvPsSttus 0 "Not on Positive side of Neutral" 1 "On positive side of Neutral" 2 "Error Indicator" 3 "Not Available" ;
VAL_ 2365401598 Jystck7GripYAxisNeutralPosStatus 0 "Not in Neutral Position" 1 "In Neutral Position" 2 "Error Indicator" 3 "Not Available" ;
VAL_ 2365401598 Jystck7GrpYAxsLvrBckNgtvPsStatus 0 "Not on negative side of Neutral" 1 "On negative side of Neutral" 2 "Error Indicator" 3 "Not Available" ;
VAL_ 2365401598 Jystck7GrpYAxsLvrFrwrdPstvPsStts 0 "Not on Positive side of Neutral" 1 "On positive side of Neutral" 2 "Error Indicator" 3 "Not Available" ;
VAL_ 2365401598 Jystck7ThetaAxisNeutralPosStatus 0 "Not in Neutral Position" 1 "In Neutral Position" 2 "Error Indicator" 3 "Not Available" ;
VAL_ 2365401598 Jystck7ThtAxsCntrClckwsNgtvPsStt 0 "Not on negative side of Neutral" 1 "On negative side of Neutral" 2 "Error Indicator" 3 "Not Available" ;
VAL_ 2365401598 Jystck7ThtAxsClckwsPstvPosStatus 0 "Not on Positive side of Neutral" 1 "On positive side of Neutral" 2 "Error Indicator" 3 "Not Available" ;
VAL_ 2365401598 Jystick7ThetaAxisDetentPosStatus 0 "Not in the Detent Position" 1 "In the Detent Position" 2 "Error Indicator" 3 "Not Available" ;
VAL_ 2365401598 Jystick7GripYAxisDetentPosStatus 0 "Not in the Detent Position" 1 "In the Detent Position" 2 "Error Indicator" 3 "Not Available" ;
VAL_ 2365401598 Jystick7GripXAxisDetentPosStatus 0 "Not in the Detent Position" 1 "In the Detent Position" 2 "Error Indicator" 3 "Not Available" ;
VAL_ 2365402110 Jystck6GripXAxisNeutralPosStatus 0 "Not in Neutral Position" 1 "In Neutral Position" 2 "Error Indicator" 3 "Not Available" ;
VAL_ 2365402110 Jystck6GrpXAxsLvrLftNgtvPsStatus 0 "Not on negative side of Neutral" 1 "On negative side of Neutral" 2 "Error Indicator" 3 "Not Available" ;
VAL_ 2365402110 Jystck6GrpXAxsLvrRghtPstvPsSttus 0 "Not on Positive side of Neutral" 1 "On positive side of Neutral" 2 "Error Indicator" 3 "Not Available" ;
VAL_ 2365402110 Jystck6GripYAxisNeutralPosStatus 0 "Not in Neutral Position" 1 "In Neutral Position" 2 "Error Indicator" 3 "Not Available" ;
VAL_ 2365402110 Jystck6GrpYAxsLvrBckNgtvPsStatus 0 "Not on negative side of Neutral" 1 "On negative side of Neutral" 2 "Error Indicator" 3 "Not Available" ;
VAL_ 2365402110 Jystck6GrpYAxsLvrFrwrdPstvPsStts 0 "Not on Positive side of Neutral" 1 "On positive side of Neutral" 2 "Error Indicator" 3 "Not Available" ;
VAL_ 2365402110 Jystck6ThetaAxisNeutralPosStatus 0 "Not in Neutral Position" 1 "In Neutral Position" 2 "Error Indicator" 3 "Not Available" ;
VAL_ 2365402110 Jystck6ThtAxsCntrClckwsNgtvPsStt 0 "Not on negative side of Neutral" 1 "On negative side of Neutral" 2 "Error Indicator" 3 "Not Available" ;
VAL_ 2365402110 Jystck6ThtAxsClckwsPstvPosStatus 0 "Not on Positive side of Neutral" 1 "On positive side of Neutral" 2 "Error Indicator" 3 "Not Available" ;
VAL_ 2365402110 Jystick6ThetaAxisDetentPosStatus 0 "Not in the Detent Position" 1 "In the Detent Position" 2 "Error Indicator" 3 "Not Available" ;
VAL_ 2365402110 Jystick6GripYAxisDetentPosStatus 0 "Not in the Detent Position" 1 "In the Detent Position" 2 "Error Indicator" 3 "Not Available" ;
VAL_ 2365402110 Jystick6GripXAxisDetentPosStatus 0 "Not in the Detent Position" 1 "In the Detent Position" 2 "Error Indicator" 3 "Not Available" ;
VAL_ 2365402622 Jystck5GripXAxisNeutralPosStatus 0 "Not in Neutral Position" 1 "In Neutral Position" 2 "Error Indicator" 3 "Not Available" ;
VAL_ 2365402622 Jystck5GrpXAxsLvrLftNgtvPsStatus 0 "Not on negative side of Neutral" 1 "On negative side of Neutral" 2 "Error Indicator" 3 "Not Available" ;
VAL_ 2365402622 Jystck5GrpXAxsLvrRghtPstvPsSttus 0 "Not on Positive side of Neutral" 1 "On positive side of Neutral" 2 "Error Indicator" 3 "Not Available" ;
VAL_ 2365402622 Jystck5GripYAxisNeutralPosStatus 0 "Not in Neutral Position" 1 "In Neutral Position" 2 "Error Indicator" 3 "Not Available" ;
VAL_ 2365402622 Jystck5GrpYAxsLvrBckNgtvPsStatus 0 "Not on negative side of Neutral" 1 "On negative side of Neutral" 2 "Error Indicator" 3 "Not Available" ;
VAL_ 2365402622 Jystck5GrpYAxsLvrFrwrdPstvPsStts 0 "Not on Positive side of Neutral" 1 "On positive side of Neutral" 2 "Error Indicator" 3 "Not Available" ;
VAL_ 2365402622 Jystck5ThetaAxisNeutralPosStatus 0 "Not in Neutral Position" 1 "In Neutral Position" 2 "Error Indicator" 3 "Not Available" ;
VAL_ 2365402622 Jystck5ThtAxsCntrClckwsNgtvPsStt 0 "Not on negative side of Neutral" 1 "On negative side of Neutral" 2 "Error Indicator" 3 "Not Available" ;
VAL_ 2365402622 Jystck5ThtAxsClckwsPstvPosStatus 0 "Not on Positive side of Neutral" 1 "On positive side of Neutral" 2 "Error Indicator" 3 "Not Available" ;
VAL_ 2365402622 Jystick5ThetaAxisDetentPosStatus 0 "Not in the Detent Position" 1 "In the Detent Position" 2 "Error Indicator" 3 "Not Available" ;
VAL_ 2365402622 Jystick5GripYAxisDetentPosStatus 0 "Not in the Detent Position" 1 "In the Detent Position" 2 "Error Indicator" 3 "Not Available" ;
VAL_ 2365402622 Jystick5GripXAxisDetentPosStatus 0 "Not in the Detent Position" 1 "In the Detent Position" 2 "Error Indicator" 3 "Not Available" ;
VAL_ 2365403134 Jystck4GripXAxisNeutralPosStatus 0 "Not in Neutral Position" 1 "In Neutral Position" 2 "Error Indicator" 3 "Not Available" ;
VAL_ 2365403134 Jystck4GrpXAxsLvrLftNgtvPsStatus 0 "Not on negative side of Neutral" 1 "On negative side of Neutral" 2 "Error Indicator" 3 "Not Available" ;
VAL_ 2365403134 Jystck4GrpXAxsLvrRghtPstvPsSttus 0 "Not on Positive side of Neutral" 1 "On positive side of Neutral" 2 "Error Indicator" 3 "Not Available" ;
VAL_ 2365403134 Jystck4GripYAxisNeutralPosStatus 0 "Not in Neutral Position" 1 "In Neutral Position" 2 "Error Indicator" 3 "Not Available" ;
VAL_ 2365403134 Jystck4GrpYAxsLvrBckNgtvPsStatus 0 "Not on negative side of Neutral" 1 "On negative side of Neutral" 2 "Error Indicator" 3 "Not Available" ;
VAL_ 2365403134 Jystck4GrpYAxsLvrFrwrdPstvPsStts 0 "Not on Positive side of Neutral" 1 "On positive side of Neutral" 2 "Error Indicator" 3 "Not Available" ;
VAL_ 2365403134 Jystck4ThetaAxisNeutralPosStatus 0 "Not in Neutral Position" 1 "In Neutral Position" 2 "Error Indicator" 3 "Not Available" ;
VAL_ 2365403134 Jystck4ThtAxsCntrClckwsNgtvPsStt 0 "Not on negative side of Neutral" 1 "On negative side of Neutral" 2 "Error Indicator" 3 "Not Available" ;
VAL_ 2365403134 Jystck4ThtAxsClckwsPstvPosStatus 0 "Not on Positive side of Neutral" 1 "On positive side of Neutral" 2 "Error Indicator" 3 "Not Available" ;
VAL_ 2365403134 Jystick4ThetaAxisDetentPosStatus 0 "Not in the Detent Position" 1 "In the Detent Position" 2 "Error Indicator" 3 "Not Available" ;
VAL_ 2365403134 Jystick4GripYAxisDetentPosStatus 0 "Not in the Detent Position" 1 "In the Detent Position" 2 "Error Indicator" 3 "Not Available" ;
VAL_ 2365403134 Jystick4GripXAxisDetentPosStatus 0 "Not in the Detent Position" 1 "In the Detent Position" 2 "Error Indicator" 3 "Not Available" ;
VAL_ 2365400062 Jystck10GrpXAxisNeutralPosStatus 0 "Not in Neutral Position" 1 "In Neutral Position" 2 "Error Indicator" 3 "Not Available" ;
VAL_ 2365400062 Jystck10GrpXAxsLvrLftNgtvPsSttus 0 "Not on negative side of Neutral" 1 "On negative side of Neutral" 2 "Error Indicator" 3 "Not Available" ;
VAL_ 2365400062 Jystck10GrpXAxsLvrRghtPstvPsStts 0 "Not on Positive side of Neutral" 1 "On positive side of Neutral" 2 "Error Indicator" 3 "Not Available" ;
VAL_ 2365400062 Jystck10GrpYAxisNeutralPosStatus 0 "Not in Neutral Position" 1 "In Neutral Position" 2 "Error Indicator" 3 "Not Available" ;
VAL_ 2365400062 Jystck10GrpYAxsLvrBckNgtvPsSttus 0 "Not on negative side of Neutral" 1 "On negative side of Neutral" 2 "Error Indicator" 3 "Not Available" ;
VAL_ 2365400062 Jystck10GrpYAxsLvrFrwrdPstvPsStt 0 "Not on Positive side of Neutral" 1 "On positive side of Neutral" 2 "Error Indicator" 3 "Not Available" ;
VAL_ 2365400062 Jystck10ThtaAxisNeutralPosStatus 0 "Not in Neutral Position" 1 "In Neutral Position" 2 "Error Indicator" 3 "Not Available" ;
VAL_ 2365400062 Jystck10ThtAxsCntrClckwsNgtvPsSt 0 "Not on negative side of Neutral" 1 "On negative side of Neutral" 2 "Error Indicator" 3 "Not Available" ;
VAL_ 2365400062 Jystck10ThtAxsClckwsPstvPsStatus 0 "Not on Positive side of Neutral" 1 "On positive side of Neutral" 2 "Error Indicator" 3 "Not Available" ;
VAL_ 2365400062 Jystck10ThetaAxisDetentPosStatus 0 "Not in the Detent Position" 1 "In the Detent Position" 2 "Error Indicator" 3 "Not Available" ;
VAL_ 2365400062 Jystck10GripYAxisDetentPosStatus 0 "Not in the Detent Position" 1 "In the Detent Position" 2 "Error Indicator" 3 "Not Available" ;
VAL_ 2365400062 Jystck10GripXAxisDetentPosStatus 0 "Not in the Detent Position" 1 "In the Detent Position" 2 "Error Indicator" 3 "Not Available" ;
VAL_ 2566749184 DieselParticulateFilterLampCmd 2 "reserved for SAE assignment" 3 "reserved for SAE assignment" 5 "reserved for SAE assignment" 0 "Off" 1 "On  solid" 6 "reserved for SAE assignment" 4 "On  fast blink 1 HZ" 7 "not available" ;
VAL_ 2566749184 DslPrtcltFltrPssvRgnrationStatus 0 "not active" 1 "active" 2 "reserved for SAE assignment" 3 "not available" ;
VAL_ 2566749184 DslPrtcltFltrActvRgnrationStatus 0 "not active" 1 "active" 2 "regeneration needed  automatically initiated active regeneration imminent" 3 "not available" ;
VAL_ 2566749184 DieselParticulateFilterStatus 4 "reserved for SAE assignment" 5 "reserved for SAE assignment" 0 "Regeneration not needed" 1 "Regeneration needed  lowest level" 2 "Regeneration needed  moderate level" 3 "Regeneration needed  highest level" 6 "reserved for SAE assignment" 7 "not available" ;
VAL_ 2566749184 DslPrtcltFltrActvRgnrtnInhbtdStt 0 "not inhibited" 1 "inhibited" 2 "reserved for SAE assignment" 3 "not available" ;
VAL_ 2566749184 DslPrtcltFltrActvRgnrtnInhbtdDTI 0 "not inhibited" 1 "inhibited" 2 "reserved for SAE assignment" 3 "not available" ;
VAL_ 2566749184 DslPrtcltFltrActvRgnrtnInhbtdDTC 0 "not inhibited" 1 "inhibited" 2 "reserved for SAE assignment" 3 "not available" ;
VAL_ 2566749184 DslPrtcltFltrActvRgnrtnInhbtdDTS 0 "not inhibited" 1 "inhibited" 2 "reserved for SAE assignment" 3 "not available" ;
VAL_ 2566749184 DslPrtcltFltrActvRgnrtnInhbtdDTP 0 "not inhibited" 1 "inhibited" 2 "reserved for SAE assignment" 3 "not available" ;
VAL_ 2566749184 DslPrtcltFltrActvRgnrtnInhbtdDTA 0 "not inhibited" 1 "inhibited" 2 "reserved for SAE assignment" 3 "not available" ;
VAL_ 2566749184 DslPrtcltFltrActvRgnrtnInhbtdDTO 0 "notInhibited" 1 "inhibited" 2 "reservedForSAEAssignment" 3 "notAvailable" ;
VAL_ 2566749184 DslPrtcltFltrActvRgnrtnInhb_0002 0 "notInhibited" 1 "inhibited" 2 "reservedForSAEAssignment" 3 "notAvailable" ;
VAL_ 2566749184 DslPrtcltFltrActvRgnrtnInhb_0001 0 "notInhibited" 1 "inhibited" 2 "reservedForSAEAssignment" 3 "notAvailable" ;
VAL_ 2566749184 DslPrtcltFltrActvRgnrtnInhbtdDTL 0 "not inhibited" 1 "inhibited" 2 "reserved for SAE assignment" 3 "not available" ;
VAL_ 2566749184 DslPrtcltFltrActvRgnrtnInhbtdDTT 0 "not inhibited" 1 "inhibited" 2 "reserved for SAE assignment" 3 "not available" ;
VAL_ 2566749184 DslPrtcltFltrActvRgnrtnInhb_0000 0 "notInhibited" 1 "inhibited" 2 "reservedForSAEAssignment" 3 "notAvailable" ;
VAL_ 2566749184 DslPrtcltFltrActvRgnrtnInhbtdDTE 0 "notInhibited" 1 "inhibited" 2 "reservedForSAEAssignment" 3 "notAvailable" ;
VAL_ 2566749184 DslPrtcltFltrActvRgnrtnInhbtdDTV 0 "notInhibited" 1 "inhibited" 2 "reservedForSAEAssignment" 3 "notAvailable" ;
VAL_ 2566749184 DslPrtcltFltrAtmtcActvRgnrtnIntt 0 "not enabled" 1 "enabled" 2 "reserved for SAE assignment" 3 "not available" ;
VAL_ 2566749184 ExhaustSystemHighTempLampCmd 2 "reserved for SAE assignment" 3 "reserved for SAE assignment" 4 "reserved for SAE assignment" 5 "reserved for SAE assignment" 0 "Off" 1 "On  solid" 6 "reserved for SAE assignment" 7 "not available" ;
VAL_ 2566749184 DslPrtcltFltrActvRgnrtnFrcdSttus 0 "Not Active" 1 "Active  Forced by Switch See SPN 3696" 3 "Reserved for SAE Assignment" 2 "Active  Forced by Service Tool" 6 "Reserved for SAE Assignment" 7 "not available" 4 "Reserved for SAE Assignment" 5 "Reserved for SAE Assignment" ;
VAL_ 2566718718 VehicleBatteryVoltageLowLampData 0 "Lamp deactivated Off" 1 "Lamp activated On" 2 "Error" 3 "Not available" ;
VAL_ 2566718718 VehicleFuelLevelLowLampData 0 "Lamp deactivated Off" 1 "Lamp activated On" 2 "Error" 3 "Not available" ;
VAL_ 2566718718 VehicleAirPressLowLampData 0 "Lamp deactivated Off" 1 "Lamp activated On" 2 "Error" 3 "Not available" ;
VAL_ 2566718718 VehicleHVACRecirculationLampData 0 "Lamp deactivated Off" 1 "Lamp activated On" 2 "Error" 3 "Not available" ;
VAL_ 2566718718 VehicleBatteryChargingLampData 0 "Lamp deactivated Off" 1 "Lamp activated On" 2 "Error" 3 "Not available" ;
VAL_ 2566718974 EngProtectLampData 0 "Lamp deactivated Off" 1 "Lamp activated On" 2 "Error" 3 "Not available" ;
VAL_ 2566718974 EngAmberWarningLampData 0 "Lamp deactivated Off" 1 "Lamp activated On" 2 "Error" 3 "Not available" ;
VAL_ 2566718974 EngRedStopLampData 0 "Lamp deactivated Off" 1 "Lamp activated On" 2 "Error" 3 "Not available" ;
VAL_ 2566718974 OBDMalfunctionIndicatorLampData 0 "Lamp deactivated Off" 1 "Lamp activated On" 2 "Error" 3 "Not available" ;
VAL_ 2566718974 EngBrakeActiveLampData 0 "Lamp deactivated Off" 1 "Lamp activated On" 2 "Error" 3 "Not available" ;
VAL_ 2566718974 CmprssnBrkEnblSwtchIndctrLmpData 0 "Lamp deactivated Off" 1 "Lamp activated On" 2 "Error" 3 "Not available" ;
VAL_ 2566718974 EngOilPressLowLampData 0 "Lamp deactivated Off" 1 "Lamp activated On" 2 "Error" 3 "Not available" ;
VAL_ 2566718974 EngCoolantTempHighLampData 0 "Lamp deactivated Off" 1 "Lamp activated On" 2 "Error" 3 "Not available" ;
VAL_ 2566718974 EngCoolantLevelLowLampData 0 "Lamp deactivated Off" 1 "Lamp activated On" 2 "Error" 3 "Not available" ;
VAL_ 2566718974 EngIdleManagementActiveLampData 0 "Lamp deactivated Off" 1 "Lamp activated On" 2 "Error" 3 "Not available" ;
VAL_ 2566718974 EngAirFilterRestrictionLampData 0 "Lamp deactivated Off" 1 "Lamp activated On" 2 "Error" 3 "Not available" ;
VAL_ 2566718974 EngFuelFilterRestrictedLampData 0 "Lamp deactivated Off" 1 "Lamp activated On" 2 "Error" 3 "Not available" ;
VAL_ 2566718974 EngWaitToStartLampData 0 "Lamp deactive" 1 "Lamp active" 2 "Error" 3 "Not available" ;
VAL_ 2566719230 VehicleBatteryVoltageLowLampCmd 0 "Lamp Off" 1 "Lamp On" 2 "Reserved" 3 "Not available" ;
VAL_ 2566719230 VehicleFuelLevelLowLampCmd 0 "Lamp Off" 1 "Lamp On" 2 "Reserved" 3 "Not available" ;
VAL_ 2566719230 VehicleAirPressLowLampCmd 0 "Lamp Off" 1 "Lamp On" 2 "Reserved" 3 "Not available" ;
VAL_ 2566719230 VehicleHVACRecirculationLampCmd 0 "Lamp Off" 1 "Lamp On" 2 "Reserved" 3 "Not available" ;
VAL_ 2566719230 VehicleBatteryChargingLampCmd 0 "Lamp Off" 1 "Lamp On" 2 "Reserved" 3 "Not available" ;
VAL_ 2560818942 FailureModeIdentifier1 0 "Above normal (most severe)" 1 "Below normal (most severe)" 2 "Data erratic" 3 "Voltage above normal" 4 "Voltage below normal" 5 "Current below normal" 6 "Current above normal" 7 "Mechanical system not responding" 8 "Abnormal frequency" 9 "Abnormal update rate" 10 "Abnormal rate of change" 11 "Root cause not known" 12 "Bad intelligent device" 13 "Out of calibration" 14 "Special intstructions" 15 "Above normal (least severe)" 16 "Above normal (moderately severe)" 17 "Below normal (least severe)" 18 "Below normal (moderately severe)" 19 "Received network data in error" 31 "Not available" ;
VAL_ 2561212158 TextDisplayInstructions 2 "Append at end of display  The transmitted information should be displayed at the end of the presently displayed" 3 "Overwrite display  The presently displayed information is to be overwritten with the transmitted information" 4 "Overwrite substring  A portion of the presently displayed information is to be overwritten with the transmitted" 5 "Highlight substring" 0 "Clear display  The displayed information should be deleted or not displayed any more" 1 "Hold display  The presently displayed information should be retained" 15 "Not applicable" 6 "Blink substring" ;
VAL_ 2566746366 RetractStatusOfRamp1 0 "ramp retracted" 1 "ramp extended" 2 "error" 3 "not available" ;
VAL_ 2566746366 EnableStatusOfRamp1 0 "ramp disabled" 1 "ramp enabled" 2 "error" 3 "not available" ;
VAL_ 2566746366 MovementStatusOfRamp1 0 "ramp not being moved" 1 "ramp being moved" 2 "error" 3 "not available" ;
VAL_ 2566746366 RetractStatusOfRamp2 0 "ramp retracted" 1 "ramp extended" 2 "error" 3 "not available" ;
VAL_ 2566746366 EnableStatusOfRamp2 0 "ramp disabled" 1 "ramp enabled" 2 "error" 3 "not available" ;
VAL_ 2566746366 MovementStatusOfRamp2 0 "ramp not being moved" 1 "ramp being moved" 2 "error" 3 "not available" ;
VAL_ 2566746366 RetractStatusOfRamp3 0 "ramp retracted" 1 "ramp extended" 2 "error" 3 "not available" ;
VAL_ 2566746366 EnableStatusOfRamp3 0 "ramp disabled" 1 "ramp enabled" 2 "error" 3 "not available" ;
VAL_ 2566746366 MovementStatusOfRamp3 0 "ramp not being moved" 1 "ramp being moved" 2 "error" 3 "not available" ;
VAL_ 2566746366 EnableStatusOfRamp4 0 "ramp disabled" 1 "ramp enabled" 2 "error" 3 "not available" ;
VAL_ 2566746366 EnableStatusOfRamp5 0 "ramp disabled" 1 "ramp enabled" 2 "error" 3 "not available" ;
VAL_ 2566746366 MovementStatusOfRamp4 0 "ramp not being moved" 1 "ramp being moved" 2 "error" 3 "not available" ;
VAL_ 2566746366 MovementStatusOfRamp5 0 "ramp not being moved" 1 "ramp being moved" 2 "error" 3 "not available" ;
VAL_ 2566746366 RetractStatusOfRamp4 0 "ramp retracted" 1 "ramp extended" 2 "error" 3 "not available" ;
VAL_ 2566746366 RetractStatusOfRamp5 3 "not available" 0 "ramp retracted" 1 "ramp extended" 2 "error" ;
VAL_ 2561277694 LaneDepartureWarningEnableCmd 0 "Disable Lane Departure Warning" 1 "Enable Lane Departure Warning" 2 "Reserved" 3 "Dont care" ;
VAL_ 2565873150 SteerWheelAngleRangeCounterType 0 "relative number of counts" 1 "absolute number of counts" 2 "not defined" 3 "signal not available" ;
VAL_ 2565873150 SteerAngleSensorActiveMode 0 "Programming mode active" 1 "Normal mode active" 2 "Reserved" 3 "Not available" ;
VAL_ 2565873150 SteerAngleSensorCalibrated 0 "SAS not calibrated" 1 "SAS calibrated" 2 "Reserved" 3 "Not available" ;
VAL_ 2566751230 TransferCaseStatus 1 "4 wheel high normal or On Highway Range" 2 "neutral" 4 "4 wheel low or Off Highway Range" 5 "Transfer Case Shift in Progress or gear not confirmed" 6 "error" 0 "2 wheel high normal or On Highway Range" 3 "2 wheel low or Off Highway Range" 7 "not available" ;
VAL_ 2566755587 TransOilFilterRestrictionSwitch 0 "No restriction" 1 "Restriction exists on oil filter" 2 "Error" 3 "Not available" ;
VAL_ 2566755587 TransOilLevelSwitch 0 "Empty" 1 "Full or not empty" 2 "Error" 3 "Not available" ;
VAL_ 2566755587 TransOverheatIndicator 0 "Transmission Overheat Indicator is off" 1 "Transmission Overheat Indicator is on continuously" 2 "Transmission Overheat Indicator is flashing" 3 "Not available" ;
VAL_ 2566799614 RunningLight 0 "Deactivated" 1 "Activated" 2 "Fault Detected" 3 "Not Available" ;
VAL_ 2566799614 AltBeamHeadLightData 0 "Deactivated" 1 "Activated" 2 "Fault Detected" 3 "Not Available" ;
VAL_ 2566799614 LowBeamHeadLightData 0 "Deactivated" 1 "Activated" 2 "Fault Detected" 3 "Not Available" ;
VAL_ 2566799614 HighBeamHeadLightData 0 "Deactivated" 1 "Activated" 2 "Fault Detected" 3 "Not Available" ;
VAL_ 2566799614 TractorFrontFogLights 0 "Deactivated" 1 "Activated" 2 "Fault Detected" 3 "Not Available" ;
VAL_ 2566799614 RotatingBeaconLight 0 "Deactivated" 1 "Activated" 2 "Fault Detected" 3 "Not Available" ;
VAL_ 2566799614 RightTurnSignalLights 0 "Deactivated" 1 "Activated" 2 "Fault Detected" 3 "Not Available" ;
VAL_ 2566799614 LeftTurnSignalLights 0 "Deactivated" 1 "Activated" 2 "Fault Detected" 3 "Not Available" ;
VAL_ 2566799614 BackUpLightAndAlarmHorn 0 "Deactivated" 1 "Activated" 2 "Fault Detected" 3 "Not Available" ;
VAL_ 2566799614 CenterStopLight 0 "Deactivated" 1 "Activated" 2 "Fault Detected" 3 "Not Available" ;
VAL_ 2566799614 RightStopLight 0 "Deactivated" 1 "Activated" 2 "Fault Detected" 3 "Not Available" ;
VAL_ 2566799614 LeftStopLight 0 "Deactivated" 1 "Activated" 2 "Fault Detected" 3 "Not Available" ;
VAL_ 2566799614 ImplementClearanceLight 0 "Deactivated" 1 "Activated" 2 "Fault Detected" 3 "Not Available" ;
VAL_ 2566799614 TractorClearanceLight 0 "Deactivated" 1 "Activated" 2 "Fault Detected" 3 "Not Available" ;
VAL_ 2566799614 ImplementMarkerLight 0 "Deactivated" 1 "Activated" 2 "Fault Detected" 3 "Not Available" ;
VAL_ 2566799614 TractorMarkerLight 0 "Deactivated" 1 "Activated" 2 "Fault Detected" 3 "Not Available" ;
VAL_ 2566799614 RearFogLights 0 "Deactivated" 1 "Activated" 2 "Fault Detected" 3 "Not Available" ;
VAL_ 2566799614 TrctorUndersideMountedWorkLights 0 "Deactivated" 1 "Activated" 2 "Fault Detected" 3 "Not Available" ;
VAL_ 2566799614 TractorRearLowMountedWorkLights 0 "Deactivated" 1 "Activated" 2 "Fault Detected" 3 "Not Available" ;
VAL_ 2566799614 TractorRearHighMountedWorkLights 0 "Deactivated" 1 "Activated" 2 "Fault Detected" 3 "Not Available" ;
VAL_ 2566799614 TractorSideLowMountedWorkLights 0 "Deactivated" 1 "Activated" 2 "Fault Detected" 3 "Not Available" ;
VAL_ 2566799614 TractorSideHighMountedWorkLights 0 "Deactivated" 1 "Activated" 2 "Fault Detected" 3 "Not Available" ;
VAL_ 2566799614 TractorFrontLowMountedWorkLights 0 "Deactivated" 1 "Activated" 2 "Fault Detected" 3 "Not Available" ;
VAL_ 2566799614 TrctorFrontHighMountedWorkLights 0 "Deactivated" 1 "Activated" 2 "Fault Detected" 3 "Not Available" ;
VAL_ 2566799614 ImplementOEMOption2Light 0 "Deactivated" 1 "Activated" 2 "Fault Detected" 3 "Not Available" ;
VAL_ 2566799614 ImplementOEMOption1Light 0 "Deactivated" 1 "Activated" 2 "Fault Detected" 3 "Not Available" ;
VAL_ 2566799614 ImplementRightFacingWorkLight 0 "Deactivated" 1 "Activated" 2 "Fault Detected" 3 "Not Available" ;
VAL_ 2566799614 ImplementLeftFacingWorkLight 0 "Deactivate" 1 "Activate" 2 "Fault Detected" 3 "Not Available" ;
VAL_ 2566799614 ImplementRightForwardWorkLight 0 "Deactivated" 1 "Activated" 2 "Fault Detected" 3 "Not Available" ;
VAL_ 2566799614 ImplementLeftForwardWorkLight 0 "Deactivated" 1 "Activated" 2 "Fault Detected" 3 "Not Available" ;
VAL_ 2566799614 ImplementRearWorkLight 0 "Deactivated" 1 "Activated" 2 "Fault Detected" 3 "Not Available" ;
VAL_ 2365473073 RunningLightCmd 0 "Deactivate" 1 "Activate" 2 "Reserved" 3 "Dont Care" ;
VAL_ 2365473073 AltBeamHeadLightCmd 0 "Deactivate" 1 "Activate" 2 "Reserved" 3 "Dont Care" ;
VAL_ 2365473073 LowBeamHeadLightCmd 0 "Deactivate" 1 "Activate" 2 "Reserved" 3 "Dont Care" ;
VAL_ 2365473073 HighBeamHeadLightCmd 0 "Deactivate" 1 "Activate" 2 "Reserved" 3 "Dont Care" ;
VAL_ 2365473073 TractorFrontFogLightsCmd 0 "Deactivate" 1 "Activate" 2 "Reserved" 3 "Dont Care" ;
VAL_ 2365473073 RotatingBeaconLightCmd 0 "Deactivate" 1 "Activate" 2 "Reserved" 3 "Dont Care" ;
VAL_ 2365473073 RightTurnSignalLightsCmd 0 "Deactivate" 1 "Activate" 2 "Reserved" 3 "Dont Care" ;
VAL_ 2365473073 LeftTurnSignalLightsCmd 0 "Deactivate" 1 "Activate" 2 "Reserved" 3 "Dont Care" ;
VAL_ 2365473073 BackUpLightAndAlarmHornCmd 0 "Deactivate" 1 "Activate" 2 "Reserved" 3 "Dont Care" ;
VAL_ 2365473073 CenterStopLightCmd 0 "Deactivate" 1 "Activate" 2 "Reserved" 3 "Dont Care" ;
VAL_ 2365473073 RightStopLightCmd 0 "Deactivate" 1 "Activate" 2 "Reserved" 3 "Dont Care" ;
VAL_ 2365473073 LeftStopLightCmd 0 "Deactivate" 1 "Activate" 2 "Reserved" 3 "Dont Care" ;
VAL_ 2365473073 ImplementClearanceLightCmd 0 "Deactivate" 1 "Activate" 2 "Reserved" 3 "Dont Care" ;
VAL_ 2365473073 TractorClearanceLightCmd 0 "Deactivate" 1 "Activate" 2 "Reserved" 3 "Dont Care" ;
VAL_ 2365473073 ImplementMarkerLightCmd 0 "Deactivate" 1 "Activate" 2 "Reserved" 3 "Dont Care" ;
VAL_ 2365473073 TractorMarkerLightCmd 0 "Deactivate" 1 "Activate" 2 "Reserved" 3 "Dont Care" ;
VAL_ 2365473073 RearFogLightCmd 0 "Deactivate" 1 "Activate" 2 "Reserved" 3 "Dont Care" ;
VAL_ 2365473073 TrctrUndrsdeMountedWorkLightsCmd 0 "Deactivate" 1 "Activate" 2 "Reserved" 3 "Dont Care" ;
VAL_ 2365473073 TrctrRearLowMountedWorkLightsCmd 0 "Deactivate" 1 "Activate" 2 "Reserved" 3 "Dont Care" ;
VAL_ 2365473073 TrctrRarHighMountedWorkLightsCmd 0 "Deactivate" 1 "Activate" 2 "Reserved" 3 "Dont Care" ;
VAL_ 2365473073 TrctrSideLowMountedWorkLightsCmd 0 "Deactivate" 1 "Activate" 2 "Reserved" 3 "Dont Care" ;
VAL_ 2365473073 TrctrSdeHighMountedWorkLightsCmd 0 "Deactivate" 1 "Activate" 2 "Reserved" 3 "Dont Care" ;
VAL_ 2365473073 TrctrFrntLowMountedWorkLightsCmd 0 "Deactivate" 1 "Activate" 2 "Reserved" 3 "Dont Care" ;
VAL_ 2365473073 TrctrFrntHghMountedWorkLightsCmd 0 "Deactivate" 1 "Activate" 2 "Reserved" 3 "Dont Care" ;
VAL_ 2365473073 ImplementOEMOption2LightCmd 0 "Deactivate" 1 "Activate" 2 "Reserved" 3 "Dont Care" ;
VAL_ 2365473073 ImplementOEMOption1LightCmd 0 "Deactivate" 1 "Activate" 2 "Reserved" 3 "Dont Care" ;
VAL_ 2365473073 ImplementRightFacingWorkLightCmd 0 "Deactivate" 1 "Activate" 2 "Reserved" 3 "Dont Care" ;
VAL_ 2365473073 ImplementLeftFacingWorkLightCmd 0 "Deactivate" 1 "Activate" 2 "Reserved" 3 "Dont Care" ;
VAL_ 2365473073 LightingDataRqCmd 0 "Deactivate" 1 "Activate" 2 "Reserved" 3 "Dont Care" ;
VAL_ 2365473073 ImplmentRightForwardWorkLightCmd 0 "Deactivate" 1 "Activate" 2 "Reserved" 3 "Dont Care" ;
VAL_ 2365473073 ImplementLeftForwardWorkLightCmd 0 "Deactivate" 1 "Activate" 2 "Reserved" 3 "Dont Care" ;
VAL_ 2365473073 ImplementRearWorkLightCmd 0 "Deactivate" 1 "Activate" 2 "Reserved" 3 "Dont Care" ;
VAL_ 2365485822 BladeCtrlMode 0 "Manual mode" 1 "Automatic mode" 2 "Inactive automatic mode" ;
VAL_ 2365485822 BladeCtrlModeLeft 0 "Manual" 1 "Auto" 2 "Inactive Auto" 14 "Error" 15 "Not Available" ;
VAL_ 2365485822 BladeCtrlModeRight 0 "Manual" 1 "Auto" 2 "Inactive Auto" 14 "Error" 15 "Not Available" ;
VAL_ 2365485822 LandLevelingSystemEnableStatus 0 "Disabled" 2 "Error" 3 "Not available / Not installed" ;
VAL_ 2566768894 EngOprtrPrmryIntrmdtSpdSlctState 0 "Control state is ISC functionality is not requested engine operates normally" 1 "thru 1101  Control state is ISC Setting 1 thru 13 in sequential order" 14 "SAE reserved" 15 "not available" ;
VAL_ 2566769201 EngOprtrPrmryIntrmdteSpeedSelect 0 "indicates that the ISC functionality is not requested engine operates normally" 1 "thru 1101  indicates that the ISC Setting 1 thru 13 in sequential order is selected" 14 "error condition" 15 "not available" ;
VAL_ 2566811134 AuxHeaterMode 0 "Heater not active" 1 "Off due to ADR per European Regulations for Transport of hazardous materials" 2 "Economy mode" 3 "Normal mode" 14 "Error" 15 "Not available" ;
VAL_ 2566811134 AuxHeaterWaterPumpStatus 0 "Water Pump is not running" 1 "Water Pump is running" 2 "Reserved" 3 "Not available" ;
VAL_ 2566811134 CabVentilation 0 "Cab not ventilated" 1 "Cab is ventilated" 2 "Reserved" 3 "Not available" ;
VAL_ 2566811134 EngHeatingZone 0 "Engine heating zone off" 1 "Engine heating zone on" 2 "Reserved" 3 "Not available" ;
VAL_ 2566811134 CabHeatingZone 0 "Cab heating zone off" 1 "Cab heating zone on" 2 "Reserved" 3 "Not available" ;
VAL_ 2565867774 EngHydPressGovernorModeIndicator 0 "Disabled" 1 "Enabled" 2 "Error Indicator" 3 "Not Available" ;
VAL_ 2565867774 EngHydPressGovernorSwitch 0 "Pressure Mode Inactive" 1 "Pressure Mode Active" 2 "Error Indicator" 3 "Not Available" ;
VAL_ 2565867774 FireApparatusPumpEngagement 0 "Pump not engaged" 1 "Pump engaged" 2 "Error" 3 "Not available or not installed" ;
VAL_ 2365449982 HydBrkePressWarningStateCircuit1 0 "Pressure level sufficient" 1 "Pressure level below warning level" 2 "Error indicator" 3 "Not available" ;
VAL_ 2365449982 HydBrkePressWarningStateCircuit2 0 "Pressure level sufficient" 1 "Pressure level below warning level" 2 "Error indicator" 3 "Not available" ;
VAL_ 2365449982 HydBrakePressSupplyStateCircuit1 0 "Supply is not reliable" 1 "Supply is reliable" 2 "Error indicator" 3 "Not available" ;
VAL_ 2365449982 HydBrakePressSupplyStateCircuit2 0 "Supply is not reliable" 1 "Supply is reliable" 2 "Error indicator" 3 "Not available" ;
VAL_ 2365449982 HydBrakeSystemAudibleWarningCmd 0 "Audible warning off" 1 "Audible warning on" 2 "Reserved" 3 "Dont care" ;
VAL_ 2365449982 HydBrakeFluidLevelSwitch 0 "Fluid level is not sufficient" 1 "Fluid level is sufficient" 2 "Error indicator" 3 "Not available" ;
VAL_ 2566759678 EnblSwtchTrnsfrCseOutputShaftPTO 0 "Enable switch off  PTO operation not desired" 1 "Enable switch off  PTO operation desired" 2 "Error" 3 "Not available" ;
VAL_ 2566759678 EnableSwitchTransOutputShaftPTO 0 "Enable switch off  PTO operation not desired" 1 "Enable switch off  PTO operation desired" 2 "Error" 3 "Not available" ;
VAL_ 2566759678 EnableSwitchTransInputShaftPTO2 0 "Enable switch off  PTO operation not desired" 1 "Enable switch off  PTO operation desired" 2 "Error" 3 "Not available" ;
VAL_ 2566759678 EnableSwitchTransInputShaftPTO1 0 "Enable switch off  PTO operation not desired" 1 "Enable switch off  PTO operation desired" 2 "Error" 3 "Not available" ;
VAL_ 2566759678 EnableSwitchPTOEngFlywheel 0 "Enable switch off  PTO operation not desired" 1 "Enable switch on  PTO operation desired" 2 "Error" 3 "Not available" ;
VAL_ 2566759678 EnbleSwitchPTOEngAccessoryDrive1 0 "Enable switch off  PTO operation not desired" 1 "Enable switch on  PTO operation desired" 2 "Error" 3 "Not available" ;
VAL_ 2566759678 EnbleSwitchPTOEngAccessoryDrive2 0 "Enable switch off  PTO operation not desired" 1 "Enable switch on  PTO operation desired" 2 "Error" 3 "Not available" ;
VAL_ 2566759678 EnggmntCnsntTrnsfrCsOtptShaftPTO 0 "Consent not given  PTO drive should not be engaged" 1 "Consent given  PTO drive may be engaged" 2 "Error" 3 "Not available" ;
VAL_ 2566759678 EnggmntCnsentTransOutputShaftPTO 0 "Consent not given  PTO drive should not be engaged" 1 "Consent given  PTO drive may be engaged" 2 "Error" 3 "Not available" ;
VAL_ 2566759678 EnggmntCnsentTransInputShaftPTO2 0 "Consent not given  PTO drive should not be engaged" 1 "Consent given  PTO drive may be engaged" 2 "Error" 3 "Not available" ;
VAL_ 2566759678 EnggmntCnsentTransInputShaftPTO1 0 "Consent not given  PTO drive should not be engaged" 1 "Consent given  PTO drive may be engaged" 2 "Error" 3 "Not available" ;
VAL_ 2566759678 EngagementConsentPTOEngFlywheel 0 "Consent not given  PTO drive may not be engaged" 1 "Consent given  PTO drive may be engaged" 2 "Error" 3 "Not available" ;
VAL_ 2566759678 EnggmntCnsntPTOEngAccssoryDrive1 0 "Consent not given  PTO drive may not be engaged" 1 "Consent given  PTO drive may be engaged" 2 "Error" 3 "Not available" ;
VAL_ 2566759678 EnggmntCnsntPTOEngAccssoryDrive2 0 "Consent not given  PTO drive may not be engaged" 1 "Consent given  PTO drive may be engaged" 2 "Error" 3 "Not available" ;
VAL_ 2566759678 EnggmntSttsTrnsfrCsOtputShaftPTO 0 "Drive not engaged" 1 "Drive is engaged" 2 "Error" 3 "Not available" ;
VAL_ 2566759678 EnggmntStatusTransOutputShaftPTO 0 "Drive not engaged" 1 "Drive is engaged" 2 "Error" 3 "Not available" ;
VAL_ 2566759678 EnggmntStatusTransInputShaftPTO2 0 "Drive not engaged" 1 "Drive is engaged" 2 "Error" 3 "Not available" ;
VAL_ 2566759678 EnggmntStatusTransInputShaftPTO1 0 "Drive not engaged" 1 "Drive is engaged" 2 "Error" 3 "Not available" ;
VAL_ 2566759678 EngagementStatusPTOEngFlywheel 0 "Drive not engaged" 1 "Drive engaged" 2 "Error" 3 "Not available" ;
VAL_ 2566759678 EnggmntSttsPTOEngAccessoryDrive1 0 "Drive not engaged" 1 "Drive engaged" 2 "Error" 3 "Not available" ;
VAL_ 2566759678 EnggmntSttsPTOEngAccessoryDrive2 0 "Drive not engaged" 1 "Drive engaged" 2 "Error" 3 "Not available" ;
VAL_ 2566759678 AtLeastOnePTOEngaged 0 "No PTO drive is engaged" 1 "At least one PTO drive is engaged" 2 "Error" 3 "Not available" ;
VAL_ 2432541694 EngTrbCmprssrBypssActtr1TmpSttus 0 "High Most severe" 1 "High Least severe" 2 "In Range" 3 "Low Least severe" 4 "Low Most severe" 5 "Not Defined" 6 "Error" 7 "Not available" ;
VAL_ 2566759934 LockStatusOfDoor1 0 "unlocked" 1 "locked" 2 "error" 3 "not available" ;
VAL_ 2566759934 OpenStatusOfDoor1 0 "door closed" 1 "door opened" 2 "error" 3 "not available" ;
VAL_ 2566759934 EnableStatusOfDoor1 0 "door disabled" 1 "door enabled" 2 "error" 3 "not available" ;
VAL_ 2566759934 LockStatusOfDoor2 0 "unlocked" 1 "locked" 2 "error" 3 "not available" ;
VAL_ 2566759934 OpenStatusOfDoor2 0 "door closed" 1 "door opened" 2 "error" 3 "not available" ;
VAL_ 2566759934 EnableStatusOfDoor2 0 "door disabled" 1 "door enabled" 2 "error" 3 "not available" ;
VAL_ 2566759934 LockStatusOfDoor3 0 "unlocked" 1 "locked" 2 "error" 3 "not available" ;
VAL_ 2566759934 OpenStatusOfDoor3 0 "door closed" 1 "door opened" 2 "error" 3 "not available" ;
VAL_ 2566759934 EnableStatusOfDoor3 0 "door disabled" 1 "door enabled" 2 "error" 3 "not available" ;
VAL_ 2566759934 LockStatusOfDoor4 0 "unlocked" 1 "locked" 2 "error" 3 "not available" ;
VAL_ 2566759934 OpenStatusOfDoor4 0 "door closed" 1 "door opened" 2 "error" 3 "not available" ;
VAL_ 2566759934 EnableStatusOfDoor4 0 "door disabled" 1 "door enabled" 2 "error" 3 "not available" ;
VAL_ 2566759934 LockStatusOfDoor5 0 "unlocked" 1 "locked" 2 "error" 3 "not available" ;
VAL_ 2566759934 OpenStatusOfDoor5 0 "door closed" 1 "door opened" 2 "error" 3 "not available" ;
VAL_ 2566759934 EnableStatusOfDoor5 0 "door disabled" 1 "door enabled" 2 "error" 3 "not available" ;
VAL_ 2566759934 LockStatusOfDoor6 0 "unlocked" 1 "locked" 2 "error" 3 "not available" ;
VAL_ 2566759934 OpenStatusOfDoor6 0 "door closed" 1 "door opened" 2 "error" 3 "not available" ;
VAL_ 2566759934 EnableStatusOfDoor6 0 "door disabled" 1 "door enabled" 2 "error" 3 "not available" ;
VAL_ 2566759934 LockStatusOfDoor7 0 "unlocked" 1 "locked" 2 "error" 3 "not available" ;
VAL_ 2566759934 OpenStatusOfDoor7 0 "door closed" 1 "door opened" 2 "error" 3 "not available" ;
VAL_ 2566759934 EnableStatusOfDoor7 0 "door disabled" 1 "door enabled" 2 "error" 3 "not available" ;
VAL_ 2566759934 LockStatusOfDoor8 0 "unlocked" 1 "locked" 2 "error" 3 "not available" ;
VAL_ 2566759934 OpenStatusOfDoor8 0 "door closed" 1 "door opened" 2 "error" 3 "not available" ;
VAL_ 2566759934 EnableStatusOfDoor8 0 "door disabled" 1 "door enabled" 2 "error" 3 "not available" ;
VAL_ 2566759934 LockStatusOfDoor9 0 "unlocked" 1 "locked" 2 "error" 3 "not available" ;
VAL_ 2566759934 OpenStatusOfDoor9 0 "door closed" 1 "door opened" 2 "error" 3 "not available" ;
VAL_ 2566759934 EnableStatusOfDoor9 0 "door disabled" 1 "door enabled" 2 "error" 3 "not available" ;
VAL_ 2566759934 LockStatusOfDoor10 0 "unlocked" 1 "locked" 2 "error" 3 "not available" ;
VAL_ 2566759934 OpenStatusOfDoor10 0 "door closed" 1 "door opened" 2 "error" 3 "not available" ;
VAL_ 2566759934 EnableStatusOfDoor10 0 "door disabled" 1 "door enabled" 2 "error" 3 "not available" ;
VAL_ 2566757374 Aftrtrtmnt1SCRCtalystReagentType 0 "Catalyst reagent is urea concentration too high" 1 "Catalyst reagent is urea concentration too low" 2 "Catalyst reagent is diesel" 3 "Catalyst reagent is proper mixture" 5 "to 1100  Reserved for SAE assignment" 13 "Not able to determine catalyst reagent type type unknown" 14 "Error detected with urea reagent type detection" 15 "Not available" ;
VAL_ 2364544766 EngCyl1CombustionStatus 0 "No combustion" 1 "Combustion exists" 2 "Error" 3 "Not available" ;
VAL_ 2364544766 EngCyl2CombustionStatus 0 "No combustion" 1 "Combustion exists" 2 "Error" 3 "Not available" ;
VAL_ 2364544766 EngCyl3CombustionStatus 0 "No combustion" 1 "Combustion exists" 2 "Error" 3 "Not available" ;
VAL_ 2364544766 EngCyl4CombustionStatus 0 "No combustion" 1 "Combustion exists" 2 "Error" 3 "Not available" ;
VAL_ 2364544766 EngCyl5CombustionStatus 2 "Error" 3 "Not available" 0 "No combustion" 1 "Combustion exists" ;
VAL_ 2364544766 EngCyl6CombustionStatus 0 "No combustion" 1 "Combustion exists" 2 "Error" 3 "Not available" ;
VAL_ 2364544766 EngCyl7CombustionStatus 0 "No combustion" 1 "Combustion exists" 2 "Error" 3 "Not available" ;
VAL_ 2364544766 EngCyl8CombustionStatus 0 "No combustion" 1 "Combustion exists" 2 "Error" 3 "Not available" ;
VAL_ 2364544766 EngCyl9CombustionStatus 0 "No combustion" 1 "Combustion exists" 2 "Error" 3 "Not available" ;
VAL_ 2364544766 EngCyl10CombustionStatus 0 "No combustion" 1 "Combustion exists" 2 "Error" 3 "Not available" ;
VAL_ 2364544766 EngCyl11CombustionStatus 0 "No combustion" 1 "Combustion exists" 2 "Error" 3 "Not available" ;
VAL_ 2364544766 EngCyl12CombustionStatus 0 "No combustion" 1 "Combustion exists" 2 "Error" 3 "Not available" ;
VAL_ 2364544766 EngCyl13CombustionStatus 0 "No combustion" 1 "Combustion exists" 2 "Error" 3 "Not available" ;
VAL_ 2364544766 EngCyl14CombustionStatus 0 "No combustion" 1 "Combustion exists" 2 "Error" 3 "Not available" ;
VAL_ 2364544766 EngCyl15CombustionStatus 0 "No combustion" 1 "Combustion exists" 2 "Error" 3 "Not available" ;
VAL_ 2364544766 EngCyl16CombustionStatus 0 "No combustion" 1 "Combustion exists" 2 "Error" 3 "Not available" ;
VAL_ 2364544766 EngCyl17CombustionStatus 0 "No combustion" 1 "Combustion exists" 2 "Error" 3 "Not available" ;
VAL_ 2364544766 EngCyl18CombustionStatus 0 "No combustion" 1 "Combustion exists" 2 "Error" 3 "Not available" ;
VAL_ 2364544766 EngCyl19CombustionStatus 0 "No combustion" 1 "Combustion exists" 2 "Error" 3 "Not available" ;
VAL_ 2364544766 EngCyl20CombustionStatus 0 "No combustion" 1 "Combustion exists" 2 "Error" 3 "Not available" ;
VAL_ 2364544766 EngCyl21CombustionStatus 0 "No combustion" 1 "Combustion exists" 2 "Error" 3 "Not available" ;
VAL_ 2364544766 EngCyl22CombustionStatus 0 "No combustion" 1 "Combustion exists" 2 "Error" 3 "Not available" ;
VAL_ 2364544766 EngCyl23CombustionStatus 0 "No combustion" 1 "Combustion exists" 2 "Error" 3 "Not available" ;
VAL_ 2364544766 EngCyl24CombustionStatus 0 "No combustion" 1 "Combustion exists" 2 "Error" 3 "Not available" ;
VAL_ 2364544510 RqGenOverallPowerFactorLagging 0 "Leading" 1 "Lagging" 2 "Error" 3 "NotAvailable" ;
VAL_ 2364544254 RelativeBladeHeightFigureOfMerit 0 "Relative Blade Height fully functional Data is within sensor specification" 1 "Relative Blade Height degraded Data is suspect due to environmental conditions" 2 "Relative Blade Height failed" 3 "Relative Blade Height not available" ;
VAL_ 2364544254 BladeRotationAngleFigureOfMerit 0 "Blade Rotation Angle fully functional Data is within sensor specification" 1 "Blade Rotation Angle degraded Data is suspect due to environmental conditions" 2 "Blade Rotation Angle failed Roll sensor failed to operate correctly" 3 "Blade Rotation Angle not available" ;
VAL_ 2349006590 VehicleABSActive 0 "Passiv,0" 1 "Active" ;
VAL_ 2349006590 VehicleRetarderCtrlActive 0 "Passive" 1 "Active" ;
VAL_ 2349006590 ASRBreakControlActive 0 "Passive,0" 1 "Active" ;
VAL_ 2349006590 ASREngineControlActive 0 "ASREngnCntrlPassiveButInstalled" 1 "ASREngineControlActive" 2 "Reserved" 3 "NotAvailable" ;
VAL_ 2349006590 BrakeLightSwitch 0 "Switch off" 1 "Switch on" ;
VAL_ 2349006590 VehicleType 0 "Towing or towed vehicle" 1 "Dolly axle" ;
VAL_ 2566834686 VehicleRetarderCtrlActive 0 "Passive" 1 "Active" ;
VAL_ 2566834686 TwoElCircuitsBrakeDemand 0 "One el. circuit brake available" 1 "Two el. circuit brake available" ;
VAL_ 2566834686 ABSOffroadRequest 0 "ABS off-road switch off" 1 "ABS off-road switch on" ;
VAL_ 2566834686 PneumaticControlLine 0 "Towing veh without pn ctrl line" 1 "Towing veh with pn ctrl line" ;
VAL_ 2550398718 VehicleABSActive 0 "Passiv,0" 1 "Active" ;
VAL_ 2550398718 VehicleRetarderCtrlActive 0 "Passive" 1 "Active" ;
VAL_ 2550398718 VehicleServiceBrakeActive 0 "Passive" 1 "Active" ;
VAL_ 2550398718 AutomTowedVehBreakActive 0 "Passive" 1 "Active" ;
VAL_ 2550398718 VDCActive 0 "Passive,0" 1 "Active" ;
VAL_ 2550398718 SupplyLineBrakingRequest 0 "No supply line braking request" 1 "Supply line braking request" ;
VAL_ 2566833406 VehicleABSActive 0 "Passiv,0" 1 "Active" ;
VAL_ 2566833406 VehicleRetarderCtrlActive 0 "Passive" 1 "Active" ;
VAL_ 2566833406 VehicleServiceBrakeActive 0 "Passive" 1 "Active" ;
VAL_ 2566833406 AutomTowedVehBreakActive 0 "Passive" 1 "Active" ;
VAL_ 2566833406 VehicleElectrSupplySuff 0 "Vehicle el. supply insufficient" 1 "Vehicle el. supply sufficient" ;
VAL_ 2566833406 RedWarningSignalRequest 0 "No towed vehicle failure indicat" 1 "Towed vehicle failure indicated" ;
VAL_ 2566833406 AmberWarningSignalReq 0 "No towed vehicle failure indicat" 1 "Towed vehicle failure indicated" ;
VAL_ 2566833406 ElecSupplyOfNonBrakingSys 0 "Supply switched off" 1 "Supply switched on" ;
VAL_ 2566833406 VehicleType 0 "Towing or towed vehicle" 1 "Dolly axle" ;
VAL_ 2566833406 SpringBrakeInstalled 0 "Vehicle without spring brakes" 1 "Vehicle with spring brakes" ;
VAL_ 2566833406 ElectrLoadPropFunc 0 "Vehicle without el. load proport" 1 "Vehicle with el. load proportion" ;
VAL_ 2566833406 SpringBrakeEngaged 0 "Vehicle spring brake is released" 1 "Vehicle spring brake is engaged" ;
VAL_ 2566833406 LoadingRampApproachAssist 0 "Assistance not active" 1 "Assistance active" ;
VAL_ 2566833406 SupplyLineBrakingRequest 0 "No supply line braking request" 1 "Supply line braking request" ;
VAL_ 2365507326 TyrePressureSufficient 0 "Tyre pressure insufficient" 1 "Tyre pressure sufficient" ;
VAL_ 2365507326 BrakeLiningSufficient 0 "Brake linings insufficient" 1 "Brake linings sufficient" ;
VAL_ 2365507326 BrakeTemperatureStatus 0 "Brake temperature out of range" 1 "Brake temperature normal" ;
VAL_ 2365507326 VehiclePneumSupplySuff 0 "Pneumatic supply insufficient" 1 "Pneumatic supply sufficient" ;
VAL_ 2365507326 TyreWheelIdentLining1 0 "Wheel position not identified" 1 "Wheel position 1" 2 "Wheel position 2" 3 "Wheel position 3" 4 "Wheel position 4" 5 "Wheel position 5" 6 "Wheel position 6" 7 "Wheel position 7" 8 "Wheel position 8" 9 "Wheel position 9" 10 "Wheel position 10" 11 "Wheel position 11" 12 "Wheel position 12" 13 "Wheel position 13" 14 "Wheel position 14" 15 "Wheel position 15" ;
VAL_ 2365507326 TyreWheelIdentLining2 0 "Axle position not identified" 1 "Axle position 1" 2 "Axle position 2" 3 "Axle position 3" 4 "Axle position 4" 5 "Axle position 5" 6 "Axle position 6" 7 "Axle position 7" 8 "Axle position 8" 9 "Axle position 9" 10 "Axle position 10" 11 "Axle position 11" 12 "Axle position 12" 13 "Axle position 13" 14 "Axle position 14" 15 "Axle position 15" ;
VAL_ 2365507326 TyreWheelIdentPressure1 0 "Wheel position not identified" 1 "Wheel position 1" 2 "Wheel position 2" 3 "Wheel position 3" 4 "Wheel position 4" 5 "Wheel position 5" 6 "Wheel position 6" 7 "Wheel position 7" 8 "Wheel position 8" 9 "Wheel position 9" 10 "Wheel position 10" 11 "Wheel position 11" 12 "Wheel position 12" 13 "Wheel position 13" 14 "Wheel position 14" 15 "Wheel position 15" ;
VAL_ 2365507326 TyreWheelIdentPressure2 0 "Axle position not identified" 1 "Axle position 1" 2 "Axle position 2" 3 "Axle position 3" 4 "Axle position 4" 5 "Axle position 5" 6 "Axle position 6" 7 "Axle position 7" 8 "Axle position 8" 9 "Axle position 9" 10 "Axle position 10" 11 "Axle position 11" 12 "Axle position 12" 13 "Axle position 13" 14 "Axle position 14" 15 "Axle position 15" ;
VAL_ 2365507326 TyreWheelIdentTemp1 0 "Wheel position not identified" 1 "Wheel position 1" 2 "Wheel position 2" 3 "Wheel position 3" 4 "Wheel position 4" 5 "Wheel position 5" 6 "Wheel position 6" 7 "Wheel position 7" 8 "Wheel position 8" 9 "Wheel position 9" 10 "Wheel position 10" 11 "Wheel position 11" 12 "Wheel position 12" 13 "Wheel position 13" 14 "Wheel position 14" 15 "Wheel position 15" ;
VAL_ 2365507326 TyreWheelIdentTemp2 0 "Axle position not identified" 1 "Axle position 1" 2 "Axle position 2" 3 "Axle position 3" 4 "Axle position 4" 5 "Axle position 5" 6 "Axle position 6" 7 "Axle position 7" 8 "Axle position 8" 9 "Axle position 9" 10 "Axle position 10" 11 "Axle position 11" 12 "Axle position 12" 13 "Axle position 13" 14 "Axle position 14" 15 "Axle position 15" ;
VAL_ 2565013246 VehicleType 0 "Towing or towed vehicle" 1 "Dolly axle" ;
VAL_ 2565013246 AntiTheftDeviceReq 0 "Anti-theft device off" 1 "Anti-theft device on" 3 "Take no action" ;
VAL_ 2565013246 ODDRequest 0 "ODD off" 1 "ODD on" 3 "Take no action" ;
VAL_ 2365480958 EngineControlAllowed 0 "Engine control not allowed" 1 "Engine control allowed" ;
VAL_ 2365480958 EngineRunning 0 "Engine not running" 1 "Engine running" ;
VAL_ 2365480958 EngineTorqueMode 0 "Low idle governor/no request (de" 1 "Accelerator pedal/operator selec" 2 "Cruise control" 3 "PTO governor" 4 "Road speed governor" 5 "ASR control" 6 "Transmission control" 7 "ABS control" 8 "Torque limiting" 9 "High speed governor" 10 "Braking system" 11 "Remote accelerator" 15 "Not available" ;
VAL_ 2566808062 FirstClutchDpdtPTOFeedback 0 "Not engaged" 1 "Engaged" ;
VAL_ 2566808062 SecClutchDptdPTOFeedback 0 "Not engaged" 1 "Engaged" ;
VAL_ 2566808062 FirstEngineMtdPTOFeedback 0 "Limits not activated" 1 "Limits activated" ;
VAL_ 2566808062 SecEngineMtdPTOFeedback 0 "Limits not activated" 1 "Limits activated" ;
VAL_ 2566808062 PTOControlAllowed 0 "PTO control not allowed" 1 "PTO control allowed" ;
VAL_ 2566808062 TorqueConvtOilTempWarning 0 "No warning" 1 "Prewarning" 2 "Warning" ;
VAL_ 2566808062 StarterActive 0 "Starter not active" 1 "Starter active" ;
VAL_ 2566808062 AccelPedalLowIdleSwitch 0 "Not in low idle condition" 1 "In low idle condition" ;
VAL_ 2566808062 ClutchIndptdPTOFeedback 0 "Not engaged" 1 "Engaged" ;
VAL_ 2566808574 EngineCoolantTempWarning 0 "No warning" 1 "Prewarning" 2 "Warning" ;
VAL_ 2566808574 EngineOilPressureWarning 0 "No warning" 1 "Warning" ;
VAL_ 2566808574 FuelLevelWarning 0 "Fuel level warning off" 1 "Fuel level warning on" ;
VAL_ 2564947710 VehicleType 0 "Towing or towed vehicle" 1 "Dolly axle" ;
VAL_ 2566834430 ODDStatus 0 "ODD inactive" 1 "ODD active" ;
VAL_ 2566834430 AntiTheftDeviceStatus 0 "Anti-theft device off" 1 "Anti-theft device on" ;
VAL_ 2566808318 ClutchIndpdtPTOSwitch 0 "Switched off" 1 "Switched on" ;
VAL_ 2566808318 FirstEngineMtdPTOSwitch 0 "Switched off" 1 "Switched on" ;
VAL_ 2566808318 StarterLockoutSwitch 0 "Switched off" 1 "Switched on" ;
VAL_ 2566808318 EngineStartSwitch 0 "Switched off" 1 "Switched on" ;
VAL_ 2566808318 EngineStopSwitch 0 "Switched off" 1 "Switched on" ;
VAL_ 2566808318 RefusePackerStepSwitch 0 "Switched off" 1 "Switched on" ;
VAL_ 2566808318 OperatingPanelActive 0 "Operating panel not active" 1 "Operating panel active" ;
VAL_ 2566808318 FirstClutchDpdtPTOSwitch 0 "Switched off" 1 "Switched on" ;
VAL_ 2566808318 SecClutchDpdtPTOSwitch 0 "Switched off" 1 "Switched on" ;
VAL_ 2566808318 SecEngineMtdPTOSwitch 0 "Switched off" 1 "Switched on" ;
VAL_ 2566808830 TrailerLeftStopLight 0 "Lamp(s) not lit" 1 "Lamp(s) lit" ;
VAL_ 2566808830 TrailerRearWarningLight 0 "Lamp(s) not lit" 1 "Lamp(s) lit" ;
VAL_ 2566808830 TrailerRightCrnMarkerLight 0 "Lamp(s) not lit" 1 "Lamp(s) lit" ;
VAL_ 2566808830 TrailerRightDirIndLight 0 "Lamp(s) not lit" 1 "Lamp(s) lit" ;
VAL_ 2566808830 TrailerRightRearFogLight 0 "Lamp(s) not lit" 1 "Lamp(s) lit" ;
VAL_ 2566808830 TrailerRightRearLight 0 "Lamp(s) not lit" 1 "Lamp(s) lit" ;
VAL_ 2566808830 TrailerRightRearRegPltLight 0 "Lamp(s) not lit" 1 "Lamp(s) lit" ;
VAL_ 2566808830 TrailRightRearWidIndLight 0 "Lamp(s) not lit" 1 "Lamp(s) lit" ;
VAL_ 2566808830 TrailerRightReversingLight 0 "Lamp(s) not lit" 1 "Lamp(s) lit" ;
VAL_ 2566808830 TrailerRightSideMrkLight 0 "Lamp(s) not lit" 1 "Lamp(s) lit" ;
VAL_ 2566808830 TrailerRightStopLight 0 "Lamp(s) not lit" 1 "Lamp(s) lit" ;
VAL_ 2566808830 TrailerRotatingIdentLight 0 "Lamp(s) not lit" 1 "Lamp(s) lit" ;
VAL_ 2566808830 TrailerWorkLamp 0 "Lamp(s) not lit" 1 "Lamp(s) lit" ;
VAL_ 2566808830 TrailerInteriorLight 0 "Lamp(s) not lit" 1 "Lamp(s) lit" ;
VAL_ 2566808830 TrailerLeftCrnMarkerLight 0 "Lamp(s) not lit" 1 "Lamp(s) lit" ;
VAL_ 2566808830 TrailerLeftDirIndLight 0 "Lamp(s) not lit" 1 "Lamp(s) lit" ;
VAL_ 2566808830 TrailerLeftRearFogLight 0 "Lamp(s) not lit" 1 "Lamp(s) lit" ;
VAL_ 2566808830 TrailerLeftRearLight 0 "Lamp(s) not lit" 1 "Lamp(s) lit" ;
VAL_ 2566808830 TrailerLeftRearRegPltLight 0 "Lamp(s) not lit" 1 "Lamp(s) lit" ;
VAL_ 2566808830 TrailerLeftRearWidIndLight 0 "Lamp(s) not lit" 1 "Lamp(s) lit" ;
VAL_ 2566808830 TrailerLeftReversingLight 0 "Lamp(s) not lit" 1 "Lamp(s) lit" ;
VAL_ 2566808830 TrailerLeftSideMarkerLight 0 "Lamp(s) not lit" 1 "Lamp(s) lit" ;
VAL_ 2564554494 ProtocolCtrlInformation 0 "Single frame" 1 "First frame" 2 "Consecutive frame" 3 "Flow control " ;
VAL_ 2564554494 FlowStatus 0 "Continue To Send" 1 "Wait " 2 "Overflow" ;
VAL_ 2564488958 ProtocolCtrlInformation 0 "Single frame" 1 "First frame" 2 "Consecutive frame" 3 "Flow control " ;
VAL_ 2564488958 FlowStatus 0 "Continue To Send" 1 "Wait " 2 "Overflow" ;
VAL_ 2565734142 FilterMode 0 "BlockSpecificPGNs" 1 "PassSpecificPGNs" ;
VAL_ 2565734142 ControlByte 0 "MFDB_Request" 1 "MFDB_Response" 2 "MFDB_Add" 3 "MFDB_Delete" 4 "MFDB_Clear" 5 "MFDB_SetMode" 6 "MFDB_CreateEntry" ;
VAL_ 2565144318 RideHeightRequest 0 "Normal level 1" 1 "Normal level 2" 2 "Take no action" ;
VAL_ 2565144318 LevelChangeReqFrontAxle 0 "Vehicle body up (lifting)" 1 "Vehicle body down (lowering)" 2 "Take no action" ;
VAL_ 2565144318 LevelChangeReqRearAxle 0 "Vehicle body up (lifting)" 1 "Vehicle body down (lowering)" 2 "Take no action" ;
VAL_ 2565144318 TractionHelpReq 0 "No traction help request" 1 "Traction help request" 3 "Take no action" ;
VAL_ 2565144318 LiftAxle1PositionReq 0 "Position down / tag axle laden" 1 "Position up / tag axle unladen" 2 "Reserved" 3 "Don't care/take no action" ;
VAL_ 2565144318 LiftAxle2PositionReq 0 "Position down / tag axle laden" 1 "Position up / tag axle unladen" 3 "Take no action" ;
VAL_ 2565144318 SteeringAxleLockingReq 0 "Unlock steering axle" 1 "Lock steering axle" 3 "Take no action" ;
VAL_ 2565144318 RampLevelReq 0 "Ramp level 1" 1 "Ramp level 2" 3 "Take no action" ;
VAL_ 2565144318 LevelControlReq 0 "Disable level control" 1 "Enable level control" 3 "Take no action" ;
VAL_ 2565144318 RampLevelStorageReq 0 "Store ramp level 1" 1 "Store ramp level 2" 3 "Take no action" ;
VAL_ 2565144318 StopLevelChangeReq 0 "No stop request" 1 "Stop request" 3 "Take no action" ;
VAL_ 2565209854 LevelCtrlSysRideHeightLevel 0 "Vehicle body not at req. level" 1 "Vehicle body at requested level" ;
VAL_ 2565209854 TractionHelp 0 "Traction help inactive" 1 "Traction help active" ;
VAL_ 2565209854 RampLevelPosition 0 "Ramp level 1" 1 "Ramp level 2" 3 "Not available" ;
VAL_ 2565209854 LiftAxle1Pos 0 "Lift axle position down / tag axle laden" 1 "Lift axle position up / tag axle unladen" 2 "Error" 3 "Not available" ;
VAL_ 2565209854 LiftAxle2Pos 0 "Lift axle position down / tag axle laden" 1 "Lift axle position up / tag axle unladen" 2 "Error" 3 "Not available" ;
VAL_ 2565209854 SteeringAxleLocking 0 "Steering axle unlocked" 1 "Steering axle locked" ;
VAL_ 2565209854 RampLevelStorage 0 "No new storage request" 1 "New ramp level stored" ;
VAL_ 2565209854 LevelChangeFrontAxle 0 "Body lifting/lowering not active" 1 "Body lifting/lowering active" ;
VAL_ 2565209854 LevelChangeRearAxle 0 "Body lifting/lowering not active" 1 "Body lifting/lowering active" ;
VAL_ 2565209854 StopLevelChangeAcknowledge 0 "No stop request" 1 "Level change stopped" ;
VAL_ 2565209854 NormalLevel 0 "Normal level 1" 1 "Normal level 2" 3 "Not available" ;
VAL_ 2565209854 RampLevel 0 "Body not at requested ramp level" 1 "Body at requested ramp level" ;
VAL_ 2565209854 LevelControl 0 "Level control disabled" 1 "Level control enabled" ;
VAL_ 2566807294 TyreWheelIdentification1 0 "Wheel position not identified" 1 "Wheel position 1" 2 "Wheel position 2" 3 "Wheel position 3" 4 "Wheel position 4" 5 "Wheel position 5" 6 "Wheel position 6" 7 "Wheel position 7" 8 "Wheel position 8" 9 "Wheel position 9" 10 "Wheel position 10" 11 "Wheel position 11" 12 "Wheel position 12" 13 "Wheel position 13" 14 "Wheel position 14" 15 "Wheel position 15" ;
VAL_ 2566807294 TyreWheelIdentification2 0 "Axle position not identified" 1 "Axle position 1" 2 "Axle position 2" 3 "Axle position 3" 4 "Axle position 4" 5 "Axle position 5" 6 "Axle position 6" 7 "Axle position 7" 8 "Axle position 8" 9 "Axle position 9" 10 "Axle position 10" 11 "Axle position 11" 12 "Axle position 12" 13 "Axle position 13" 14 "Axle position 14" 15 "Axle position 15" ;
VAL_ 2566807294 TyreModulePowerSupply 0 "Insufficient power supply" 1 "Sufficient power supply" ;
VAL_ 2566807294 TyrePressThresholdDetect 0 "Extreme over pressure" 1 "Over pressure" 2 "No warning pressure" 3 "Under pressure" 4 "Extreme under pressure" 5 "Not defined" 6 "Error indicator" 7 "Not available" ;
VAL_ 2566764798 FuelSystemMonitoringComplete 0 "CompleteCycleOrNotSupported" 1 "NotCompleteCycle" ;
VAL_ 2566764798 ACSystemRefrigerantMonEnabled 0 "CompleteCycleOrNotSupported" 1 "NotCompleteCycle" ;
VAL_ 2566764798 ACSystemRefrigerantMonComplete 0 "CompleteCycleOrNotSupported" 1 "NotCompleteCycle" ;
VAL_ 2566764798 CatalystMonEnabled 0 "CompleteCycleOrNotSupported" 1 "NotCompleteCycle" ;
VAL_ 2566764798 CatalystMonComplete 0 "CompleteCycleOrNotSupported" 1 "NotCompleteCycle" ;
VAL_ 2566764798 ColdStartAidSystemMonEnabled 0 "DisabledForRestOfCycle" 1 "EnabledForCycle" ;
VAL_ 2566764798 ColdStartAidSystemMonComplete 0 "DisabledForRestOfCycle" 1 "EnabledForCycle" ;
VAL_ 2566764798 EGRSystemMonitoringEnabled 0 "DisabledForRestOfCycle" 1 "EnabledForCycle" ;
VAL_ 2566764798 EGRSystemMonitoringComplete 0 "CompleteCycleOrNotSupported" 1 "NotCompleteCycle" ;
VAL_ 2566764798 EvaporativeSystemMonEnabled 0 "CompleteCycleOrNotSupported" 1 "NotCompleteCycle" ;
VAL_ 2566764798 EvaporativeSystemMonComplete 0 "CompleteCycleOrNotSupported" 1 "NotCompleteCycle" ;
VAL_ 2566764798 HeatedCatalystMonEnabled 0 "DisabledForRestOfCycle" 1 "EnabledForCycle" ;
VAL_ 2566764798 HeatedCatalystMonComplete 0 "DisabledForRestOfCycle" 1 "EnabledForCycle" ;
VAL_ 2566764798 OxygenSensorHeaterMonEnabled 0 "CompleteCycleOrNotSupported" 1 "NotCompleteCycle" ;
VAL_ 2566764798 OxygenSensorHeaterMonComplete 0 "DisabledForRestOfCycle" 1 "EnabledForCycle" ;
VAL_ 2566764798 OxygenSensorMonEnabled 0 "CompleteCycleOrNotSupported" 1 "NotCompleteCycle" ;
VAL_ 2566764798 OxygenSensorMonComplete 0 "DisabledForRestOfCycle" 1 "EnabledForCycle" ;
VAL_ 2566764798 SecondAirSystemMonEnabled 0 "DisabledForRestOfCycle" 1 "EnabledForCycle" ;
VAL_ 2566764798 SecondAirSystemMonComplete 0 "DisabledForRestOfCycle" 1 "EnabledForCycle" ;
VAL_ 2566764798 ComprehensiveCompMonEnabled 0 "CompleteCycleOrNotSupported" 1 "NotCompleteCycle" ;
VAL_ 2566764798 ComprehensiveComptMonComplete 0 "CompleteCycleOrNotSupported" 1 "NotCompleteCycle" ;
VAL_ 2566764798 FuelSystemMonitoringEnabled 0 "CompleteCycleOrNotSupported" 1 "NotCompleteCycle" ;
VAL_ 2566764798 MisfireMonitoringEnabled 0 "DisabledForRestOfCycle" 1 "EnabledForCycle" ;
VAL_ 2566764798 MisfireMonitoringComplete 0 "DisabledForRestOfCycle" 1 "EnabledForCycle" ;
VAL_ 2564095742 SecurityEntityType 0 "Data is Long Seed" 1 "Data is Long Key" 2 "Data is Session Key" 3 "Data is Certificate" ;
VAL_ 2349075452 XBREBIMode 0 "No Endurance Brake Integration allowed" 1 "Only Endurance Brakes allowed" 2 "Endurance Brake Integration allowed" 3 "Not defined" ;
VAL_ 2349075452 XBRPriority 0 "Highest priority  used for emergency situations eg for future Collision Avoidance System This mode overrides" 1 "High priority  not defined" 2 "Medium priority  used for ACCSystems This mode does not override brake protection measures of the brake" 3 "Low priority  used in override disabled XBR Control Mode" ;
VAL_ 2349075452 XBRCtrlMode 0 "Override disabled  Disable any existing control commanded by the source of this command" 1 "Acceleration control with addition mode  Add the XBR acceleration demand to the drivers acceleration demand" 2 "Acceleration control with maximum mode  Execute the XBR acceleration demand if it is higher than the drivers" 3 "Not defined" ;
VAL_ 2566848510 WaterInFuelIndicator 0 "No" 1 "Yes" 2 "Error" 3 "Not available" ;
VAL_ 2566843134 AxleLocation 0 "Axle0_Position0" 16 "Axle1_Position0" 32 "Axle2_Position0" 48 "Axle3_Position0" ;
VAL_ 2566809854 HydOilFilterRestrictionSwitch 0 "No restriction" 1 "Restriction exists on oil filter" 2 "Error" 3 "Not Available" ;
VAL_ 2566809854 WinchOilPressSwitch 0 "NOT OK Oil pressure is too low" 1 "OK  Oil pressure is above minimum" 2 "Error  Switch state cannot be determined" 3 "Not Available" ;
VAL_ 2565867787 SteerWheelAngleSensorType 0 "Relative measuring principle" 1 "Absolute measuring principle" 2 "Reserved" 3 "Not Available" ;
VAL_ 2566803211 VDCInformationSignal 0 "Off" 1 "On" 2 "Reserved" 3 "Dont care/Take no action" ;
VAL_ 2566803211 VDCFullyOperational 0 "Not fully operational" 1 "Fully operational" 2 "Reserved" 3 "Dont care/Take no action" ;
VAL_ 2566803211 VDCBrakeLightRq 0 "Turn brake light not on" 1 "Turn brake light on" 2 "Reserved" 3 "Dont care/Take no action" ;
VAL_ 2566803211 ROPEngCtrlActive 0 "ROP engine control passive but installed" 1 "ROP engine control active" 2 "Reserved" 3 "Dont care/Take no action" ;
VAL_ 2566803211 ROPBrakeCtrlActive 0 "ROP brake control passive but installed" 1 "ROP brake control active" 2 "Reserved" 3 "Dont care/Take no action" ;
VAL_ 2566803211 YCEngCtrlActive 0 "YC engine control passive but installed" 1 "YC engine control active" 2 "Reserved" 3 "Dont care/Take no action" ;
VAL_ 2566803211 YCBrakeCtrlActive 0 "YC brake control passive but installed" 1 "YC brake control active" 2 "Reserved" 3 "Dont care/Take no action" ;
VAL_ 2348810243 EngOverrideCtrlMode 0 "Override disabled  Disable any existing control commanded by the source of this command" 1 "Speed control  Govern speed to the included desired speed value" 2 "Torque control  Control torque to the included desired torque value" 3 "Speed/torque limit control  Limit speed and/or torque based on the included limit values The speed limit governor is" ;
VAL_ 2348810243 EngRequestedSpeedCtrlConditions 0 "Transient Optimized for driveline disengaged and nonlockup conditions" 1 "Stability Optimized for driveline disengaged and nonlockup conditions" 3 "Stability Optimized for driveline engaged and/or in lockup condition 2 eg PTO driveline" 2 "Stability Optimized for driveline engaged and/or in lockup condition 1 eg vehicle driveline" ;
VAL_ 2348810243 OverrideCtrlModePriority 0 "Highest priority" 1 "High priority" 2 "Medium priority" 3 "Low priority" ;
VAL_ 2348810243 TSC1TransRate 0 "1000 ms transmission rate" 1 "750 ms transmission rate" 2 "500 ms transmission rate" 3 "250 ms transmission rate" 4 "100 ms transmission rate" 5 "50 ms transmission rate" 6 "20 ms transmission rate" 7 "Use standard TSC1 transmission rates of 10 ms to engine" ;
VAL_ 2348810243 TSC1CtrlPurpose 0 "P1  Accelerator Pedal/Operator Selection" 1 "P2  Cruise Control" 2 "P3  PTO Governor" 3 "P4  Road Speed Governor" 4 "P5  Engine Protection" 5 "11110  P6P31  Reserved for SAE Assignment" 31 "P32  Temporary Power Train Control Original use of TSC1 Command" ;
VAL_ 2348810243 EngRequestedTrq_Fractional 8 "1111  not available" 0 "0000" 1 "0125" 7 "0875" ;
VAL_ 2566766846 SilentAlarmStatus 0 "Off" 1 "On" 2 "Error condition" 3 "Not available" ;
VAL_ 2566766846 VehicleUseStatus 0 "Normal use" 1 "Unauthorized use" 2 "Error condition" 3 "Not available" ;
VAL_ 2566766846 TransitRunStatus 0 "Off" 2 "Error condition" 3 "Not available" ;
VAL_ 2566765310 FareboxEmergencyStatus 0 "Nonemergency condition" 1 "Emergency condition" 2 "Error Condition" 3 "Not available" ;
VAL_ 2566765310 FareboxAlarmIdentifier 0 "Voltage dropout" 1 "Voltage restored" 2 "Probe started" 3 "Probe completed" 4 "Cashbox removed" 5 "Cashbox restored" 6 "Cashbox door timeout" 7 "Cashbox opened in service considered an alarm condition" 8 "Insufficient fare accepted" 9 "Coinbox 75 full" 10 "Coinbox full" 11 "Currency box 75 full" 12 "Currency box less than 75 full" 13 "Currency box full" 14 "Card/pass box 75 full" 15 "Card/pass box less than 75 full" 16 "Card/pass box full" 17 "Coin dejam operated" 18 "Farebox set in manual bypass" 19 "Farebox reset to automatic mode" 20 "Pass/transfer jam" 21 "Pass/transfer jam cleared" 22 "Paper currency jam" 23 "Paper currency jam cleared" 24 "Maintenance access in service considered an alarm condition" 25 "Maintenance access out of service" ;
VAL_ 2566765566 TransactionType 0 "Cash" 1 "Token" 2 "Ticket" 3 "Pass" 4 "Card" 5 "Permit" 6 "Transfer" 7 "Free" ;
VAL_ 2566765566 TypeOfFare 0 "Cash/No detail" 1 "Token A" 2 "Token B" 3 "Ticket A" 4 "Ticket B" 5 "Pass A" 6 "Pass B" ;
VAL_ 2566765566 PaymentDetails 0 "Not an upgrade" 1 "Cash" 2 "Token" 3 "Ticket" 4 "Pass" 5 "Card" ;
VAL_ 2566765566 TypeOfService 0 "Local service" 1 "Express service" ;
VAL_ 2566765566 TransferType 0 "North" 1 "South" 2 "East" 3 "West" 4 "In" 5 "Out" ;
VAL_ 2566766078 RangeCodeEnable 0 "Range code not used for interleaved data" 1 "Range code used for interleaved data" 2 "Error condition" 3 "Not available" ;
VAL_ 2566766078 TransitRouteIDUsage 0 "Transit route ID not used for interleaved data" 1 "Transit route ID used for interleaved data if range code not enabled" 2 "Error condition" 3 "Not available" ;
VAL_ 2566766078 IntrsctnPrmptionRequest_Response 0 "Message is a request directed to the emitter" 1 "Message is a response from the emitter" 2 "Error condition" 3 "Not available" ;
VAL_ 2566766078 PriorityOfRespSentByEmitter 0 "Reserved" 1 "Low priority" 2 "Probe priority" 3 "High priority" 4 "to 1000  Reserved" 9 "Priority set by hardware to low priority" 10 "Priority set by hardware to probe priority" 11 "Priority set by hardware to high priority" 12 "to 1101  Reserved" 14 "Error condition" 15 "Not available" ;
VAL_ 2566766078 TransitDoorEnable 0 "Ignore transit door status" 1 "Transit door status will override strobe activation" 2 "Error condition" 3 "Not available" ;
VAL_ 2566766078 StrobeActivationCtrlStatus 0 "Deactivate strobe" 1 "Activate strobe" 2 "Error condition" 3 "Not available" ;
VAL_ 2561605374 TireLocation 0 "Axle0_Position0" 16 "Axle1_Position0" 32 "Axle2_Position0" 48 "Axle3_Position0" 1 "Axle0_Position1" 17 "Axle1_Position1" 18 "Axle1_Position2" 19 "Axle1_Position3" 33 "Axle2_Position1" 34 "Axle2_Position2" 35 "Axle2_Position3" 49 "Axle3_Position1" 50 "Axle3_Position2" 51 "Axle3_Position3" ;
VAL_ 2566765054 TireLocation 0 "Axle0_Position0" 16 "Axle1_Position0" 32 "Axle2_Position0" 48 "Axle3_Position0" 1 "Axle0_Position1" 17 "Axle1_Position1" 18 "Axle1_Position2" 19 "Axle1_Position3" 33 "Axle2_Position1" 34 "Axle2_Position2" 35 "Axle2_Position3" 49 "Axle3_Position1" 50 "Axle3_Position2" 51 "Axle3_Position3" ;
VAL_ 2633922814 SteerChannelMode 0 "Maintain" 1 "Inflate" 2 "Deflate" 3 "Confirm" 4 "Inflate Wait  System will inflate when conditions allow" 5 "Deflate Wait  System will deflate when conditions allow" 6 "Pressure Check" 14 "Error Condition" 15 "Not available" ;
VAL_ 2633922814 Trailer_tagChannelMode 0 "Maintain" 1 "Inflate" 2 "Deflate" 3 "Confirm" 4 "Inflate Wait  System will inflate when conditions allow" 5 "Deflate Wait  System will deflate when conditions allow" 6 "Pressure Check" 14 "Error Condition" 15 "Not available" ;
VAL_ 2633922814 DriveChannelMode 0 "Maintain" 1 "Inflate" 2 "Deflate" 3 "Confirm" 4 "Inflate Wait  System will inflate when conditions allow" 5 "Deflate Wait  System will deflate when conditions allow" 6 "Pressure Check" 14 "Error Condition" 15 "Not available" ;
VAL_ 2633922814 PCUDriveSolenoidStatus 0 "Off" 1 "On" 2 "Error" 3 "Not available" ;
VAL_ 2633922814 PCUSteerSolenoidStatus 0 "Off" 1 "On" 2 "Error" 3 "Not available" ;
VAL_ 2633922814 TirePressSupplySwitchStatus 0 "Off" 1 "On" 2 "Error" 3 "Not available" ;
VAL_ 2633922814 PCUDeflateSolenoidStatus 0 "Off" 1 "On" 2 "Error" 3 "Not available" ;
VAL_ 2633922814 PCUCtrlSolenoidStatus 0 "Off" 1 "On" 2 "Error" 3 "Not available" ;
VAL_ 2633922814 PCUSupplySolenoidStatus 0 "Off" 1 "On" 2 "Error" 3 "Not available" ;
VAL_ 2633922814 PCUTrilerTagOrPushSolenoidStatus 0 "Off" 1 "On" 2 "Error" 3 "Not available" ;
VAL_ 2566845491 TireStatus 0 "Ok" 1 "TireLeakDetected" 2 "Error" 3 "NotSupported" ;
VAL_ 2566845491 TireSensorElectricalFault 0 "Ok" 1 "NotDefined" 2 "Error" 3 "NotSupported" ;
VAL_ 2566845491 TireSensorEnStatus 0 "Off_IsolatedFromCTIPressCtrl" 1 "On" 2 "NotDefined" 3 "NotSupported" ;
VAL_ 2566845491 TirePressThresholdDetection 0 "ExtrmOvrPrssTrPrssrIsAtALvlWhrT" 1 "OvrPrssTrPrssrIsHghrThnThPrssrD" 2 "NWrnngPrssTrPrssrIsWthnThThrshl" 3 "UndrPrssTrPrssrIsLwrThnThPrssrD" 4 "ExtrmUndrPrssTrPrssrIsAtALvlWhr" 5 "NotDefined" 6 "ErrorIndicator" 7 "NotAvailable" ;
VAL_ 2566821630 EngTrbWstgateActuator1TempStatus 0 "High Most severe" 1 "High Least severe" 2 "In Range" 3 "Low Least severe" 4 "Low Most severe" 5 "Not Defined" 6 "Error" 7 "Not available" ;
VAL_ 2365484286 Driver1WorkingState 0 "Rest  sleeping" 1 "Driver available  short break" 2 "Work  loading unloading working in an office" 3 "Drive  behind wheel" 6 "Error" 7 "Not available" ;
VAL_ 2365484286 Driver2WorkingState 0 "Rest  sleeping" 1 "Driver available  short break" 2 "Work  loading unloading working in an office" 3 "Drive  behind wheel" 6 "Error" 7 "Not available" ;
VAL_ 2365484286 Driver1TimeRelatedStates 0 "Normal/No limits reached" 1 "Limit 1  15 min before 4  h" 2 "Limit 2  4  h reached" 3 "Limit 3  15 min before 9 h" 4 "Limit 4  9 h reached" 5 "Limit 5  15 min before 16 h not having 8h rest during the last 24h" 6 "Limit 6  16 h reached" 13 "Other" 14 "Error" 15 "Not available" ;
VAL_ 2365484286 DriverCardDriver1 0 "Driver card not present" 1 "Driver card present" 2 "Error" 3 "Not available" ;
VAL_ 2365484286 Driver2TimeRelatedStates 0 "Normal/No limits reached" 1 "Limit 1  15 min before 4  h" 2 "Limit 2  4  h reached" 3 "Limit 3  15 min before 9 h" 4 "Limit 4  9 h reached" 5 "Limit 5  15 min before 16 h not having 8h rest during the last 24h" 6 "Limit 6  16 h reached" 13 "Other" 14 "Error" 15 "Not available" ;
VAL_ 2365484286 DriverCardDriver2 0 "Driver card not present" 1 "Driver card present" 2 "Error" 3 "Not available" ;
VAL_ 2365484286 SystemEvent 0 "No tachograph event" 1 "Tachograph event" 2 "Error" 3 "Not available" ;
VAL_ 2365484286 HandlingInformation 0 "No handling information" 1 "Handling information" 2 "Error" 3 "Not available" ;
VAL_ 2365484286 TachographPerformance 0 "Normal performance" 1 "Performance analysis" 2 "Error" 3 "Not available" ;
VAL_ 2365484286 DirectionIndicator 0 "Forward" 1 "Reverse" 2 "Error" 3 "Not available" ;
VAL_ 2365484286 VehicleMotion 0 "Vehicle motion not detected" 1 "Vehicle motion detected" 2 "Error" 3 "Not available" ;
VAL_ 2365484286 VehicleOverspeed 0 "No overspeed" 1 "Overspeed" 2 "Error" 3 "Not available" ;
